// *************************************************************************** *
// *                                                                           *
// * Description:         CANDB File                                           *
// * Generated at:        2023-01-05 13:51                                     *
// * System:              FLRsystem_MAIN_26                                    *
// * Network:             FLR1CAN                                              *
// *                                                                           *
// *************************************************************************** *
VERSION "FLR1CAN"

NS_ :

BS_ :

BU_ :  FLR FLRdpHPA FLRdpHPB

BO_ 1794 Flr1canTimeSyncFr01 : 8 FLRdpHPA

BO_ 512 FlrdpFlr1canFr02 : 48 FLRdpHPA
 SG_ VehicleMotionState_UB : 280|1@0+ (1,0) [0|1] "" FLR
 SG_ VehicleMotionStateAcceleroMeterLateral : 24|15@1+ (0.0085,-138.992) [-138.992|139.00050000000002] "m/s^2" FLR
 SG_ VehicleMotionStateAccelerometerLateralQuality : 232|3@1+ (1,0) [0|7] "" FLR
 SG_ VehicleMotionStateAccelerometerLongitudinal : 40|15@1+ (0.0085,-138.992) [-138.992|139.00050000000002] "m/s^2" FLR
 SG_ VehicleMotionStateAccelerometerLongitudinalQuality : 235|3@1+ (1,0) [0|7] "" FLR
 SG_ VehicleMotionStateAccelerometerVertical : 56|15@1+ (0.0085,-138.992) [-138.992|139.00050000000002] "m/s^2" FLR
 SG_ VehicleMotionStateAccelerometerVerticalQuality : 240|3@1+ (1,0) [0|7] "" FLR
 SG_ VehicleMotionStateAngularVelocityRoll : 72|16@1+ (0.000159791,-5.236031488) [-5.236031488|5.235871697] "rad/s" FLR
 SG_ VehicleMotionStateAngularVelocityRollQuality : 243|3@1+ (1,0) [0|7] "" FLR
 SG_ VehicleMotionStateAngularVelocityYaw : 104|16@1+ (0.000159791,-5.236031488) [-5.236031488|5.235871697] "rad/s" FLR
 SG_ VehicleMotionStateAngularVelocityYawQuality : 248|3@1+ (1,0) [0|7] "" FLR
 SG_ VehicleMotionStateCounter : 16|8@1+ (1.0,0.0) [0.0|255.0] "Unitless" FLR
 SG_ VehicleMotionStateCRC : 0|16@1+ (1.0,0.0) [0.0|65535.0] "Unitless" FLR
 SG_ VehicleMotionStateMovingDirection : 251|3@1+ (1,0) [0|7] "" FLR
 SG_ VehicleMotionStateMovingDirectionQuality : 256|3@1+ (1,0) [0|7] "" FLR
 SG_ VehicleMotionStateVelocityLongitudinal : 152|13@1- (0.02,0.0) [-81.9|81.9] "m/s" FLR
 SG_ VehicleMotionStateVelocityLongitudinalQuality : 128|3@1+ (1,0) [0|7] "" FLR
 SG_ VehicleMotionStateWheelAngle : 136|15@1+ (0.00005249,-0.85) [-0.85|0.8500461200000001] "rad" FLR
 SG_ VehicleMotionStateWheelAngleQuality : 131|3@1+ (1,0) [0|7] "" FLR
 SG_ VehicleMotionStateWheelAngularVelocityFrontLeft : 168|16@1+ (0.0078125,-255.0) [-255.0|255.0] "rad/s" FLR
 SG_ VehicleMotionStateWheelAngularVelocityFrontLeftQuality : 264|3@1+ (1,0) [0|7] "" FLR
 SG_ VehicleMotionStateWheelAngularVelocityFrontRight : 184|16@1+ (0.0078125,-255.0) [-255.0|255.0] "rad/s" FLR
 SG_ VehicleMotionStateWheelAngularVelocityFrontRightQuality : 267|3@1+ (1,0) [0|7] "" FLR
 SG_ VehicleMotionStateWheelAngularVelocityRearLeft : 200|16@1+ (0.0078125,-255.0) [-255.0|255.0] "rad/s" FLR
 SG_ VehicleMotionStateWheelAngularVelocityRearLeftQuality : 272|3@1+ (1,0) [0|7] "" FLR
 SG_ VehicleMotionStateWheelAngularVelocityRearRight : 216|16@1+ (0.0078125,-255.0) [-255.0|255.0] "rad/s" FLR
 SG_ VehicleMotionStateWheelAngularVelocityRearRightQuality : 275|3@1+ (1,0) [0|7] "" FLR

BO_ 528 FlrdpFlr1canFr03 : 12 FLRdpHPA
 SG_ CarConfig_UB : 72|1@0+ (1,0) [0|1] "" FLR
 SG_ CarConfigCounter : 16|8@1+ (1.0,0.0) [0.0|255.0] "Unitless" FLR
 SG_ CarConfigCRC : 0|16@1+ (1.0,0.0) [0.0|65535.0] "Unitless" FLR
 SG_ CarConfigPropulsionType : 24|2@1+ (1,0) [0|3] "" FLR
 SG_ CarConfigVehicleTyp : 27|8@1+ (1,0) [0|255] "" FLR
 SG_ PowerModeFLR_UB : 73|1@0+ (1,0) [0|1] "" FLR
 SG_ PowerModeFLRCounter : 56|8@1+ (1.0,0.0) [0.0|255.0] "Unitless" FLR
 SG_ PowerModeFLRCRC : 40|16@1+ (1.0,0.0) [0.0|65535.0] "Unitless" FLR
 SG_ PowerModeFLRRdrActvnReq : 64|1@1+ (1,0) [0|1] "" FLR
 SG_ PowerModeFLRRdrPwrlossNoti : 65|1@1+ (1,0) [0|1] "" FLR

BO_ 544 FlrdpFlr1canFr04 : 32 FLRdpHPA
 SG_ GlobalSnapShotRdr_UB : 128|1@0+ (1,0) [0|1] "" FLR
 SG_ GlobalSnapShotRdrCounter : 16|8@1+ (1.0,0.0) [0.0|255.0] "Unitless" FLR
 SG_ GlobalSnapShotRdrCRC : 0|16@1+ (1.0,0.0) [0.0|65535.0] "Unitless" FLR
 SG_ GlobalSnapShotRdrGlobalRealTimeRdr : 24|32@1+ (1.0,0.0) [0.0|4294967295.0] "s" FLR
 SG_ GlobalSnapShotRdrOutsideTemperatureRdr : 56|16@1- (0.1,0.0) [-3276.8|3276.7000000000003] "degC" FLR
 SG_ GlobalSnapShotRdrTotalDistanceRdr : 72|32@1+ (1.0,0.0) [0.0|4294967295.0] "km" FLR
 SG_ GlobalSnapShotRdrUsageModeRdr : 104|8@1+ (1.0,0.0) [0.0|255.0] "Unitless" FLR
 SG_ GlobalSnapShotRdrVehicleBatteryVoltageRdr : 112|8@1+ (0.25,0.0) [0.0|63.75] "Volt" FLR
 SG_ GlobalSnapShotRdrVehicleSpeedRdr : 120|8@1+ (1.0,0.0) [0.0|255.0] "Km/h" FLR

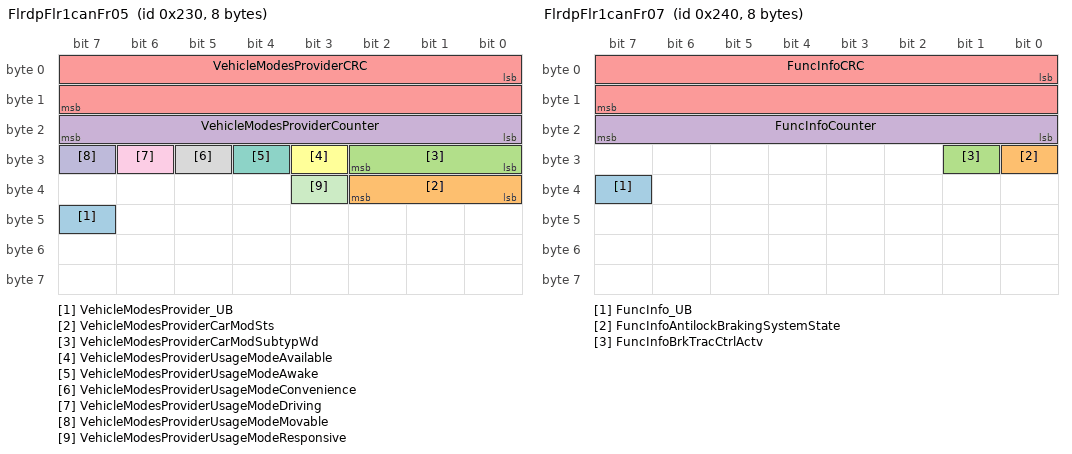
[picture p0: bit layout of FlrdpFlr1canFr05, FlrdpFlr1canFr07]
BO_ 560 FlrdpFlr1canFr05 : 8 FLRdpHPA
 SG_ VehicleModesProvider_UB : 47|1@0+ (1,0) [0|1] "" FLR
 SG_ VehicleModesProviderCarModSts : 32|3@1+ (1,0) [0|7] "" FLR
 SG_ VehicleModesProviderCarModSubtypWd : 24|3@1+ (1,0) [0|7] "" FLR
 SG_ VehicleModesProviderCounter : 16|8@1+ (1.0,0.0) [0.0|255.0] "Unitless" FLR
 SG_ VehicleModesProviderCRC : 0|16@1+ (1.0,0.0) [0.0|65535.0] "Unitless" FLR
 SG_ VehicleModesProviderUsageModeAvailable : 27|1@1+ (1,0) [0|1] "" FLR
 SG_ VehicleModesProviderUsageModeAwake : 28|1@1+ (1,0) [0|1] "" FLR
 SG_ VehicleModesProviderUsageModeConvenience : 29|1@1+ (1,0) [0|1] "" FLR
 SG_ VehicleModesProviderUsageModeDriving : 30|1@1+ (1,0) [0|1] "" FLR
 SG_ VehicleModesProviderUsageModeMovable : 31|1@1+ (1,0) [0|1] "" FLR
 SG_ VehicleModesProviderUsageModeResponsive : 35|1@1+ (1,0) [0|1] "" FLR

BO_ 576 FlrdpFlr1canFr07 : 8 FLRdpHPA
 SG_ FuncInfo_UB : 39|1@0+ (1,0) [0|1] "" FLR
 SG_ FuncInfoAntilockBrakingSystemState : 24|1@1+ (1,0) [0|1] "" FLR
 SG_ FuncInfoBrkTracCtrlActv : 25|1@1+ (1,0) [0|1] "" FLR
 SG_ FuncInfoCounter : 16|8@1+ (1.0,0.0) [0.0|255.0] "Unitless" FLR
 SG_ FuncInfoCRC : 0|16@1+ (1.0,0.0) [0.0|65535.0] "Unitless" FLR

BO_ 2047 FlrdpToAllUdsDiagRequestFrame : 64 FLRdpHPA
 SG_ FlrdpToAllUdsFlrCanNPdu : 7|512@0+ (1,0) [0|0] "" FLR

BO_ 1873 FlrdpToFlrUdsDiagRequestFrame : 64 FLRdpHPA
 SG_ FlrdpToFlrUdsFlrCanNPdu : 7|512@0+ (1,0) [0|0] "" FLR

BO_ 80 FlrFlr1canFr01 : 64 FLR
 SG_ FLR2RdrDetn000To004_UB : 359|1@0+ (1,0) [0|1] "" FLRdpHPA,FLRdpHPB
 SG_ FLR2RdrDetn000To004AziAng0 : 32|9@1+ (0.0035,-0.87266) [-0.87266|0.91584] "rad" FLRdpHPA,FLRdpHPB
 SG_ FLR2RdrDetn000To004AziAng1 : 96|9@1+ (0.0035,-0.87266) [-0.87266|0.91584] "rad" FLRdpHPA,FLRdpHPB
 SG_ FLR2RdrDetn000To004AziAng2 : 160|9@1+ (0.0035,-0.87266) [-0.87266|0.91584] "rad" FLRdpHPA,FLRdpHPB
 SG_ FLR2RdrDetn000To004AziAng3 : 224|9@1+ (0.0035,-0.87266) [-0.87266|0.91584] "rad" FLRdpHPA,FLRdpHPB
 SG_ FLR2RdrDetn000To004AziAng4 : 288|9@1+ (0.0035,-0.87266) [-0.87266|0.91584] "rad" FLRdpHPA,FLRdpHPB
 SG_ FLR2RdrDetn000To004Counter : 16|8@1+ (1.0,0.0) [0.0|255.0] "Unitless" FLRdpHPA,FLRdpHPB
 SG_ FLR2RdrDetn000To004CRC : 0|16@1+ (1.0,0.0) [0.0|65535.0] "Unitless" FLRdpHPA,FLRdpHPB
 SG_ FLR2RdrDetn000To004DynPrpty0 : 93|1@1+ (1.0,0.0) [0.0|1.0] "Unitless" FLRdpHPA,FLRdpHPB
 SG_ FLR2RdrDetn000To004DynPrpty1 : 157|1@1+ (1.0,0.0) [0.0|1.0] "Unitless" FLRdpHPA,FLRdpHPB
 SG_ FLR2RdrDetn000To004DynPrpty2 : 221|1@1+ (1.0,0.0) [0.0|1.0] "Unitless" FLRdpHPA,FLRdpHPB
 SG_ FLR2RdrDetn000To004DynPrpty3 : 285|1@1+ (1.0,0.0) [0.0|1.0] "Unitless" FLRdpHPA,FLRdpHPB
 SG_ FLR2RdrDetn000To004DynPrpty4 : 349|1@1+ (1.0,0.0) [0.0|1.0] "Unitless" FLRdpHPA,FLRdpHPB
 SG_ FLR2RdrDetn000To004EleAng0 : 64|8@1+ (0.002,0.0) [0.0|0.5] "rad" FLRdpHPA,FLRdpHPB
 SG_ FLR2RdrDetn000To004EleAng1 : 128|8@1+ (0.002,0.0) [0.0|0.5] "rad" FLRdpHPA,FLRdpHPB
 SG_ FLR2RdrDetn000To004EleAng2 : 192|8@1+ (0.002,0.0) [0.0|0.5] "rad" FLRdpHPA,FLRdpHPB
 SG_ FLR2RdrDetn000To004EleAng3 : 256|8@1+ (0.002,0.0) [0.0|0.5] "rad" FLRdpHPA,FLRdpHPB
 SG_ FLR2RdrDetn000To004EleAng4 : 320|8@1+ (0.002,0.0) [0.0|0.5] "rad" FLRdpHPA,FLRdpHPB
 SG_ FLR2RdrDetn000To004Mode0 : 60|2@1+ (1,0) [0|3] "" FLRdpHPA,FLRdpHPB
 SG_ FLR2RdrDetn000To004Mode1 : 124|2@1+ (1,0) [0|3] "" FLRdpHPA,FLRdpHPB
 SG_ FLR2RdrDetn000To004Mode2 : 188|2@1+ (1,0) [0|3] "" FLRdpHPA,FLRdpHPB
 SG_ FLR2RdrDetn000To004Mode3 : 252|2@1+ (1,0) [0|3] "" FLRdpHPA,FLRdpHPB
 SG_ FLR2RdrDetn000To004Mode4 : 316|2@1+ (1,0) [0|3] "" FLRdpHPA,FLRdpHPB
 SG_ FLR2RdrDetn000To004Quality0 : 62|2@1+ (1,0) [0|3] "" FLRdpHPA,FLRdpHPB
 SG_ FLR2RdrDetn000To004Quality1 : 126|2@1+ (1,0) [0|3] "" FLRdpHPA,FLRdpHPB
 SG_ FLR2RdrDetn000To004Quality2 : 190|2@1+ (1,0) [0|3] "" FLRdpHPA,FLRdpHPB
 SG_ FLR2RdrDetn000To004Quality3 : 254|2@1+ (1,0) [0|3] "" FLRdpHPA,FLRdpHPB
 SG_ FLR2RdrDetn000To004Quality4 : 318|2@1+ (1,0) [0|3] "" FLRdpHPA,FLRdpHPB
 SG_ FLR2RdrDetn000To004Range0 : 48|12@1+ (0.1,0.4) [0.4|300.0] "m" FLRdpHPA,FLRdpHPB
 SG_ FLR2RdrDetn000To004Range1 : 112|12@1+ (0.1,0.4) [0.4|300.0] "m" FLRdpHPA,FLRdpHPB
 SG_ FLR2RdrDetn000To004Range2 : 176|12@1+ (0.1,0.4) [0.4|300.0] "m" FLRdpHPA,FLRdpHPB
 SG_ FLR2RdrDetn000To004Range3 : 240|12@1+ (0.1,0.4) [0.4|300.0] "m" FLRdpHPA,FLRdpHPB
 SG_ FLR2RdrDetn000To004Range4 : 304|12@1+ (0.1,0.4) [0.4|300.0] "m" FLRdpHPA,FLRdpHPB
 SG_ FLR2RdrDetn000To004RCS0 : 83|10@1+ (0.2,-100.0) [-100.0|70.0] "dBsm" FLRdpHPA,FLRdpHPB
 SG_ FLR2RdrDetn000To004RCS1 : 147|10@1+ (0.2,-100.0) [-100.0|70.0] "dBsm" FLRdpHPA,FLRdpHPB
 SG_ FLR2RdrDetn000To004RCS2 : 211|10@1+ (0.2,-100.0) [-100.0|70.0] "dBsm" FLRdpHPA,FLRdpHPB
 SG_ FLR2RdrDetn000To004RCS3 : 275|10@1+ (0.2,-100.0) [-100.0|70.0] "dBsm" FLRdpHPA,FLRdpHPB
 SG_ FLR2RdrDetn000To004RCS4 : 339|10@1+ (0.2,-100.0) [-100.0|70.0] "dBsm" FLRdpHPA,FLRdpHPB
 SG_ FLR2RdrDetn000To004RngRt0 : 72|11@1+ (0.1,-111.11) [-111.11|55.59000000000002] "m/s" FLRdpHPA,FLRdpHPB
 SG_ FLR2RdrDetn000To004RngRt1 : 136|11@1+ (0.1,-111.11) [-111.11|55.59000000000002] "m/s" FLRdpHPA,FLRdpHPB
 SG_ FLR2RdrDetn000To004RngRt2 : 200|11@1+ (0.1,-111.11) [-111.11|55.59000000000002] "m/s" FLRdpHPA,FLRdpHPB
 SG_ FLR2RdrDetn000To004RngRt3 : 264|11@1+ (0.1,-111.11) [-111.11|55.59000000000002] "m/s" FLRdpHPA,FLRdpHPB
 SG_ FLR2RdrDetn000To004RngRt4 : 328|11@1+ (0.1,-111.11) [-111.11|55.59000000000002] "m/s" FLRdpHPA,FLRdpHPB
 SG_ FLR2RdrDetn000To004ScanID : 24|8@1+ (1.0,0.0) [0.0|255.0] "Unitless" FLRdpHPA,FLRdpHPB
 SG_ FLR2RdrDetn000To004SNR0 : 41|7@1+ (0.5,0.0) [0.0|63.5] "dB" FLRdpHPA,FLRdpHPB
 SG_ FLR2RdrDetn000To004SNR1 : 105|7@1+ (0.5,0.0) [0.0|63.5] "dB" FLRdpHPA,FLRdpHPB
 SG_ FLR2RdrDetn000To004SNR2 : 169|7@1+ (0.5,0.0) [0.0|63.5] "dB" FLRdpHPA,FLRdpHPB
 SG_ FLR2RdrDetn000To004SNR3 : 233|7@1+ (0.5,0.0) [0.0|63.5] "dB" FLRdpHPA,FLRdpHPB
 SG_ FLR2RdrDetn000To004SNR4 : 297|7@1+ (0.5,0.0) [0.0|63.5] "dB" FLRdpHPA,FLRdpHPB

BO_ 83 FlrFlr1canFr02 : 64 FLR
 SG_ FLR2RdrDetn005To009_UB : 359|1@0+ (1,0) [0|1] "" FLRdpHPA,FLRdpHPB
 SG_ FLR2RdrDetn005To009AziAng0 : 32|9@1+ (0.0035,-0.87266) [-0.87266|0.91584] "rad" FLRdpHPA,FLRdpHPB
 SG_ FLR2RdrDetn005To009AziAng1 : 96|9@1+ (0.0035,-0.87266) [-0.87266|0.91584] "rad" FLRdpHPA,FLRdpHPB
 SG_ FLR2RdrDetn005To009AziAng2 : 160|9@1+ (0.0035,-0.87266) [-0.87266|0.91584] "rad" FLRdpHPA,FLRdpHPB
 SG_ FLR2RdrDetn005To009AziAng3 : 224|9@1+ (0.0035,-0.87266) [-0.87266|0.91584] "rad" FLRdpHPA,FLRdpHPB
 SG_ FLR2RdrDetn005To009AziAng4 : 288|9@1+ (0.0035,-0.87266) [-0.87266|0.91584] "rad" FLRdpHPA,FLRdpHPB
 SG_ FLR2RdrDetn005To009Counter : 16|8@1+ (1.0,0.0) [0.0|255.0] "Unitless" FLRdpHPA,FLRdpHPB
 SG_ FLR2RdrDetn005To009CRC : 0|16@1+ (1.0,0.0) [0.0|65535.0] "Unitless" FLRdpHPA,FLRdpHPB
 SG_ FLR2RdrDetn005To009DynPrpty0 : 93|1@1+ (1.0,0.0) [0.0|1.0] "Unitless" FLRdpHPA,FLRdpHPB
 SG_ FLR2RdrDetn005To009DynPrpty1 : 157|1@1+ (1.0,0.0) [0.0|1.0] "Unitless" FLRdpHPA,FLRdpHPB
 SG_ FLR2RdrDetn005To009DynPrpty2 : 221|1@1+ (1.0,0.0) [0.0|1.0] "Unitless" FLRdpHPA,FLRdpHPB
 SG_ FLR2RdrDetn005To009DynPrpty3 : 285|1@1+ (1.0,0.0) [0.0|1.0] "Unitless" FLRdpHPA,FLRdpHPB
 SG_ FLR2RdrDetn005To009DynPrpty4 : 349|1@1+ (1.0,0.0) [0.0|1.0] "Unitless" FLRdpHPA,FLRdpHPB
 SG_ FLR2RdrDetn005To009EleAng0 : 64|8@1+ (0.002,0.0) [0.0|0.5] "rad" FLRdpHPA,FLRdpHPB
 SG_ FLR2RdrDetn005To009EleAng1 : 128|8@1+ (0.002,0.0) [0.0|0.5] "rad" FLRdpHPA,FLRdpHPB
 SG_ FLR2RdrDetn005To009EleAng2 : 192|8@1+ (0.002,0.0) [0.0|0.5] "rad" FLRdpHPA,FLRdpHPB
 SG_ FLR2RdrDetn005To009EleAng3 : 256|8@1+ (0.002,0.0) [0.0|0.5] "rad" FLRdpHPA,FLRdpHPB
 SG_ FLR2RdrDetn005To009EleAng4 : 320|8@1+ (0.002,0.0) [0.0|0.5] "rad" FLRdpHPA,FLRdpHPB
 SG_ FLR2RdrDetn005To009Mode0 : 60|2@1+ (1,0) [0|3] "" FLRdpHPA,FLRdpHPB
 SG_ FLR2RdrDetn005To009Mode1 : 124|2@1+ (1,0) [0|3] "" FLRdpHPA,FLRdpHPB
 SG_ FLR2RdrDetn005To009Mode2 : 188|2@1+ (1,0) [0|3] "" FLRdpHPA,FLRdpHPB
 SG_ FLR2RdrDetn005To009Mode3 : 252|2@1+ (1,0) [0|3] "" FLRdpHPA,FLRdpHPB
 SG_ FLR2RdrDetn005To009Mode4 : 316|2@1+ (1,0) [0|3] "" FLRdpHPA,FLRdpHPB
 SG_ FLR2RdrDetn005To009Quality0 : 62|2@1+ (1,0) [0|3] "" FLRdpHPA,FLRdpHPB
 SG_ FLR2RdrDetn005To009Quality1 : 126|2@1+ (1,0) [0|3] "" FLRdpHPA,FLRdpHPB
 SG_ FLR2RdrDetn005To009Quality2 : 190|2@1+ (1,0) [0|3] "" FLRdpHPA,FLRdpHPB
 SG_ FLR2RdrDetn005To009Quality3 : 254|2@1+ (1,0) [0|3] "" FLRdpHPA,FLRdpHPB
 SG_ FLR2RdrDetn005To009Quality4 : 318|2@1+ (1,0) [0|3] "" FLRdpHPA,FLRdpHPB
 SG_ FLR2RdrDetn005To009Range0 : 48|12@1+ (0.1,0.4) [0.4|300.0] "m" FLRdpHPA,FLRdpHPB
 SG_ FLR2RdrDetn005To009Range1 : 112|12@1+ (0.1,0.4) [0.4|300.0] "m" FLRdpHPA,FLRdpHPB
 SG_ FLR2RdrDetn005To009Range2 : 176|12@1+ (0.1,0.4) [0.4|300.0] "m" FLRdpHPA,FLRdpHPB
 SG_ FLR2RdrDetn005To009Range3 : 240|12@1+ (0.1,0.4) [0.4|300.0] "m" FLRdpHPA,FLRdpHPB
 SG_ FLR2RdrDetn005To009Range4 : 304|12@1+ (0.1,0.4) [0.4|300.0] "m" FLRdpHPA,FLRdpHPB
 SG_ FLR2RdrDetn005To009RCS0 : 83|10@1+ (0.2,-100.0) [-100.0|70.0] "dBsm" FLRdpHPA,FLRdpHPB
 SG_ FLR2RdrDetn005To009RCS1 : 147|10@1+ (0.2,-100.0) [-100.0|70.0] "dBsm" FLRdpHPA,FLRdpHPB
 SG_ FLR2RdrDetn005To009RCS2 : 211|10@1+ (0.2,-100.0) [-100.0|70.0] "dBsm" FLRdpHPA,FLRdpHPB
 SG_ FLR2RdrDetn005To009RCS3 : 275|10@1+ (0.2,-100.0) [-100.0|70.0] "dBsm" FLRdpHPA,FLRdpHPB
 SG_ FLR2RdrDetn005To009RCS4 : 339|10@1+ (0.2,-100.0) [-100.0|70.0] "dBsm" FLRdpHPA,FLRdpHPB
 SG_ FLR2RdrDetn005To009RngRt0 : 72|11@1+ (0.1,-111.11) [-111.11|55.59000000000002] "m/s" FLRdpHPA,FLRdpHPB
 SG_ FLR2RdrDetn005To009RngRt1 : 136|11@1+ (0.1,-111.11) [-111.11|55.59000000000002] "m/s" FLRdpHPA,FLRdpHPB
 SG_ FLR2RdrDetn005To009RngRt2 : 200|11@1+ (0.1,-111.11) [-111.11|55.59000000000002] "m/s" FLRdpHPA,FLRdpHPB
 SG_ FLR2RdrDetn005To009RngRt3 : 264|11@1+ (0.1,-111.11) [-111.11|55.59000000000002] "m/s" FLRdpHPA,FLRdpHPB
 SG_ FLR2RdrDetn005To009RngRt4 : 328|11@1+ (0.1,-111.11) [-111.11|55.59000000000002] "m/s" FLRdpHPA,FLRdpHPB
 SG_ FLR2RdrDetn005To009ScanID : 24|8@1+ (1.0,0.0) [0.0|255.0] "Unitless" FLRdpHPA,FLRdpHPB
 SG_ FLR2RdrDetn005To009SNR0 : 41|7@1+ (0.5,0.0) [0.0|63.5] "dB" FLRdpHPA,FLRdpHPB
 SG_ FLR2RdrDetn005To009SNR1 : 105|7@1+ (0.5,0.0) [0.0|63.5] "dB" FLRdpHPA,FLRdpHPB
 SG_ FLR2RdrDetn005To009SNR2 : 169|7@1+ (0.5,0.0) [0.0|63.5] "dB" FLRdpHPA,FLRdpHPB
 SG_ FLR2RdrDetn005To009SNR3 : 233|7@1+ (0.5,0.0) [0.0|63.5] "dB" FLRdpHPA,FLRdpHPB
 SG_ FLR2RdrDetn005To009SNR4 : 297|7@1+ (0.5,0.0) [0.0|63.5] "dB" FLRdpHPA,FLRdpHPB

BO_ 86 FlrFlr1canFr03 : 64 FLR
 SG_ FLR2RdrDetn010To014_UB : 359|1@0+ (1,0) [0|1] "" FLRdpHPA,FLRdpHPB
 SG_ FLR2RdrDetn010To014AziAng0 : 32|9@1+ (0.0035,-0.87266) [-0.87266|0.91584] "rad" FLRdpHPA,FLRdpHPB
 SG_ FLR2RdrDetn010To014AziAng1 : 96|9@1+ (0.0035,-0.87266) [-0.87266|0.91584] "rad" FLRdpHPA,FLRdpHPB
 SG_ FLR2RdrDetn010To014AziAng2 : 160|9@1+ (0.0035,-0.87266) [-0.87266|0.91584] "rad" FLRdpHPA,FLRdpHPB
 SG_ FLR2RdrDetn010To014AziAng3 : 224|9@1+ (0.0035,-0.87266) [-0.87266|0.91584] "rad" FLRdpHPA,FLRdpHPB
 SG_ FLR2RdrDetn010To014AziAng4 : 288|9@1+ (0.0035,-0.87266) [-0.87266|0.91584] "rad" FLRdpHPA,FLRdpHPB
 SG_ FLR2RdrDetn010To014Counter : 16|8@1+ (1.0,0.0) [0.0|255.0] "Unitless" FLRdpHPA,FLRdpHPB
 SG_ FLR2RdrDetn010To014CRC : 0|16@1+ (1.0,0.0) [0.0|65535.0] "Unitless" FLRdpHPA,FLRdpHPB
 SG_ FLR2RdrDetn010To014DynPrpty0 : 93|1@1+ (1.0,0.0) [0.0|1.0] "Unitless" FLRdpHPA,FLRdpHPB
 SG_ FLR2RdrDetn010To014DynPrpty1 : 157|1@1+ (1.0,0.0) [0.0|1.0] "Unitless" FLRdpHPA,FLRdpHPB
 SG_ FLR2RdrDetn010To014DynPrpty2 : 221|1@1+ (1.0,0.0) [0.0|1.0] "Unitless" FLRdpHPA,FLRdpHPB
 SG_ FLR2RdrDetn010To014DynPrpty3 : 285|1@1+ (1.0,0.0) [0.0|1.0] "Unitless" FLRdpHPA,FLRdpHPB
 SG_ FLR2RdrDetn010To014DynPrpty4 : 349|1@1+ (1.0,0.0) [0.0|1.0] "Unitless" FLRdpHPA,FLRdpHPB
 SG_ FLR2RdrDetn010To014EleAng0 : 64|8@1+ (0.002,0.0) [0.0|0.5] "rad" FLRdpHPA,FLRdpHPB
 SG_ FLR2RdrDetn010To014EleAng1 : 128|8@1+ (0.002,0.0) [0.0|0.5] "rad" FLRdpHPA,FLRdpHPB
 SG_ FLR2RdrDetn010To014EleAng2 : 192|8@1+ (0.002,0.0) [0.0|0.5] "rad" FLRdpHPA,FLRdpHPB
 SG_ FLR2RdrDetn010To014EleAng3 : 256|8@1+ (0.002,0.0) [0.0|0.5] "rad" FLRdpHPA,FLRdpHPB
 SG_ FLR2RdrDetn010To014EleAng4 : 320|8@1+ (0.002,0.0) [0.0|0.5] "rad" FLRdpHPA,FLRdpHPB
 SG_ FLR2RdrDetn010To014Mode0 : 60|2@1+ (1,0) [0|3] "" FLRdpHPA,FLRdpHPB
 SG_ FLR2RdrDetn010To014Mode1 : 124|2@1+ (1,0) [0|3] "" FLRdpHPA,FLRdpHPB
 SG_ FLR2RdrDetn010To014Mode2 : 188|2@1+ (1,0) [0|3] "" FLRdpHPA,FLRdpHPB
 SG_ FLR2RdrDetn010To014Mode3 : 252|2@1+ (1,0) [0|3] "" FLRdpHPA,FLRdpHPB
 SG_ FLR2RdrDetn010To014Mode4 : 316|2@1+ (1,0) [0|3] "" FLRdpHPA,FLRdpHPB
 SG_ FLR2RdrDetn010To014Quality0 : 62|2@1+ (1,0) [0|3] "" FLRdpHPA,FLRdpHPB
 SG_ FLR2RdrDetn010To014Quality1 : 126|2@1+ (1,0) [0|3] "" FLRdpHPA,FLRdpHPB
 SG_ FLR2RdrDetn010To014Quality2 : 190|2@1+ (1,0) [0|3] "" FLRdpHPA,FLRdpHPB
 SG_ FLR2RdrDetn010To014Quality3 : 254|2@1+ (1,0) [0|3] "" FLRdpHPA,FLRdpHPB
 SG_ FLR2RdrDetn010To014Quality4 : 318|2@1+ (1,0) [0|3] "" FLRdpHPA,FLRdpHPB
 SG_ FLR2RdrDetn010To014Range0 : 48|12@1+ (0.1,0.4) [0.4|300.0] "m" FLRdpHPA,FLRdpHPB
 SG_ FLR2RdrDetn010To014Range1 : 112|12@1+ (0.1,0.4) [0.4|300.0] "m" FLRdpHPA,FLRdpHPB
 SG_ FLR2RdrDetn010To014Range2 : 176|12@1+ (0.1,0.4) [0.4|300.0] "m" FLRdpHPA,FLRdpHPB
 SG_ FLR2RdrDetn010To014Range3 : 240|12@1+ (0.1,0.4) [0.4|300.0] "m" FLRdpHPA,FLRdpHPB
 SG_ FLR2RdrDetn010To014Range4 : 304|12@1+ (0.1,0.4) [0.4|300.0] "m" FLRdpHPA,FLRdpHPB
 SG_ FLR2RdrDetn010To014RCS0 : 83|10@1+ (0.2,-100.0) [-100.0|70.0] "dBsm" FLRdpHPA,FLRdpHPB
 SG_ FLR2RdrDetn010To014RCS1 : 147|10@1+ (0.2,-100.0) [-100.0|70.0] "dBsm" FLRdpHPA,FLRdpHPB
 SG_ FLR2RdrDetn010To014RCS2 : 211|10@1+ (0.2,-100.0) [-100.0|70.0] "dBsm" FLRdpHPA,FLRdpHPB
 SG_ FLR2RdrDetn010To014RCS3 : 275|10@1+ (0.2,-100.0) [-100.0|70.0] "dBsm" FLRdpHPA,FLRdpHPB
 SG_ FLR2RdrDetn010To014RCS4 : 339|10@1+ (0.2,-100.0) [-100.0|70.0] "dBsm" FLRdpHPA,FLRdpHPB
 SG_ FLR2RdrDetn010To014RngRt0 : 72|11@1+ (0.1,-111.11) [-111.11|55.59000000000002] "m/s" FLRdpHPA,FLRdpHPB
 SG_ FLR2RdrDetn010To014RngRt1 : 136|11@1+ (0.1,-111.11) [-111.11|55.59000000000002] "m/s" FLRdpHPA,FLRdpHPB
 SG_ FLR2RdrDetn010To014RngRt2 : 200|11@1+ (0.1,-111.11) [-111.11|55.59000000000002] "m/s" FLRdpHPA,FLRdpHPB
 SG_ FLR2RdrDetn010To014RngRt3 : 264|11@1+ (0.1,-111.11) [-111.11|55.59000000000002] "m/s" FLRdpHPA,FLRdpHPB
 SG_ FLR2RdrDetn010To014RngRt4 : 328|11@1+ (0.1,-111.11) [-111.11|55.59000000000002] "m/s" FLRdpHPA,FLRdpHPB
 SG_ FLR2RdrDetn010To014ScanID : 24|8@1+ (1.0,0.0) [0.0|255.0] "Unitless" FLRdpHPA,FLRdpHPB
 SG_ FLR2RdrDetn010To014SNR0 : 41|7@1+ (0.5,0.0) [0.0|63.5] "dB" FLRdpHPA,FLRdpHPB
 SG_ FLR2RdrDetn010To014SNR1 : 105|7@1+ (0.5,0.0) [0.0|63.5] "dB" FLRdpHPA,FLRdpHPB
 SG_ FLR2RdrDetn010To014SNR2 : 169|7@1+ (0.5,0.0) [0.0|63.5] "dB" FLRdpHPA,FLRdpHPB
 SG_ FLR2RdrDetn010To014SNR3 : 233|7@1+ (0.5,0.0) [0.0|63.5] "dB" FLRdpHPA,FLRdpHPB
 SG_ FLR2RdrDetn010To014SNR4 : 297|7@1+ (0.5,0.0) [0.0|63.5] "dB" FLRdpHPA,FLRdpHPB

BO_ 89 FlrFlr1canFr04 : 64 FLR
 SG_ FLR2RdrDetn015To019_UB : 359|1@0+ (1,0) [0|1] "" FLRdpHPA,FLRdpHPB
 SG_ FLR2RdrDetn015To019AziAng0 : 32|9@1+ (0.0035,-0.87266) [-0.87266|0.91584] "rad" FLRdpHPA,FLRdpHPB
 SG_ FLR2RdrDetn015To019AziAng1 : 96|9@1+ (0.0035,-0.87266) [-0.87266|0.91584] "rad" FLRdpHPA,FLRdpHPB
 SG_ FLR2RdrDetn015To019AziAng2 : 160|9@1+ (0.0035,-0.87266) [-0.87266|0.91584] "rad" FLRdpHPA,FLRdpHPB
 SG_ FLR2RdrDetn015To019AziAng3 : 224|9@1+ (0.0035,-0.87266) [-0.87266|0.91584] "rad" FLRdpHPA,FLRdpHPB
 SG_ FLR2RdrDetn015To019AziAng4 : 288|9@1+ (0.0035,-0.87266) [-0.87266|0.91584] "rad" FLRdpHPA,FLRdpHPB
 SG_ FLR2RdrDetn015To019Counter : 16|8@1+ (1.0,0.0) [0.0|255.0] "Unitless" FLRdpHPA,FLRdpHPB
 SG_ FLR2RdrDetn015To019CRC : 0|16@1+ (1.0,0.0) [0.0|65535.0] "Unitless" FLRdpHPA,FLRdpHPB
 SG_ FLR2RdrDetn015To019DynPrpty0 : 93|1@1+ (1.0,0.0) [0.0|1.0] "Unitless" FLRdpHPA,FLRdpHPB
 SG_ FLR2RdrDetn015To019DynPrpty1 : 157|1@1+ (1.0,0.0) [0.0|1.0] "Unitless" FLRdpHPA,FLRdpHPB
 SG_ FLR2RdrDetn015To019DynPrpty2 : 221|1@1+ (1.0,0.0) [0.0|1.0] "Unitless" FLRdpHPA,FLRdpHPB
 SG_ FLR2RdrDetn015To019DynPrpty3 : 285|1@1+ (1.0,0.0) [0.0|1.0] "Unitless" FLRdpHPA,FLRdpHPB
 SG_ FLR2RdrDetn015To019DynPrpty4 : 349|1@1+ (1.0,0.0) [0.0|1.0] "Unitless" FLRdpHPA,FLRdpHPB
 SG_ FLR2RdrDetn015To019EleAng0 : 64|8@1+ (0.002,0.0) [0.0|0.5] "rad" FLRdpHPA,FLRdpHPB
 SG_ FLR2RdrDetn015To019EleAng1 : 128|8@1+ (0.002,0.0) [0.0|0.5] "rad" FLRdpHPA,FLRdpHPB
 SG_ FLR2RdrDetn015To019EleAng2 : 192|8@1+ (0.002,0.0) [0.0|0.5] "rad" FLRdpHPA,FLRdpHPB
 SG_ FLR2RdrDetn015To019EleAng3 : 256|8@1+ (0.002,0.0) [0.0|0.5] "rad" FLRdpHPA,FLRdpHPB
 SG_ FLR2RdrDetn015To019EleAng4 : 320|8@1+ (0.002,0.0) [0.0|0.5] "rad" FLRdpHPA,FLRdpHPB
 SG_ FLR2RdrDetn015To019Mode0 : 60|2@1+ (1,0) [0|3] "" FLRdpHPA,FLRdpHPB
 SG_ FLR2RdrDetn015To019Mode1 : 124|2@1+ (1,0) [0|3] "" FLRdpHPA,FLRdpHPB
 SG_ FLR2RdrDetn015To019Mode2 : 188|2@1+ (1,0) [0|3] "" FLRdpHPA,FLRdpHPB
 SG_ FLR2RdrDetn015To019Mode3 : 252|2@1+ (1,0) [0|3] "" FLRdpHPA,FLRdpHPB
 SG_ FLR2RdrDetn015To019Mode4 : 316|2@1+ (1,0) [0|3] "" FLRdpHPA,FLRdpHPB
 SG_ FLR2RdrDetn015To019Quality0 : 62|2@1+ (1,0) [0|3] "" FLRdpHPA,FLRdpHPB
 SG_ FLR2RdrDetn015To019Quality1 : 126|2@1+ (1,0) [0|3] "" FLRdpHPA,FLRdpHPB
 SG_ FLR2RdrDetn015To019Quality2 : 190|2@1+ (1,0) [0|3] "" FLRdpHPA,FLRdpHPB
 SG_ FLR2RdrDetn015To019Quality3 : 254|2@1+ (1,0) [0|3] "" FLRdpHPA,FLRdpHPB
 SG_ FLR2RdrDetn015To019Quality4 : 318|2@1+ (1,0) [0|3] "" FLRdpHPA,FLRdpHPB
 SG_ FLR2RdrDetn015To019Range0 : 48|12@1+ (0.1,0.4) [0.4|300.0] "m" FLRdpHPA,FLRdpHPB
 SG_ FLR2RdrDetn015To019Range1 : 112|12@1+ (0.1,0.4) [0.4|300.0] "m" FLRdpHPA,FLRdpHPB
 SG_ FLR2RdrDetn015To019Range2 : 176|12@1+ (0.1,0.4) [0.4|300.0] "m" FLRdpHPA,FLRdpHPB
 SG_ FLR2RdrDetn015To019Range3 : 240|12@1+ (0.1,0.4) [0.4|300.0] "m" FLRdpHPA,FLRdpHPB
 SG_ FLR2RdrDetn015To019Range4 : 304|12@1+ (0.1,0.4) [0.4|300.0] "m" FLRdpHPA,FLRdpHPB
 SG_ FLR2RdrDetn015To019RCS0 : 83|10@1+ (0.2,-100.0) [-100.0|70.0] "dBsm" FLRdpHPA,FLRdpHPB
 SG_ FLR2RdrDetn015To019RCS1 : 147|10@1+ (0.2,-100.0) [-100.0|70.0] "dBsm" FLRdpHPA,FLRdpHPB
 SG_ FLR2RdrDetn015To019RCS2 : 211|10@1+ (0.2,-100.0) [-100.0|70.0] "dBsm" FLRdpHPA,FLRdpHPB
 SG_ FLR2RdrDetn015To019RCS3 : 275|10@1+ (0.2,-100.0) [-100.0|70.0] "dBsm" FLRdpHPA,FLRdpHPB
 SG_ FLR2RdrDetn015To019RCS4 : 339|10@1+ (0.2,-100.0) [-100.0|70.0] "dBsm" FLRdpHPA,FLRdpHPB
 SG_ FLR2RdrDetn015To019RngRt0 : 72|11@1+ (0.1,-111.11) [-111.11|55.59000000000002] "m/s" FLRdpHPA,FLRdpHPB
 SG_ FLR2RdrDetn015To019RngRt1 : 136|11@1+ (0.1,-111.11) [-111.11|55.59000000000002] "m/s" FLRdpHPA,FLRdpHPB
 SG_ FLR2RdrDetn015To019RngRt2 : 200|11@1+ (0.1,-111.11) [-111.11|55.59000000000002] "m/s" FLRdpHPA,FLRdpHPB
 SG_ FLR2RdrDetn015To019RngRt3 : 264|11@1+ (0.1,-111.11) [-111.11|55.59000000000002] "m/s" FLRdpHPA,FLRdpHPB
 SG_ FLR2RdrDetn015To019RngRt4 : 328|11@1+ (0.1,-111.11) [-111.11|55.59000000000002] "m/s" FLRdpHPA,FLRdpHPB
 SG_ FLR2RdrDetn015To019ScanID : 24|8@1+ (1.0,0.0) [0.0|255.0] "Unitless" FLRdpHPA,FLRdpHPB
 SG_ FLR2RdrDetn015To019SNR0 : 41|7@1+ (0.5,0.0) [0.0|63.5] "dB" FLRdpHPA,FLRdpHPB
 SG_ FLR2RdrDetn015To019SNR1 : 105|7@1+ (0.5,0.0) [0.0|63.5] "dB" FLRdpHPA,FLRdpHPB
 SG_ FLR2RdrDetn015To019SNR2 : 169|7@1+ (0.5,0.0) [0.0|63.5] "dB" FLRdpHPA,FLRdpHPB
 SG_ FLR2RdrDetn015To019SNR3 : 233|7@1+ (0.5,0.0) [0.0|63.5] "dB" FLRdpHPA,FLRdpHPB
 SG_ FLR2RdrDetn015To019SNR4 : 297|7@1+ (0.5,0.0) [0.0|63.5] "dB" FLRdpHPA,FLRdpHPB

BO_ 92 FlrFlr1canFr05 : 64 FLR
 SG_ FLR2RdrDetn020To024_UB : 359|1@0+ (1,0) [0|1] "" FLRdpHPA,FLRdpHPB
 SG_ FLR2RdrDetn020To024AziAng0 : 32|9@1+ (0.0035,-0.87266) [-0.87266|0.91584] "rad" FLRdpHPA,FLRdpHPB
 SG_ FLR2RdrDetn020To024AziAng1 : 96|9@1+ (0.0035,-0.87266) [-0.87266|0.91584] "rad" FLRdpHPA,FLRdpHPB
 SG_ FLR2RdrDetn020To024AziAng2 : 160|9@1+ (0.0035,-0.87266) [-0.87266|0.91584] "rad" FLRdpHPA,FLRdpHPB
 SG_ FLR2RdrDetn020To024AziAng3 : 224|9@1+ (0.0035,-0.87266) [-0.87266|0.91584] "rad" FLRdpHPA,FLRdpHPB
 SG_ FLR2RdrDetn020To024AziAng4 : 288|9@1+ (0.0035,-0.87266) [-0.87266|0.91584] "rad" FLRdpHPA,FLRdpHPB
 SG_ FLR2RdrDetn020To024Counter : 16|8@1+ (1.0,0.0) [0.0|255.0] "Unitless" FLRdpHPA,FLRdpHPB
 SG_ FLR2RdrDetn020To024CRC : 0|16@1+ (1.0,0.0) [0.0|65535.0] "Unitless" FLRdpHPA,FLRdpHPB
 SG_ FLR2RdrDetn020To024DynPrpty0 : 93|1@1+ (1.0,0.0) [0.0|1.0] "Unitless" FLRdpHPA,FLRdpHPB
 SG_ FLR2RdrDetn020To024DynPrpty1 : 157|1@1+ (1.0,0.0) [0.0|1.0] "Unitless" FLRdpHPA,FLRdpHPB
 SG_ FLR2RdrDetn020To024DynPrpty2 : 221|1@1+ (1.0,0.0) [0.0|1.0] "Unitless" FLRdpHPA,FLRdpHPB
 SG_ FLR2RdrDetn020To024DynPrpty3 : 285|1@1+ (1.0,0.0) [0.0|1.0] "Unitless" FLRdpHPA,FLRdpHPB
 SG_ FLR2RdrDetn020To024DynPrpty4 : 349|1@1+ (1.0,0.0) [0.0|1.0] "Unitless" FLRdpHPA,FLRdpHPB
 SG_ FLR2RdrDetn020To024EleAng0 : 64|8@1+ (0.002,0.0) [0.0|0.5] "rad" FLRdpHPA,FLRdpHPB
 SG_ FLR2RdrDetn020To024EleAng1 : 128|8@1+ (0.002,0.0) [0.0|0.5] "rad" FLRdpHPA,FLRdpHPB
 SG_ FLR2RdrDetn020To024EleAng2 : 192|8@1+ (0.002,0.0) [0.0|0.5] "rad" FLRdpHPA,FLRdpHPB
 SG_ FLR2RdrDetn020To024EleAng3 : 256|8@1+ (0.002,0.0) [0.0|0.5] "rad" FLRdpHPA,FLRdpHPB
 SG_ FLR2RdrDetn020To024EleAng4 : 320|8@1+ (0.002,0.0) [0.0|0.5] "rad" FLRdpHPA,FLRdpHPB
 SG_ FLR2RdrDetn020To024Mode0 : 60|2@1+ (1,0) [0|3] "" FLRdpHPA,FLRdpHPB
 SG_ FLR2RdrDetn020To024Mode1 : 124|2@1+ (1,0) [0|3] "" FLRdpHPA,FLRdpHPB
 SG_ FLR2RdrDetn020To024Mode2 : 188|2@1+ (1,0) [0|3] "" FLRdpHPA,FLRdpHPB
 SG_ FLR2RdrDetn020To024Mode3 : 252|2@1+ (1,0) [0|3] "" FLRdpHPA,FLRdpHPB
 SG_ FLR2RdrDetn020To024Mode4 : 316|2@1+ (1,0) [0|3] "" FLRdpHPA,FLRdpHPB
 SG_ FLR2RdrDetn020To024Quality0 : 62|2@1+ (1,0) [0|3] "" FLRdpHPA,FLRdpHPB
 SG_ FLR2RdrDetn020To024Quality1 : 126|2@1+ (1,0) [0|3] "" FLRdpHPA,FLRdpHPB
 SG_ FLR2RdrDetn020To024Quality2 : 190|2@1+ (1,0) [0|3] "" FLRdpHPA,FLRdpHPB
 SG_ FLR2RdrDetn020To024Quality3 : 254|2@1+ (1,0) [0|3] "" FLRdpHPA,FLRdpHPB
 SG_ FLR2RdrDetn020To024Quality4 : 318|2@1+ (1,0) [0|3] "" FLRdpHPA,FLRdpHPB
 SG_ FLR2RdrDetn020To024Range0 : 48|12@1+ (0.1,0.4) [0.4|300.0] "m" FLRdpHPA,FLRdpHPB
 SG_ FLR2RdrDetn020To024Range1 : 112|12@1+ (0.1,0.4) [0.4|300.0] "m" FLRdpHPA,FLRdpHPB
 SG_ FLR2RdrDetn020To024Range2 : 176|12@1+ (0.1,0.4) [0.4|300.0] "m" FLRdpHPA,FLRdpHPB
 SG_ FLR2RdrDetn020To024Range3 : 240|12@1+ (0.1,0.4) [0.4|300.0] "m" FLRdpHPA,FLRdpHPB
 SG_ FLR2RdrDetn020To024Range4 : 304|12@1+ (0.1,0.4) [0.4|300.0] "m" FLRdpHPA,FLRdpHPB
 SG_ FLR2RdrDetn020To024RCS0 : 83|10@1+ (0.2,-100.0) [-100.0|70.0] "dBsm" FLRdpHPA,FLRdpHPB
 SG_ FLR2RdrDetn020To024RCS1 : 147|10@1+ (0.2,-100.0) [-100.0|70.0] "dBsm" FLRdpHPA,FLRdpHPB
 SG_ FLR2RdrDetn020To024RCS2 : 211|10@1+ (0.2,-100.0) [-100.0|70.0] "dBsm" FLRdpHPA,FLRdpHPB
 SG_ FLR2RdrDetn020To024RCS3 : 275|10@1+ (0.2,-100.0) [-100.0|70.0] "dBsm" FLRdpHPA,FLRdpHPB
 SG_ FLR2RdrDetn020To024RCS4 : 339|10@1+ (0.2,-100.0) [-100.0|70.0] "dBsm" FLRdpHPA,FLRdpHPB
 SG_ FLR2RdrDetn020To024RngRt0 : 72|11@1+ (0.1,-111.11) [-111.11|55.59000000000002] "m/s" FLRdpHPA,FLRdpHPB
 SG_ FLR2RdrDetn020To024RngRt1 : 136|11@1+ (0.1,-111.11) [-111.11|55.59000000000002] "m/s" FLRdpHPA,FLRdpHPB
 SG_ FLR2RdrDetn020To024RngRt2 : 200|11@1+ (0.1,-111.11) [-111.11|55.59000000000002] "m/s" FLRdpHPA,FLRdpHPB
 SG_ FLR2RdrDetn020To024RngRt3 : 264|11@1+ (0.1,-111.11) [-111.11|55.59000000000002] "m/s" FLRdpHPA,FLRdpHPB
 SG_ FLR2RdrDetn020To024RngRt4 : 328|11@1+ (0.1,-111.11) [-111.11|55.59000000000002] "m/s" FLRdpHPA,FLRdpHPB
 SG_ FLR2RdrDetn020To024ScanID : 24|8@1+ (1.0,0.0) [0.0|255.0] "Unitless" FLRdpHPA,FLRdpHPB
 SG_ FLR2RdrDetn020To024SNR0 : 41|7@1+ (0.5,0.0) [0.0|63.5] "dB" FLRdpHPA,FLRdpHPB
 SG_ FLR2RdrDetn020To024SNR1 : 105|7@1+ (0.5,0.0) [0.0|63.5] "dB" FLRdpHPA,FLRdpHPB
 SG_ FLR2RdrDetn020To024SNR2 : 169|7@1+ (0.5,0.0) [0.0|63.5] "dB" FLRdpHPA,FLRdpHPB
 SG_ FLR2RdrDetn020To024SNR3 : 233|7@1+ (0.5,0.0) [0.0|63.5] "dB" FLRdpHPA,FLRdpHPB
 SG_ FLR2RdrDetn020To024SNR4 : 297|7@1+ (0.5,0.0) [0.0|63.5] "dB" FLRdpHPA,FLRdpHPB

BO_ 96 FlrFlr1canFr06 : 64 FLR
 SG_ FLR2RdrDetn025To029_UB : 359|1@0+ (1,0) [0|1] "" FLRdpHPA,FLRdpHPB
 SG_ FLR2RdrDetn025To029AziAng0 : 32|9@1+ (0.0035,-0.87266) [-0.87266|0.91584] "rad" FLRdpHPA,FLRdpHPB
 SG_ FLR2RdrDetn025To029AziAng1 : 96|9@1+ (0.0035,-0.87266) [-0.87266|0.91584] "rad" FLRdpHPA,FLRdpHPB
 SG_ FLR2RdrDetn025To029AziAng2 : 160|9@1+ (0.0035,-0.87266) [-0.87266|0.91584] "rad" FLRdpHPA,FLRdpHPB
 SG_ FLR2RdrDetn025To029AziAng3 : 224|9@1+ (0.0035,-0.87266) [-0.87266|0.91584] "rad" FLRdpHPA,FLRdpHPB
 SG_ FLR2RdrDetn025To029AziAng4 : 288|9@1+ (0.0035,-0.87266) [-0.87266|0.91584] "rad" FLRdpHPA,FLRdpHPB
 SG_ FLR2RdrDetn025To029Counter : 16|8@1+ (1.0,0.0) [0.0|255.0] "Unitless" FLRdpHPA,FLRdpHPB
 SG_ FLR2RdrDetn025To029CRC : 0|16@1+ (1.0,0.0) [0.0|65535.0] "Unitless" FLRdpHPA,FLRdpHPB
 SG_ FLR2RdrDetn025To029DynPrpty0 : 93|1@1+ (1.0,0.0) [0.0|1.0] "Unitless" FLRdpHPA,FLRdpHPB
 SG_ FLR2RdrDetn025To029DynPrpty1 : 157|1@1+ (1.0,0.0) [0.0|1.0] "Unitless" FLRdpHPA,FLRdpHPB
 SG_ FLR2RdrDetn025To029DynPrpty2 : 221|1@1+ (1.0,0.0) [0.0|1.0] "Unitless" FLRdpHPA,FLRdpHPB
 SG_ FLR2RdrDetn025To029DynPrpty3 : 285|1@1+ (1.0,0.0) [0.0|1.0] "Unitless" FLRdpHPA,FLRdpHPB
 SG_ FLR2RdrDetn025To029DynPrpty4 : 349|1@1+ (1.0,0.0) [0.0|1.0] "Unitless" FLRdpHPA,FLRdpHPB
 SG_ FLR2RdrDetn025To029EleAng0 : 64|8@1+ (0.002,0.0) [0.0|0.5] "rad" FLRdpHPA,FLRdpHPB
 SG_ FLR2RdrDetn025To029EleAng1 : 128|8@1+ (0.002,0.0) [0.0|0.5] "rad" FLRdpHPA,FLRdpHPB
 SG_ FLR2RdrDetn025To029EleAng2 : 192|8@1+ (0.002,0.0) [0.0|0.5] "rad" FLRdpHPA,FLRdpHPB
 SG_ FLR2RdrDetn025To029EleAng3 : 256|8@1+ (0.002,0.0) [0.0|0.5] "rad" FLRdpHPA,FLRdpHPB
 SG_ FLR2RdrDetn025To029EleAng4 : 320|8@1+ (0.002,0.0) [0.0|0.5] "rad" FLRdpHPA,FLRdpHPB
 SG_ FLR2RdrDetn025To029Mode0 : 60|2@1+ (1,0) [0|3] "" FLRdpHPA,FLRdpHPB
 SG_ FLR2RdrDetn025To029Mode1 : 124|2@1+ (1,0) [0|3] "" FLRdpHPA,FLRdpHPB
 SG_ FLR2RdrDetn025To029Mode2 : 188|2@1+ (1,0) [0|3] "" FLRdpHPA,FLRdpHPB
 SG_ FLR2RdrDetn025To029Mode3 : 252|2@1+ (1,0) [0|3] "" FLRdpHPA,FLRdpHPB
 SG_ FLR2RdrDetn025To029Mode4 : 316|2@1+ (1,0) [0|3] "" FLRdpHPA,FLRdpHPB
 SG_ FLR2RdrDetn025To029Quality0 : 62|2@1+ (1,0) [0|3] "" FLRdpHPA,FLRdpHPB
 SG_ FLR2RdrDetn025To029Quality1 : 126|2@1+ (1,0) [0|3] "" FLRdpHPA,FLRdpHPB
 SG_ FLR2RdrDetn025To029Quality2 : 190|2@1+ (1,0) [0|3] "" FLRdpHPA,FLRdpHPB
 SG_ FLR2RdrDetn025To029Quality3 : 254|2@1+ (1,0) [0|3] "" FLRdpHPA,FLRdpHPB
 SG_ FLR2RdrDetn025To029Quality4 : 318|2@1+ (1,0) [0|3] "" FLRdpHPA,FLRdpHPB
 SG_ FLR2RdrDetn025To029Range0 : 48|12@1+ (0.1,0.4) [0.4|300.0] "m" FLRdpHPA,FLRdpHPB
 SG_ FLR2RdrDetn025To029Range1 : 112|12@1+ (0.1,0.4) [0.4|300.0] "m" FLRdpHPA,FLRdpHPB
 SG_ FLR2RdrDetn025To029Range2 : 176|12@1+ (0.1,0.4) [0.4|300.0] "m" FLRdpHPA,FLRdpHPB
 SG_ FLR2RdrDetn025To029Range3 : 240|12@1+ (0.1,0.4) [0.4|300.0] "m" FLRdpHPA,FLRdpHPB
 SG_ FLR2RdrDetn025To029Range4 : 304|12@1+ (0.1,0.4) [0.4|300.0] "m" FLRdpHPA,FLRdpHPB
 SG_ FLR2RdrDetn025To029RCS0 : 83|10@1+ (0.2,-100.0) [-100.0|70.0] "dBsm" FLRdpHPA,FLRdpHPB
 SG_ FLR2RdrDetn025To029RCS1 : 147|10@1+ (0.2,-100.0) [-100.0|70.0] "dBsm" FLRdpHPA,FLRdpHPB
 SG_ FLR2RdrDetn025To029RCS2 : 211|10@1+ (0.2,-100.0) [-100.0|70.0] "dBsm" FLRdpHPA,FLRdpHPB
 SG_ FLR2RdrDetn025To029RCS3 : 275|10@1+ (0.2,-100.0) [-100.0|70.0] "dBsm" FLRdpHPA,FLRdpHPB
 SG_ FLR2RdrDetn025To029RCS4 : 339|10@1+ (0.2,-100.0) [-100.0|70.0] "dBsm" FLRdpHPA,FLRdpHPB
 SG_ FLR2RdrDetn025To029RngRt0 : 72|11@1+ (0.1,-111.11) [-111.11|55.59000000000002] "m/s" FLRdpHPA,FLRdpHPB
 SG_ FLR2RdrDetn025To029RngRt1 : 136|11@1+ (0.1,-111.11) [-111.11|55.59000000000002] "m/s" FLRdpHPA,FLRdpHPB
 SG_ FLR2RdrDetn025To029RngRt2 : 200|11@1+ (0.1,-111.11) [-111.11|55.59000000000002] "m/s" FLRdpHPA,FLRdpHPB
 SG_ FLR2RdrDetn025To029RngRt3 : 264|11@1+ (0.1,-111.11) [-111.11|55.59000000000002] "m/s" FLRdpHPA,FLRdpHPB
 SG_ FLR2RdrDetn025To029RngRt4 : 328|11@1+ (0.1,-111.11) [-111.11|55.59000000000002] "m/s" FLRdpHPA,FLRdpHPB
 SG_ FLR2RdrDetn025To029ScanID : 24|8@1+ (1.0,0.0) [0.0|255.0] "Unitless" FLRdpHPA,FLRdpHPB
 SG_ FLR2RdrDetn025To029SNR0 : 41|7@1+ (0.5,0.0) [0.0|63.5] "dB" FLRdpHPA,FLRdpHPB
 SG_ FLR2RdrDetn025To029SNR1 : 105|7@1+ (0.5,0.0) [0.0|63.5] "dB" FLRdpHPA,FLRdpHPB
 SG_ FLR2RdrDetn025To029SNR2 : 169|7@1+ (0.5,0.0) [0.0|63.5] "dB" FLRdpHPA,FLRdpHPB
 SG_ FLR2RdrDetn025To029SNR3 : 233|7@1+ (0.5,0.0) [0.0|63.5] "dB" FLRdpHPA,FLRdpHPB
 SG_ FLR2RdrDetn025To029SNR4 : 297|7@1+ (0.5,0.0) [0.0|63.5] "dB" FLRdpHPA,FLRdpHPB

BO_ 99 FlrFlr1canFr07 : 64 FLR
 SG_ FLR2RdrDetn030To034_UB : 359|1@0+ (1,0) [0|1] "" FLRdpHPA,FLRdpHPB
 SG_ FLR2RdrDetn030To034AziAng0 : 32|9@1+ (0.0035,-0.87266) [-0.87266|0.91584] "rad" FLRdpHPA,FLRdpHPB
 SG_ FLR2RdrDetn030To034AziAng1 : 96|9@1+ (0.0035,-0.87266) [-0.87266|0.91584] "rad" FLRdpHPA,FLRdpHPB
 SG_ FLR2RdrDetn030To034AziAng2 : 160|9@1+ (0.0035,-0.87266) [-0.87266|0.91584] "rad" FLRdpHPA,FLRdpHPB
 SG_ FLR2RdrDetn030To034AziAng3 : 224|9@1+ (0.0035,-0.87266) [-0.87266|0.91584] "rad" FLRdpHPA,FLRdpHPB
 SG_ FLR2RdrDetn030To034AziAng4 : 288|9@1+ (0.0035,-0.87266) [-0.87266|0.91584] "rad" FLRdpHPA,FLRdpHPB
 SG_ FLR2RdrDetn030To034Counter : 16|8@1+ (1.0,0.0) [0.0|255.0] "Unitless" FLRdpHPA,FLRdpHPB
 SG_ FLR2RdrDetn030To034CRC : 0|16@1+ (1.0,0.0) [0.0|65535.0] "Unitless" FLRdpHPA,FLRdpHPB
 SG_ FLR2RdrDetn030To034DynPrpty0 : 93|1@1+ (1.0,0.0) [0.0|1.0] "Unitless" FLRdpHPA,FLRdpHPB
 SG_ FLR2RdrDetn030To034DynPrpty1 : 157|1@1+ (1.0,0.0) [0.0|1.0] "Unitless" FLRdpHPA,FLRdpHPB
 SG_ FLR2RdrDetn030To034DynPrpty2 : 221|1@1+ (1.0,0.0) [0.0|1.0] "Unitless" FLRdpHPA,FLRdpHPB
 SG_ FLR2RdrDetn030To034DynPrpty3 : 285|1@1+ (1.0,0.0) [0.0|1.0] "Unitless" FLRdpHPA,FLRdpHPB
 SG_ FLR2RdrDetn030To034DynPrpty4 : 349|1@1+ (1.0,0.0) [0.0|1.0] "Unitless" FLRdpHPA,FLRdpHPB
 SG_ FLR2RdrDetn030To034EleAng0 : 64|8@1+ (0.002,0.0) [0.0|0.5] "rad" FLRdpHPA,FLRdpHPB
 SG_ FLR2RdrDetn030To034EleAng1 : 128|8@1+ (0.002,0.0) [0.0|0.5] "rad" FLRdpHPA,FLRdpHPB
 SG_ FLR2RdrDetn030To034EleAng2 : 192|8@1+ (0.002,0.0) [0.0|0.5] "rad" FLRdpHPA,FLRdpHPB
 SG_ FLR2RdrDetn030To034EleAng3 : 256|8@1+ (0.002,0.0) [0.0|0.5] "rad" FLRdpHPA,FLRdpHPB
 SG_ FLR2RdrDetn030To034EleAng4 : 320|8@1+ (0.002,0.0) [0.0|0.5] "rad" FLRdpHPA,FLRdpHPB
 SG_ FLR2RdrDetn030To034Mode0 : 60|2@1+ (1,0) [0|3] "" FLRdpHPA,FLRdpHPB
 SG_ FLR2RdrDetn030To034Mode1 : 124|2@1+ (1,0) [0|3] "" FLRdpHPA,FLRdpHPB
 SG_ FLR2RdrDetn030To034Mode2 : 188|2@1+ (1,0) [0|3] "" FLRdpHPA,FLRdpHPB
 SG_ FLR2RdrDetn030To034Mode3 : 252|2@1+ (1,0) [0|3] "" FLRdpHPA,FLRdpHPB
 SG_ FLR2RdrDetn030To034Mode4 : 316|2@1+ (1,0) [0|3] "" FLRdpHPA,FLRdpHPB
 SG_ FLR2RdrDetn030To034Quality0 : 62|2@1+ (1,0) [0|3] "" FLRdpHPA,FLRdpHPB
 SG_ FLR2RdrDetn030To034Quality1 : 126|2@1+ (1,0) [0|3] "" FLRdpHPA,FLRdpHPB
 SG_ FLR2RdrDetn030To034Quality2 : 190|2@1+ (1,0) [0|3] "" FLRdpHPA,FLRdpHPB
 SG_ FLR2RdrDetn030To034Quality3 : 254|2@1+ (1,0) [0|3] "" FLRdpHPA,FLRdpHPB
 SG_ FLR2RdrDetn030To034Quality4 : 318|2@1+ (1,0) [0|3] "" FLRdpHPA,FLRdpHPB
 SG_ FLR2RdrDetn030To034Range0 : 48|12@1+ (0.1,0.4) [0.4|300.0] "m" FLRdpHPA,FLRdpHPB
 SG_ FLR2RdrDetn030To034Range1 : 112|12@1+ (0.1,0.4) [0.4|300.0] "m" FLRdpHPA,FLRdpHPB
 SG_ FLR2RdrDetn030To034Range2 : 176|12@1+ (0.1,0.4) [0.4|300.0] "m" FLRdpHPA,FLRdpHPB
 SG_ FLR2RdrDetn030To034Range3 : 240|12@1+ (0.1,0.4) [0.4|300.0] "m" FLRdpHPA,FLRdpHPB
 SG_ FLR2RdrDetn030To034Range4 : 304|12@1+ (0.1,0.4) [0.4|300.0] "m" FLRdpHPA,FLRdpHPB
 SG_ FLR2RdrDetn030To034RCS0 : 83|10@1+ (0.2,-100.0) [-100.0|70.0] "dBsm" FLRdpHPA,FLRdpHPB
 SG_ FLR2RdrDetn030To034RCS1 : 147|10@1+ (0.2,-100.0) [-100.0|70.0] "dBsm" FLRdpHPA,FLRdpHPB
 SG_ FLR2RdrDetn030To034RCS2 : 211|10@1+ (0.2,-100.0) [-100.0|70.0] "dBsm" FLRdpHPA,FLRdpHPB
 SG_ FLR2RdrDetn030To034RCS3 : 275|10@1+ (0.2,-100.0) [-100.0|70.0] "dBsm" FLRdpHPA,FLRdpHPB
 SG_ FLR2RdrDetn030To034RCS4 : 339|10@1+ (0.2,-100.0) [-100.0|70.0] "dBsm" FLRdpHPA,FLRdpHPB
 SG_ FLR2RdrDetn030To034RngRt0 : 72|11@1+ (0.1,-111.11) [-111.11|55.59000000000002] "m/s" FLRdpHPA,FLRdpHPB
 SG_ FLR2RdrDetn030To034RngRt1 : 136|11@1+ (0.1,-111.11) [-111.11|55.59000000000002] "m/s" FLRdpHPA,FLRdpHPB
 SG_ FLR2RdrDetn030To034RngRt2 : 200|11@1+ (0.1,-111.11) [-111.11|55.59000000000002] "m/s" FLRdpHPA,FLRdpHPB
 SG_ FLR2RdrDetn030To034RngRt3 : 264|11@1+ (0.1,-111.11) [-111.11|55.59000000000002] "m/s" FLRdpHPA,FLRdpHPB
 SG_ FLR2RdrDetn030To034RngRt4 : 328|11@1+ (0.1,-111.11) [-111.11|55.59000000000002] "m/s" FLRdpHPA,FLRdpHPB
 SG_ FLR2RdrDetn030To034ScanID : 24|8@1+ (1.0,0.0) [0.0|255.0] "Unitless" FLRdpHPA,FLRdpHPB
 SG_ FLR2RdrDetn030To034SNR0 : 41|7@1+ (0.5,0.0) [0.0|63.5] "dB" FLRdpHPA,FLRdpHPB
 SG_ FLR2RdrDetn030To034SNR1 : 105|7@1+ (0.5,0.0) [0.0|63.5] "dB" FLRdpHPA,FLRdpHPB
 SG_ FLR2RdrDetn030To034SNR2 : 169|7@1+ (0.5,0.0) [0.0|63.5] "dB" FLRdpHPA,FLRdpHPB
 SG_ FLR2RdrDetn030To034SNR3 : 233|7@1+ (0.5,0.0) [0.0|63.5] "dB" FLRdpHPA,FLRdpHPB
 SG_ FLR2RdrDetn030To034SNR4 : 297|7@1+ (0.5,0.0) [0.0|63.5] "dB" FLRdpHPA,FLRdpHPB

BO_ 102 FlrFlr1canFr08 : 64 FLR
 SG_ FLR2RdrDetn035To039_UB : 359|1@0+ (1,0) [0|1] "" FLRdpHPA,FLRdpHPB
 SG_ FLR2RdrDetn035To039AziAng0 : 32|9@1+ (0.0035,-0.87266) [-0.87266|0.91584] "rad" FLRdpHPA,FLRdpHPB
 SG_ FLR2RdrDetn035To039AziAng1 : 96|9@1+ (0.0035,-0.87266) [-0.87266|0.91584] "rad" FLRdpHPA,FLRdpHPB
 SG_ FLR2RdrDetn035To039AziAng2 : 160|9@1+ (0.0035,-0.87266) [-0.87266|0.91584] "rad" FLRdpHPA,FLRdpHPB
 SG_ FLR2RdrDetn035To039AziAng3 : 224|9@1+ (0.0035,-0.87266) [-0.87266|0.91584] "rad" FLRdpHPA,FLRdpHPB
 SG_ FLR2RdrDetn035To039AziAng4 : 288|9@1+ (0.0035,-0.87266) [-0.87266|0.91584] "rad" FLRdpHPA,FLRdpHPB
 SG_ FLR2RdrDetn035To039Counter : 16|8@1+ (1.0,0.0) [0.0|255.0] "Unitless" FLRdpHPA,FLRdpHPB
 SG_ FLR2RdrDetn035To039CRC : 0|16@1+ (1.0,0.0) [0.0|65535.0] "Unitless" FLRdpHPA,FLRdpHPB
 SG_ FLR2RdrDetn035To039DynPrpty0 : 93|1@1+ (1.0,0.0) [0.0|1.0] "Unitless" FLRdpHPA,FLRdpHPB
 SG_ FLR2RdrDetn035To039DynPrpty1 : 157|1@1+ (1.0,0.0) [0.0|1.0] "Unitless" FLRdpHPA,FLRdpHPB
 SG_ FLR2RdrDetn035To039DynPrpty2 : 221|1@1+ (1.0,0.0) [0.0|1.0] "Unitless" FLRdpHPA,FLRdpHPB
 SG_ FLR2RdrDetn035To039DynPrpty3 : 285|1@1+ (1.0,0.0) [0.0|1.0] "Unitless" FLRdpHPA,FLRdpHPB
 SG_ FLR2RdrDetn035To039DynPrpty4 : 349|1@1+ (1.0,0.0) [0.0|1.0] "Unitless" FLRdpHPA,FLRdpHPB
 SG_ FLR2RdrDetn035To039EleAng0 : 64|8@1+ (0.002,0.0) [0.0|0.5] "rad" FLRdpHPA,FLRdpHPB
 SG_ FLR2RdrDetn035To039EleAng1 : 128|8@1+ (0.002,0.0) [0.0|0.5] "rad" FLRdpHPA,FLRdpHPB
 SG_ FLR2RdrDetn035To039EleAng2 : 192|8@1+ (0.002,0.0) [0.0|0.5] "rad" FLRdpHPA,FLRdpHPB
 SG_ FLR2RdrDetn035To039EleAng3 : 256|8@1+ (0.002,0.0) [0.0|0.5] "rad" FLRdpHPA,FLRdpHPB
 SG_ FLR2RdrDetn035To039EleAng4 : 320|8@1+ (0.002,0.0) [0.0|0.5] "rad" FLRdpHPA,FLRdpHPB
 SG_ FLR2RdrDetn035To039Mode0 : 60|2@1+ (1,0) [0|3] "" FLRdpHPA,FLRdpHPB
 SG_ FLR2RdrDetn035To039Mode1 : 124|2@1+ (1,0) [0|3] "" FLRdpHPA,FLRdpHPB
 SG_ FLR2RdrDetn035To039Mode2 : 188|2@1+ (1,0) [0|3] "" FLRdpHPA,FLRdpHPB
 SG_ FLR2RdrDetn035To039Mode3 : 252|2@1+ (1,0) [0|3] "" FLRdpHPA,FLRdpHPB
 SG_ FLR2RdrDetn035To039Mode4 : 316|2@1+ (1,0) [0|3] "" FLRdpHPA,FLRdpHPB
 SG_ FLR2RdrDetn035To039Quality0 : 62|2@1+ (1,0) [0|3] "" FLRdpHPA,FLRdpHPB
 SG_ FLR2RdrDetn035To039Quality1 : 126|2@1+ (1,0) [0|3] "" FLRdpHPA,FLRdpHPB
 SG_ FLR2RdrDetn035To039Quality2 : 190|2@1+ (1,0) [0|3] "" FLRdpHPA,FLRdpHPB
 SG_ FLR2RdrDetn035To039Quality3 : 254|2@1+ (1,0) [0|3] "" FLRdpHPA,FLRdpHPB
 SG_ FLR2RdrDetn035To039Quality4 : 318|2@1+ (1,0) [0|3] "" FLRdpHPA,FLRdpHPB
 SG_ FLR2RdrDetn035To039Range0 : 48|12@1+ (0.1,0.4) [0.4|300.0] "m" FLRdpHPA,FLRdpHPB
 SG_ FLR2RdrDetn035To039Range1 : 112|12@1+ (0.1,0.4) [0.4|300.0] "m" FLRdpHPA,FLRdpHPB
 SG_ FLR2RdrDetn035To039Range2 : 176|12@1+ (0.1,0.4) [0.4|300.0] "m" FLRdpHPA,FLRdpHPB
 SG_ FLR2RdrDetn035To039Range3 : 240|12@1+ (0.1,0.4) [0.4|300.0] "m" FLRdpHPA,FLRdpHPB
 SG_ FLR2RdrDetn035To039Range4 : 304|12@1+ (0.1,0.4) [0.4|300.0] "m" FLRdpHPA,FLRdpHPB
 SG_ FLR2RdrDetn035To039RCS0 : 83|10@1+ (0.2,-100.0) [-100.0|70.0] "dBsm" FLRdpHPA,FLRdpHPB
 SG_ FLR2RdrDetn035To039RCS1 : 147|10@1+ (0.2,-100.0) [-100.0|70.0] "dBsm" FLRdpHPA,FLRdpHPB
 SG_ FLR2RdrDetn035To039RCS2 : 211|10@1+ (0.2,-100.0) [-100.0|70.0] "dBsm" FLRdpHPA,FLRdpHPB
 SG_ FLR2RdrDetn035To039RCS3 : 275|10@1+ (0.2,-100.0) [-100.0|70.0] "dBsm" FLRdpHPA,FLRdpHPB
 SG_ FLR2RdrDetn035To039RCS4 : 339|10@1+ (0.2,-100.0) [-100.0|70.0] "dBsm" FLRdpHPA,FLRdpHPB
 SG_ FLR2RdrDetn035To039RngRt0 : 72|11@1+ (0.1,-111.11) [-111.11|55.59000000000002] "m/s" FLRdpHPA,FLRdpHPB
 SG_ FLR2RdrDetn035To039RngRt1 : 136|11@1+ (0.1,-111.11) [-111.11|55.59000000000002] "m/s" FLRdpHPA,FLRdpHPB
 SG_ FLR2RdrDetn035To039RngRt2 : 200|11@1+ (0.1,-111.11) [-111.11|55.59000000000002] "m/s" FLRdpHPA,FLRdpHPB
 SG_ FLR2RdrDetn035To039RngRt3 : 264|11@1+ (0.1,-111.11) [-111.11|55.59000000000002] "m/s" FLRdpHPA,FLRdpHPB
 SG_ FLR2RdrDetn035To039RngRt4 : 328|11@1+ (0.1,-111.11) [-111.11|55.59000000000002] "m/s" FLRdpHPA,FLRdpHPB
 SG_ FLR2RdrDetn035To039ScanID : 24|8@1+ (1.0,0.0) [0.0|255.0] "Unitless" FLRdpHPA,FLRdpHPB
 SG_ FLR2RdrDetn035To039SNR0 : 41|7@1+ (0.5,0.0) [0.0|63.5] "dB" FLRdpHPA,FLRdpHPB
 SG_ FLR2RdrDetn035To039SNR1 : 105|7@1+ (0.5,0.0) [0.0|63.5] "dB" FLRdpHPA,FLRdpHPB
 SG_ FLR2RdrDetn035To039SNR2 : 169|7@1+ (0.5,0.0) [0.0|63.5] "dB" FLRdpHPA,FLRdpHPB
 SG_ FLR2RdrDetn035To039SNR3 : 233|7@1+ (0.5,0.0) [0.0|63.5] "dB" FLRdpHPA,FLRdpHPB
 SG_ FLR2RdrDetn035To039SNR4 : 297|7@1+ (0.5,0.0) [0.0|63.5] "dB" FLRdpHPA,FLRdpHPB

BO_ 105 FlrFlr1canFr09 : 64 FLR
 SG_ FLR2RdrDetn040To044_UB : 359|1@0+ (1,0) [0|1] "" FLRdpHPA,FLRdpHPB
 SG_ FLR2RdrDetn040To044AziAng0 : 32|9@1+ (0.0035,-0.87266) [-0.87266|0.91584] "rad" FLRdpHPA,FLRdpHPB
 SG_ FLR2RdrDetn040To044AziAng1 : 96|9@1+ (0.0035,-0.87266) [-0.87266|0.91584] "rad" FLRdpHPA,FLRdpHPB
 SG_ FLR2RdrDetn040To044AziAng2 : 160|9@1+ (0.0035,-0.87266) [-0.87266|0.91584] "rad" FLRdpHPA,FLRdpHPB
 SG_ FLR2RdrDetn040To044AziAng3 : 224|9@1+ (0.0035,-0.87266) [-0.87266|0.91584] "rad" FLRdpHPA,FLRdpHPB
 SG_ FLR2RdrDetn040To044AziAng4 : 288|9@1+ (0.0035,-0.87266) [-0.87266|0.91584] "rad" FLRdpHPA,FLRdpHPB
 SG_ FLR2RdrDetn040To044Counter : 16|8@1+ (1.0,0.0) [0.0|255.0] "Unitless" FLRdpHPA,FLRdpHPB
 SG_ FLR2RdrDetn040To044CRC : 0|16@1+ (1.0,0.0) [0.0|65535.0] "Unitless" FLRdpHPA,FLRdpHPB
 SG_ FLR2RdrDetn040To044DynPrpty0 : 93|1@1+ (1.0,0.0) [0.0|1.0] "Unitless" FLRdpHPA,FLRdpHPB
 SG_ FLR2RdrDetn040To044DynPrpty1 : 157|1@1+ (1.0,0.0) [0.0|1.0] "Unitless" FLRdpHPA,FLRdpHPB
 SG_ FLR2RdrDetn040To044DynPrpty2 : 221|1@1+ (1.0,0.0) [0.0|1.0] "Unitless" FLRdpHPA,FLRdpHPB
 SG_ FLR2RdrDetn040To044DynPrpty3 : 285|1@1+ (1.0,0.0) [0.0|1.0] "Unitless" FLRdpHPA,FLRdpHPB
 SG_ FLR2RdrDetn040To044DynPrpty4 : 349|1@1+ (1.0,0.0) [0.0|1.0] "Unitless" FLRdpHPA,FLRdpHPB
 SG_ FLR2RdrDetn040To044EleAng0 : 64|8@1+ (0.002,0.0) [0.0|0.5] "rad" FLRdpHPA,FLRdpHPB
 SG_ FLR2RdrDetn040To044EleAng1 : 128|8@1+ (0.002,0.0) [0.0|0.5] "rad" FLRdpHPA,FLRdpHPB
 SG_ FLR2RdrDetn040To044EleAng2 : 192|8@1+ (0.002,0.0) [0.0|0.5] "rad" FLRdpHPA,FLRdpHPB
 SG_ FLR2RdrDetn040To044EleAng3 : 256|8@1+ (0.002,0.0) [0.0|0.5] "rad" FLRdpHPA,FLRdpHPB
 SG_ FLR2RdrDetn040To044EleAng4 : 320|8@1+ (0.002,0.0) [0.0|0.5] "rad" FLRdpHPA,FLRdpHPB
 SG_ FLR2RdrDetn040To044Mode0 : 60|2@1+ (1,0) [0|3] "" FLRdpHPA,FLRdpHPB
 SG_ FLR2RdrDetn040To044Mode1 : 124|2@1+ (1,0) [0|3] "" FLRdpHPA,FLRdpHPB
 SG_ FLR2RdrDetn040To044Mode2 : 188|2@1+ (1,0) [0|3] "" FLRdpHPA,FLRdpHPB
 SG_ FLR2RdrDetn040To044Mode3 : 252|2@1+ (1,0) [0|3] "" FLRdpHPA,FLRdpHPB
 SG_ FLR2RdrDetn040To044Mode4 : 316|2@1+ (1,0) [0|3] "" FLRdpHPA,FLRdpHPB
 SG_ FLR2RdrDetn040To044Quality0 : 62|2@1+ (1,0) [0|3] "" FLRdpHPA,FLRdpHPB
 SG_ FLR2RdrDetn040To044Quality1 : 126|2@1+ (1,0) [0|3] "" FLRdpHPA,FLRdpHPB
 SG_ FLR2RdrDetn040To044Quality2 : 190|2@1+ (1,0) [0|3] "" FLRdpHPA,FLRdpHPB
 SG_ FLR2RdrDetn040To044Quality3 : 254|2@1+ (1,0) [0|3] "" FLRdpHPA,FLRdpHPB
 SG_ FLR2RdrDetn040To044Quality4 : 318|2@1+ (1,0) [0|3] "" FLRdpHPA,FLRdpHPB
 SG_ FLR2RdrDetn040To044Range0 : 48|12@1+ (0.1,0.4) [0.4|300.0] "m" FLRdpHPA,FLRdpHPB
 SG_ FLR2RdrDetn040To044Range1 : 112|12@1+ (0.1,0.4) [0.4|300.0] "m" FLRdpHPA,FLRdpHPB
 SG_ FLR2RdrDetn040To044Range2 : 176|12@1+ (0.1,0.4) [0.4|300.0] "m" FLRdpHPA,FLRdpHPB
 SG_ FLR2RdrDetn040To044Range3 : 240|12@1+ (0.1,0.4) [0.4|300.0] "m" FLRdpHPA,FLRdpHPB
 SG_ FLR2RdrDetn040To044Range4 : 304|12@1+ (0.1,0.4) [0.4|300.0] "m" FLRdpHPA,FLRdpHPB
 SG_ FLR2RdrDetn040To044RCS0 : 83|10@1+ (0.2,-100.0) [-100.0|70.0] "dBsm" FLRdpHPA,FLRdpHPB
 SG_ FLR2RdrDetn040To044RCS1 : 147|10@1+ (0.2,-100.0) [-100.0|70.0] "dBsm" FLRdpHPA,FLRdpHPB
 SG_ FLR2RdrDetn040To044RCS2 : 211|10@1+ (0.2,-100.0) [-100.0|70.0] "dBsm" FLRdpHPA,FLRdpHPB
 SG_ FLR2RdrDetn040To044RCS3 : 275|10@1+ (0.2,-100.0) [-100.0|70.0] "dBsm" FLRdpHPA,FLRdpHPB
 SG_ FLR2RdrDetn040To044RCS4 : 339|10@1+ (0.2,-100.0) [-100.0|70.0] "dBsm" FLRdpHPA,FLRdpHPB
 SG_ FLR2RdrDetn040To044RngRt0 : 72|11@1+ (0.1,-111.11) [-111.11|55.59000000000002] "m/s" FLRdpHPA,FLRdpHPB
 SG_ FLR2RdrDetn040To044RngRt1 : 136|11@1+ (0.1,-111.11) [-111.11|55.59000000000002] "m/s" FLRdpHPA,FLRdpHPB
 SG_ FLR2RdrDetn040To044RngRt2 : 200|11@1+ (0.1,-111.11) [-111.11|55.59000000000002] "m/s" FLRdpHPA,FLRdpHPB
 SG_ FLR2RdrDetn040To044RngRt3 : 264|11@1+ (0.1,-111.11) [-111.11|55.59000000000002] "m/s" FLRdpHPA,FLRdpHPB
 SG_ FLR2RdrDetn040To044RngRt4 : 328|11@1+ (0.1,-111.11) [-111.11|55.59000000000002] "m/s" FLRdpHPA,FLRdpHPB
 SG_ FLR2RdrDetn040To044ScanID : 24|8@1+ (1.0,0.0) [0.0|255.0] "Unitless" FLRdpHPA,FLRdpHPB
 SG_ FLR2RdrDetn040To044SNR0 : 41|7@1+ (0.5,0.0) [0.0|63.5] "dB" FLRdpHPA,FLRdpHPB
 SG_ FLR2RdrDetn040To044SNR1 : 105|7@1+ (0.5,0.0) [0.0|63.5] "dB" FLRdpHPA,FLRdpHPB
 SG_ FLR2RdrDetn040To044SNR2 : 169|7@1+ (0.5,0.0) [0.0|63.5] "dB" FLRdpHPA,FLRdpHPB
 SG_ FLR2RdrDetn040To044SNR3 : 233|7@1+ (0.5,0.0) [0.0|63.5] "dB" FLRdpHPA,FLRdpHPB
 SG_ FLR2RdrDetn040To044SNR4 : 297|7@1+ (0.5,0.0) [0.0|63.5] "dB" FLRdpHPA,FLRdpHPB

BO_ 108 FlrFlr1canFr10 : 64 FLR
 SG_ FLR2RdrDetn045To049_UB : 359|1@0+ (1,0) [0|1] "" FLRdpHPA,FLRdpHPB
 SG_ FLR2RdrDetn045To049AziAng0 : 32|9@1+ (0.0035,-0.87266) [-0.87266|0.91584] "rad" FLRdpHPA,FLRdpHPB
 SG_ FLR2RdrDetn045To049AziAng1 : 96|9@1+ (0.0035,-0.87266) [-0.87266|0.91584] "rad" FLRdpHPA,FLRdpHPB
 SG_ FLR2RdrDetn045To049AziAng2 : 160|9@1+ (0.0035,-0.87266) [-0.87266|0.91584] "rad" FLRdpHPA,FLRdpHPB
 SG_ FLR2RdrDetn045To049AziAng3 : 224|9@1+ (0.0035,-0.87266) [-0.87266|0.91584] "rad" FLRdpHPA,FLRdpHPB
 SG_ FLR2RdrDetn045To049AziAng4 : 288|9@1+ (0.0035,-0.87266) [-0.87266|0.91584] "rad" FLRdpHPA,FLRdpHPB
 SG_ FLR2RdrDetn045To049Counter : 16|8@1+ (1.0,0.0) [0.0|255.0] "Unitless" FLRdpHPA,FLRdpHPB
 SG_ FLR2RdrDetn045To049CRC : 0|16@1+ (1.0,0.0) [0.0|65535.0] "Unitless" FLRdpHPA,FLRdpHPB
 SG_ FLR2RdrDetn045To049DynPrpty0 : 93|1@1+ (1.0,0.0) [0.0|1.0] "Unitless" FLRdpHPA,FLRdpHPB
 SG_ FLR2RdrDetn045To049DynPrpty1 : 157|1@1+ (1.0,0.0) [0.0|1.0] "Unitless" FLRdpHPA,FLRdpHPB
 SG_ FLR2RdrDetn045To049DynPrpty2 : 221|1@1+ (1.0,0.0) [0.0|1.0] "Unitless" FLRdpHPA,FLRdpHPB
 SG_ FLR2RdrDetn045To049DynPrpty3 : 285|1@1+ (1.0,0.0) [0.0|1.0] "Unitless" FLRdpHPA,FLRdpHPB
 SG_ FLR2RdrDetn045To049DynPrpty4 : 349|1@1+ (1.0,0.0) [0.0|1.0] "Unitless" FLRdpHPA,FLRdpHPB
 SG_ FLR2RdrDetn045To049EleAng0 : 64|8@1+ (0.002,0.0) [0.0|0.5] "rad" FLRdpHPA,FLRdpHPB
 SG_ FLR2RdrDetn045To049EleAng1 : 128|8@1+ (0.002,0.0) [0.0|0.5] "rad" FLRdpHPA,FLRdpHPB
 SG_ FLR2RdrDetn045To049EleAng2 : 192|8@1+ (0.002,0.0) [0.0|0.5] "rad" FLRdpHPA,FLRdpHPB
 SG_ FLR2RdrDetn045To049EleAng3 : 256|8@1+ (0.002,0.0) [0.0|0.5] "rad" FLRdpHPA,FLRdpHPB
 SG_ FLR2RdrDetn045To049EleAng4 : 320|8@1+ (0.002,0.0) [0.0|0.5] "rad" FLRdpHPA,FLRdpHPB
 SG_ FLR2RdrDetn045To049Mode0 : 60|2@1+ (1,0) [0|3] "" FLRdpHPA,FLRdpHPB
 SG_ FLR2RdrDetn045To049Mode1 : 124|2@1+ (1,0) [0|3] "" FLRdpHPA,FLRdpHPB
 SG_ FLR2RdrDetn045To049Mode2 : 188|2@1+ (1,0) [0|3] "" FLRdpHPA,FLRdpHPB
 SG_ FLR2RdrDetn045To049Mode3 : 252|2@1+ (1,0) [0|3] "" FLRdpHPA,FLRdpHPB
 SG_ FLR2RdrDetn045To049Mode4 : 316|2@1+ (1,0) [0|3] "" FLRdpHPA,FLRdpHPB
 SG_ FLR2RdrDetn045To049Quality0 : 62|2@1+ (1,0) [0|3] "" FLRdpHPA,FLRdpHPB
 SG_ FLR2RdrDetn045To049Quality1 : 126|2@1+ (1,0) [0|3] "" FLRdpHPA,FLRdpHPB
 SG_ FLR2RdrDetn045To049Quality2 : 190|2@1+ (1,0) [0|3] "" FLRdpHPA,FLRdpHPB
 SG_ FLR2RdrDetn045To049Quality3 : 254|2@1+ (1,0) [0|3] "" FLRdpHPA,FLRdpHPB
 SG_ FLR2RdrDetn045To049Quality4 : 318|2@1+ (1,0) [0|3] "" FLRdpHPA,FLRdpHPB
 SG_ FLR2RdrDetn045To049Range0 : 48|12@1+ (0.1,0.4) [0.4|300.0] "m" FLRdpHPA,FLRdpHPB
 SG_ FLR2RdrDetn045To049Range1 : 112|12@1+ (0.1,0.4) [0.4|300.0] "m" FLRdpHPA,FLRdpHPB
 SG_ FLR2RdrDetn045To049Range2 : 176|12@1+ (0.1,0.4) [0.4|300.0] "m" FLRdpHPA,FLRdpHPB
 SG_ FLR2RdrDetn045To049Range3 : 240|12@1+ (0.1,0.4) [0.4|300.0] "m" FLRdpHPA,FLRdpHPB
 SG_ FLR2RdrDetn045To049Range4 : 304|12@1+ (0.1,0.4) [0.4|300.0] "m" FLRdpHPA,FLRdpHPB
 SG_ FLR2RdrDetn045To049RCS0 : 83|10@1+ (0.2,-100.0) [-100.0|70.0] "dBsm" FLRdpHPA,FLRdpHPB
 SG_ FLR2RdrDetn045To049RCS1 : 147|10@1+ (0.2,-100.0) [-100.0|70.0] "dBsm" FLRdpHPA,FLRdpHPB
 SG_ FLR2RdrDetn045To049RCS2 : 211|10@1+ (0.2,-100.0) [-100.0|70.0] "dBsm" FLRdpHPA,FLRdpHPB
 SG_ FLR2RdrDetn045To049RCS3 : 275|10@1+ (0.2,-100.0) [-100.0|70.0] "dBsm" FLRdpHPA,FLRdpHPB
 SG_ FLR2RdrDetn045To049RCS4 : 339|10@1+ (0.2,-100.0) [-100.0|70.0] "dBsm" FLRdpHPA,FLRdpHPB
 SG_ FLR2RdrDetn045To049RngRt0 : 72|11@1+ (0.1,-111.11) [-111.11|55.59000000000002] "m/s" FLRdpHPA,FLRdpHPB
 SG_ FLR2RdrDetn045To049RngRt1 : 136|11@1+ (0.1,-111.11) [-111.11|55.59000000000002] "m/s" FLRdpHPA,FLRdpHPB
 SG_ FLR2RdrDetn045To049RngRt2 : 200|11@1+ (0.1,-111.11) [-111.11|55.59000000000002] "m/s" FLRdpHPA,FLRdpHPB
 SG_ FLR2RdrDetn045To049RngRt3 : 264|11@1+ (0.1,-111.11) [-111.11|55.59000000000002] "m/s" FLRdpHPA,FLRdpHPB
 SG_ FLR2RdrDetn045To049RngRt4 : 328|11@1+ (0.1,-111.11) [-111.11|55.59000000000002] "m/s" FLRdpHPA,FLRdpHPB
 SG_ FLR2RdrDetn045To049ScanID : 24|8@1+ (1.0,0.0) [0.0|255.0] "Unitless" FLRdpHPA,FLRdpHPB
 SG_ FLR2RdrDetn045To049SNR0 : 41|7@1+ (0.5,0.0) [0.0|63.5] "dB" FLRdpHPA,FLRdpHPB
 SG_ FLR2RdrDetn045To049SNR1 : 105|7@1+ (0.5,0.0) [0.0|63.5] "dB" FLRdpHPA,FLRdpHPB
 SG_ FLR2RdrDetn045To049SNR2 : 169|7@1+ (0.5,0.0) [0.0|63.5] "dB" FLRdpHPA,FLRdpHPB
 SG_ FLR2RdrDetn045To049SNR3 : 233|7@1+ (0.5,0.0) [0.0|63.5] "dB" FLRdpHPA,FLRdpHPB
 SG_ FLR2RdrDetn045To049SNR4 : 297|7@1+ (0.5,0.0) [0.0|63.5] "dB" FLRdpHPA,FLRdpHPB

BO_ 112 FlrFlr1canFr11 : 64 FLR
 SG_ FLR2RdrDetn050To054_UB : 359|1@0+ (1,0) [0|1] "" FLRdpHPA,FLRdpHPB
 SG_ FLR2RdrDetn050To054AziAng0 : 32|9@1+ (0.0035,-0.87266) [-0.87266|0.91584] "rad" FLRdpHPA,FLRdpHPB
 SG_ FLR2RdrDetn050To054AziAng1 : 96|9@1+ (0.0035,-0.87266) [-0.87266|0.91584] "rad" FLRdpHPA,FLRdpHPB
 SG_ FLR2RdrDetn050To054AziAng2 : 160|9@1+ (0.0035,-0.87266) [-0.87266|0.91584] "rad" FLRdpHPA,FLRdpHPB
 SG_ FLR2RdrDetn050To054AziAng3 : 224|9@1+ (0.0035,-0.87266) [-0.87266|0.91584] "rad" FLRdpHPA,FLRdpHPB
 SG_ FLR2RdrDetn050To054AziAng4 : 288|9@1+ (0.0035,-0.87266) [-0.87266|0.91584] "rad" FLRdpHPA,FLRdpHPB
 SG_ FLR2RdrDetn050To054Counter : 16|8@1+ (1.0,0.0) [0.0|255.0] "Unitless" FLRdpHPA,FLRdpHPB
 SG_ FLR2RdrDetn050To054CRC : 0|16@1+ (1.0,0.0) [0.0|65535.0] "Unitless" FLRdpHPA,FLRdpHPB
 SG_ FLR2RdrDetn050To054DynPrpty0 : 93|1@1+ (1.0,0.0) [0.0|1.0] "Unitless" FLRdpHPA,FLRdpHPB
 SG_ FLR2RdrDetn050To054DynPrpty1 : 157|1@1+ (1.0,0.0) [0.0|1.0] "Unitless" FLRdpHPA,FLRdpHPB
 SG_ FLR2RdrDetn050To054DynPrpty2 : 221|1@1+ (1.0,0.0) [0.0|1.0] "Unitless" FLRdpHPA,FLRdpHPB
 SG_ FLR2RdrDetn050To054DynPrpty3 : 285|1@1+ (1.0,0.0) [0.0|1.0] "Unitless" FLRdpHPA,FLRdpHPB
 SG_ FLR2RdrDetn050To054DynPrpty4 : 349|1@1+ (1.0,0.0) [0.0|1.0] "Unitless" FLRdpHPA,FLRdpHPB
 SG_ FLR2RdrDetn050To054EleAng0 : 64|8@1+ (0.002,0.0) [0.0|0.5] "rad" FLRdpHPA,FLRdpHPB
 SG_ FLR2RdrDetn050To054EleAng1 : 128|8@1+ (0.002,0.0) [0.0|0.5] "rad" FLRdpHPA,FLRdpHPB
 SG_ FLR2RdrDetn050To054EleAng2 : 192|8@1+ (0.002,0.0) [0.0|0.5] "rad" FLRdpHPA,FLRdpHPB
 SG_ FLR2RdrDetn050To054EleAng3 : 256|8@1+ (0.002,0.0) [0.0|0.5] "rad" FLRdpHPA,FLRdpHPB
 SG_ FLR2RdrDetn050To054EleAng4 : 320|8@1+ (0.002,0.0) [0.0|0.5] "rad" FLRdpHPA,FLRdpHPB
 SG_ FLR2RdrDetn050To054Mode0 : 60|2@1+ (1,0) [0|3] "" FLRdpHPA,FLRdpHPB
 SG_ FLR2RdrDetn050To054Mode1 : 124|2@1+ (1,0) [0|3] "" FLRdpHPA,FLRdpHPB
 SG_ FLR2RdrDetn050To054Mode2 : 188|2@1+ (1,0) [0|3] "" FLRdpHPA,FLRdpHPB
 SG_ FLR2RdrDetn050To054Mode3 : 252|2@1+ (1,0) [0|3] "" FLRdpHPA,FLRdpHPB
 SG_ FLR2RdrDetn050To054Mode4 : 316|2@1+ (1,0) [0|3] "" FLRdpHPA,FLRdpHPB
 SG_ FLR2RdrDetn050To054Quality0 : 62|2@1+ (1,0) [0|3] "" FLRdpHPA,FLRdpHPB
 SG_ FLR2RdrDetn050To054Quality1 : 126|2@1+ (1,0) [0|3] "" FLRdpHPA,FLRdpHPB
 SG_ FLR2RdrDetn050To054Quality2 : 190|2@1+ (1,0) [0|3] "" FLRdpHPA,FLRdpHPB
 SG_ FLR2RdrDetn050To054Quality3 : 254|2@1+ (1,0) [0|3] "" FLRdpHPA,FLRdpHPB
 SG_ FLR2RdrDetn050To054Quality4 : 318|2@1+ (1,0) [0|3] "" FLRdpHPA,FLRdpHPB
 SG_ FLR2RdrDetn050To054Range0 : 48|12@1+ (0.1,0.4) [0.4|300.0] "m" FLRdpHPA,FLRdpHPB
 SG_ FLR2RdrDetn050To054Range1 : 112|12@1+ (0.1,0.4) [0.4|300.0] "m" FLRdpHPA,FLRdpHPB
 SG_ FLR2RdrDetn050To054Range2 : 176|12@1+ (0.1,0.4) [0.4|300.0] "m" FLRdpHPA,FLRdpHPB
 SG_ FLR2RdrDetn050To054Range3 : 240|12@1+ (0.1,0.4) [0.4|300.0] "m" FLRdpHPA,FLRdpHPB
 SG_ FLR2RdrDetn050To054Range4 : 304|12@1+ (0.1,0.4) [0.4|300.0] "m" FLRdpHPA,FLRdpHPB
 SG_ FLR2RdrDetn050To054RCS0 : 83|10@1+ (0.2,-100.0) [-100.0|70.0] "dBsm" FLRdpHPA,FLRdpHPB
 SG_ FLR2RdrDetn050To054RCS1 : 147|10@1+ (0.2,-100.0) [-100.0|70.0] "dBsm" FLRdpHPA,FLRdpHPB
 SG_ FLR2RdrDetn050To054RCS2 : 211|10@1+ (0.2,-100.0) [-100.0|70.0] "dBsm" FLRdpHPA,FLRdpHPB
 SG_ FLR2RdrDetn050To054RCS3 : 275|10@1+ (0.2,-100.0) [-100.0|70.0] "dBsm" FLRdpHPA,FLRdpHPB
 SG_ FLR2RdrDetn050To054RCS4 : 339|10@1+ (0.2,-100.0) [-100.0|70.0] "dBsm" FLRdpHPA,FLRdpHPB
 SG_ FLR2RdrDetn050To054RngRt0 : 72|11@1+ (0.1,-111.11) [-111.11|55.59000000000002] "m/s" FLRdpHPA,FLRdpHPB
 SG_ FLR2RdrDetn050To054RngRt1 : 136|11@1+ (0.1,-111.11) [-111.11|55.59000000000002] "m/s" FLRdpHPA,FLRdpHPB
 SG_ FLR2RdrDetn050To054RngRt2 : 200|11@1+ (0.1,-111.11) [-111.11|55.59000000000002] "m/s" FLRdpHPA,FLRdpHPB
 SG_ FLR2RdrDetn050To054RngRt3 : 264|11@1+ (0.1,-111.11) [-111.11|55.59000000000002] "m/s" FLRdpHPA,FLRdpHPB
 SG_ FLR2RdrDetn050To054RngRt4 : 328|11@1+ (0.1,-111.11) [-111.11|55.59000000000002] "m/s" FLRdpHPA,FLRdpHPB
 SG_ FLR2RdrDetn050To054ScanID : 24|8@1+ (1.0,0.0) [0.0|255.0] "Unitless" FLRdpHPA,FLRdpHPB
 SG_ FLR2RdrDetn050To054SNR0 : 41|7@1+ (0.5,0.0) [0.0|63.5] "dB" FLRdpHPA,FLRdpHPB
 SG_ FLR2RdrDetn050To054SNR1 : 105|7@1+ (0.5,0.0) [0.0|63.5] "dB" FLRdpHPA,FLRdpHPB
 SG_ FLR2RdrDetn050To054SNR2 : 169|7@1+ (0.5,0.0) [0.0|63.5] "dB" FLRdpHPA,FLRdpHPB
 SG_ FLR2RdrDetn050To054SNR3 : 233|7@1+ (0.5,0.0) [0.0|63.5] "dB" FLRdpHPA,FLRdpHPB
 SG_ FLR2RdrDetn050To054SNR4 : 297|7@1+ (0.5,0.0) [0.0|63.5] "dB" FLRdpHPA,FLRdpHPB

BO_ 115 FlrFlr1canFr12 : 64 FLR
 SG_ FLR2RdrDetn055To059_UB : 359|1@0+ (1,0) [0|1] "" FLRdpHPA,FLRdpHPB
 SG_ FLR2RdrDetn055To059AziAng0 : 32|9@1+ (0.0035,-0.87266) [-0.87266|0.91584] "rad" FLRdpHPA,FLRdpHPB
 SG_ FLR2RdrDetn055To059AziAng1 : 96|9@1+ (0.0035,-0.87266) [-0.87266|0.91584] "rad" FLRdpHPA,FLRdpHPB
 SG_ FLR2RdrDetn055To059AziAng2 : 160|9@1+ (0.0035,-0.87266) [-0.87266|0.91584] "rad" FLRdpHPA,FLRdpHPB
 SG_ FLR2RdrDetn055To059AziAng3 : 224|9@1+ (0.0035,-0.87266) [-0.87266|0.91584] "rad" FLRdpHPA,FLRdpHPB
 SG_ FLR2RdrDetn055To059AziAng4 : 288|9@1+ (0.0035,-0.87266) [-0.87266|0.91584] "rad" FLRdpHPA,FLRdpHPB
 SG_ FLR2RdrDetn055To059Counter : 16|8@1+ (1.0,0.0) [0.0|255.0] "Unitless" FLRdpHPA,FLRdpHPB
 SG_ FLR2RdrDetn055To059CRC : 0|16@1+ (1.0,0.0) [0.0|65535.0] "Unitless" FLRdpHPA,FLRdpHPB
 SG_ FLR2RdrDetn055To059DynPrpty0 : 93|1@1+ (1.0,0.0) [0.0|1.0] "Unitless" FLRdpHPA,FLRdpHPB
 SG_ FLR2RdrDetn055To059DynPrpty1 : 157|1@1+ (1.0,0.0) [0.0|1.0] "Unitless" FLRdpHPA,FLRdpHPB
 SG_ FLR2RdrDetn055To059DynPrpty2 : 221|1@1+ (1.0,0.0) [0.0|1.0] "Unitless" FLRdpHPA,FLRdpHPB
 SG_ FLR2RdrDetn055To059DynPrpty3 : 285|1@1+ (1.0,0.0) [0.0|1.0] "Unitless" FLRdpHPA,FLRdpHPB
 SG_ FLR2RdrDetn055To059DynPrpty4 : 349|1@1+ (1.0,0.0) [0.0|1.0] "Unitless" FLRdpHPA,FLRdpHPB
 SG_ FLR2RdrDetn055To059EleAng0 : 64|8@1+ (0.002,0.0) [0.0|0.5] "rad" FLRdpHPA,FLRdpHPB
 SG_ FLR2RdrDetn055To059EleAng1 : 128|8@1+ (0.002,0.0) [0.0|0.5] "rad" FLRdpHPA,FLRdpHPB
 SG_ FLR2RdrDetn055To059EleAng2 : 192|8@1+ (0.002,0.0) [0.0|0.5] "rad" FLRdpHPA,FLRdpHPB
 SG_ FLR2RdrDetn055To059EleAng3 : 256|8@1+ (0.002,0.0) [0.0|0.5] "rad" FLRdpHPA,FLRdpHPB
 SG_ FLR2RdrDetn055To059EleAng4 : 320|8@1+ (0.002,0.0) [0.0|0.5] "rad" FLRdpHPA,FLRdpHPB
 SG_ FLR2RdrDetn055To059Mode0 : 60|2@1+ (1,0) [0|3] "" FLRdpHPA,FLRdpHPB
 SG_ FLR2RdrDetn055To059Mode1 : 124|2@1+ (1,0) [0|3] "" FLRdpHPA,FLRdpHPB
 SG_ FLR2RdrDetn055To059Mode2 : 188|2@1+ (1,0) [0|3] "" FLRdpHPA,FLRdpHPB
 SG_ FLR2RdrDetn055To059Mode3 : 252|2@1+ (1,0) [0|3] "" FLRdpHPA,FLRdpHPB
 SG_ FLR2RdrDetn055To059Mode4 : 316|2@1+ (1,0) [0|3] "" FLRdpHPA,FLRdpHPB
 SG_ FLR2RdrDetn055To059Quality0 : 62|2@1+ (1,0) [0|3] "" FLRdpHPA,FLRdpHPB
 SG_ FLR2RdrDetn055To059Quality1 : 126|2@1+ (1,0) [0|3] "" FLRdpHPA,FLRdpHPB
 SG_ FLR2RdrDetn055To059Quality2 : 190|2@1+ (1,0) [0|3] "" FLRdpHPA,FLRdpHPB
 SG_ FLR2RdrDetn055To059Quality3 : 254|2@1+ (1,0) [0|3] "" FLRdpHPA,FLRdpHPB
 SG_ FLR2RdrDetn055To059Quality4 : 318|2@1+ (1,0) [0|3] "" FLRdpHPA,FLRdpHPB
 SG_ FLR2RdrDetn055To059Range0 : 48|12@1+ (0.1,0.4) [0.4|300.0] "m" FLRdpHPA,FLRdpHPB
 SG_ FLR2RdrDetn055To059Range1 : 112|12@1+ (0.1,0.4) [0.4|300.0] "m" FLRdpHPA,FLRdpHPB
 SG_ FLR2RdrDetn055To059Range2 : 176|12@1+ (0.1,0.4) [0.4|300.0] "m" FLRdpHPA,FLRdpHPB
 SG_ FLR2RdrDetn055To059Range3 : 240|12@1+ (0.1,0.4) [0.4|300.0] "m" FLRdpHPA,FLRdpHPB
 SG_ FLR2RdrDetn055To059Range4 : 304|12@1+ (0.1,0.4) [0.4|300.0] "m" FLRdpHPA,FLRdpHPB
 SG_ FLR2RdrDetn055To059RCS0 : 83|10@1+ (0.2,-100.0) [-100.0|70.0] "dBsm" FLRdpHPA,FLRdpHPB
 SG_ FLR2RdrDetn055To059RCS1 : 147|10@1+ (0.2,-100.0) [-100.0|70.0] "dBsm" FLRdpHPA,FLRdpHPB
 SG_ FLR2RdrDetn055To059RCS2 : 211|10@1+ (0.2,-100.0) [-100.0|70.0] "dBsm" FLRdpHPA,FLRdpHPB
 SG_ FLR2RdrDetn055To059RCS3 : 275|10@1+ (0.2,-100.0) [-100.0|70.0] "dBsm" FLRdpHPA,FLRdpHPB
 SG_ FLR2RdrDetn055To059RCS4 : 339|10@1+ (0.2,-100.0) [-100.0|70.0] "dBsm" FLRdpHPA,FLRdpHPB
 SG_ FLR2RdrDetn055To059RngRt0 : 72|11@1+ (0.1,-111.11) [-111.11|55.59000000000002] "m/s" FLRdpHPA,FLRdpHPB
 SG_ FLR2RdrDetn055To059RngRt1 : 136|11@1+ (0.1,-111.11) [-111.11|55.59000000000002] "m/s" FLRdpHPA,FLRdpHPB
 SG_ FLR2RdrDetn055To059RngRt2 : 200|11@1+ (0.1,-111.11) [-111.11|55.59000000000002] "m/s" FLRdpHPA,FLRdpHPB
 SG_ FLR2RdrDetn055To059RngRt3 : 264|11@1+ (0.1,-111.11) [-111.11|55.59000000000002] "m/s" FLRdpHPA,FLRdpHPB
 SG_ FLR2RdrDetn055To059RngRt4 : 328|11@1+ (0.1,-111.11) [-111.11|55.59000000000002] "m/s" FLRdpHPA,FLRdpHPB
 SG_ FLR2RdrDetn055To059ScanID : 24|8@1+ (1.0,0.0) [0.0|255.0] "Unitless" FLRdpHPA,FLRdpHPB
 SG_ FLR2RdrDetn055To059SNR0 : 41|7@1+ (0.5,0.0) [0.0|63.5] "dB" FLRdpHPA,FLRdpHPB
 SG_ FLR2RdrDetn055To059SNR1 : 105|7@1+ (0.5,0.0) [0.0|63.5] "dB" FLRdpHPA,FLRdpHPB
 SG_ FLR2RdrDetn055To059SNR2 : 169|7@1+ (0.5,0.0) [0.0|63.5] "dB" FLRdpHPA,FLRdpHPB
 SG_ FLR2RdrDetn055To059SNR3 : 233|7@1+ (0.5,0.0) [0.0|63.5] "dB" FLRdpHPA,FLRdpHPB
 SG_ FLR2RdrDetn055To059SNR4 : 297|7@1+ (0.5,0.0) [0.0|63.5] "dB" FLRdpHPA,FLRdpHPB

// Node Comments
CM_ BU_ FLR "Forward Looking Radar";
CM_ BU_ FLRdpHPA "Device Proxy for Forward Looking Radar";

// Signal Comments
CM_ SG_ 512 VehicleMotionStateAcceleroMeterLateral "Lateral acceleration of the Inertial Measurement Unit";
CM_ SG_ 512 VehicleMotionStateAccelerometerLateralQuality "Quality Of Estimate";
CM_ SG_ 512 VehicleMotionStateAccelerometerLongitudinal "Longitudinal acceleration of the Inertial Measurement Unit";
CM_ SG_ 512 VehicleMotionStateAccelerometerLongitudinalQuality "Quality of estimate";
CM_ SG_ 512 VehicleMotionStateAccelerometerVertical "Vertical acceleration of the Inertial Measurement Unit";
CM_ SG_ 512 VehicleMotionStateAccelerometerVerticalQuality "Quality of estimate";
CM_ SG_ 512 VehicleMotionStateAngularVelocityRoll "Roll angular velocity about the x-axis. Also referred to as roll rate. Affected during start of cornering or driving into banked roads. Roll angle defined positive when banking right";
CM_ SG_ 512 VehicleMotionStateAngularVelocityRollQuality "Quality of Estimate";
CM_ SG_ 512 VehicleMotionStateAngularVelocityYaw "Yaw angular velocity about the z-axis. Also referred to as yaw rate. Affected during steering changes. Yaw angle defined positive when turning left";
CM_ SG_ 512 VehicleMotionStateAngularVelocityYawQuality "Quality Of Estimate";
CM_ SG_ 512 VehicleMotionStateCounter "Counter";
CM_ SG_ 512 VehicleMotionStateCRC "CRC";
CM_ SG_ 512 VehicleMotionStateMovingDirection "Moving direction of vehicle";
CM_ SG_ 512 VehicleMotionStateMovingDirectionQuality "Quality of Estimate";
CM_ SG_ 512 VehicleMotionStateVelocityLongitudinal "Estimate of instantanious longitudinal velocity of vehicle using wheel rotary encoders, the Inertial Measurement Unit and the Global Positioning System. Vehicle axis system defined by ISO 8855";
CM_ SG_ 512 VehicleMotionStateVelocityLongitudinalQuality "Quality of Estimate";
CM_ SG_ 512 VehicleMotionStateWheelAngle "Front steering angle estimate";
CM_ SG_ 512 VehicleMotionStateWheelAngleQuality "Quality of Estimate";
CM_ SG_ 512 VehicleMotionStateWheelAngularVelocityFrontLeft "Front left wheel angular velocity";
CM_ SG_ 512 VehicleMotionStateWheelAngularVelocityFrontLeftQuality "Quality of Estimate";
CM_ SG_ 512 VehicleMotionStateWheelAngularVelocityFrontRight "Front right wheel angular velocity";
CM_ SG_ 512 VehicleMotionStateWheelAngularVelocityFrontRightQuality "Quality of Estimate";
CM_ SG_ 512 VehicleMotionStateWheelAngularVelocityRearLeft "Rear left wheel angular velocity";
CM_ SG_ 512 VehicleMotionStateWheelAngularVelocityRearLeftQuality "Quality Of Estimate";
CM_ SG_ 512 VehicleMotionStateWheelAngularVelocityRearRight "Rear right wheel angular velocity";
CM_ SG_ 512 VehicleMotionStateWheelAngularVelocityRearRightQuality "Quality of Estimate";
CM_ SG_ 528 CarConfigVehicleTyp "CarConfiguration Parameter which states which car model the sw shall be adapted to";
CM_ SG_ 528 PowerModeFLRCounter "Counter";
CM_ SG_ 528 PowerModeFLRCRC "CRC";
CM_ SG_ 528 PowerModeFLRRdrActvnReq "Radar Activation Request";
CM_ SG_ 528 PowerModeFLRRdrPwrlossNoti "Radar Power Loss Notification";
CM_ SG_ 544 GlobalSnapShotRdrCounter "Counter";
CM_ SG_ 544 GlobalSnapShotRdrCRC "CRC";
CM_ SG_ 544 GlobalSnapShotRdrGlobalRealTimeRdr "Global Real Time";
CM_ SG_ 544 GlobalSnapShotRdrOutsideTemperatureRdr "Outside Temperature";
CM_ SG_ 544 GlobalSnapShotRdrTotalDistanceRdr "Total Distance";
CM_ SG_ 544 GlobalSnapShotRdrUsageModeRdr "Usage Mode";
CM_ SG_ 544 GlobalSnapShotRdrVehicleBatteryVoltageRdr "Vehicle Battery Voltage";
CM_ SG_ 544 GlobalSnapShotRdrVehicleSpeedRdr "Vehicle Speed";
CM_ SG_ 560 VehicleModesProviderCarModSts "Product Lifecycle distributes different lifecycle modes of the vehicle which includes Car Mode e.g. (normal, transport, dyno, factory), Crash Mode. These product lifecycle modes are not only for safety and security management but also for preserving energy resources (HV/LV). Product Lifecycle modes which includes normal, transport, factory, dyno are set based on diagnostics input, crash mode from SRS or dyno mode are triggered by driver input sequence. Detailed description how these different modes are changed can be seen in section Scope & Boundary Diagram.";
CM_ SG_ 560 VehicleModesProviderCarModSubtypWd "Normal The default subtype during normal operation.factoryPaused  When the vehicle is only temporary in carmode Normal during factory parking.FactoryDriving When the vehicle is only temporary in carmode Norval during factory driving.TransportDriving When the vehicle is only temporary in carmode Normal during transport parking.TwoWheelDyno When the user has selected two wheel dynamometer in carmode Dyno.FourWheelDyno When the user has selected four wheel dynamometer in croak Dyno.";
CM_ SG_ 560 VehicleModesProviderUsageModeResponsive "Usage Mode Responsive";
CM_ SG_ 576 FuncInfoAntilockBrakingSystemState "State of the Anti-lock braking system (ABS) for all wheels , is_enabled    bool Indicates if the ABS function is disabled due to a failure or enabled";
CM_ SG_ 576 FuncInfoBrkTracCtrlActv "Indicates  if brake traction control (TC) is active on at least one wheel";
CM_ SG_ 80 FLR2RdrDetn000To004AziAng0 "Azimuth Angle";
CM_ SG_ 80 FLR2RdrDetn000To004AziAng1 "Azimuth Angle";
CM_ SG_ 80 FLR2RdrDetn000To004AziAng2 "Azimuth Angle";
CM_ SG_ 80 FLR2RdrDetn000To004AziAng3 "Azimuth Angle";
CM_ SG_ 80 FLR2RdrDetn000To004AziAng4 "Azimuth Angle";
CM_ SG_ 80 FLR2RdrDetn000To004DynPrpty0 "Moving/Stationary";
CM_ SG_ 80 FLR2RdrDetn000To004DynPrpty1 "Moving/Stationary";
CM_ SG_ 80 FLR2RdrDetn000To004DynPrpty2 "Moving/Stationary";
CM_ SG_ 80 FLR2RdrDetn000To004DynPrpty3 "Moving/Stationary";
CM_ SG_ 80 FLR2RdrDetn000To004DynPrpty4 "Moving/Stationary";
CM_ SG_ 80 FLR2RdrDetn000To004EleAng0 "Elevation angle";
CM_ SG_ 80 FLR2RdrDetn000To004EleAng1 "Elevation angle";
CM_ SG_ 80 FLR2RdrDetn000To004EleAng2 "Elevation angle";
CM_ SG_ 80 FLR2RdrDetn000To004EleAng3 "Elevation angle";
CM_ SG_ 80 FLR2RdrDetn000To004EleAng4 "Elevation angle";
CM_ SG_ 80 FLR2RdrDetn000To004Mode0 "What chirp mode the detection is from";
CM_ SG_ 80 FLR2RdrDetn000To004Mode1 "What chirp mode the detection is from";
CM_ SG_ 80 FLR2RdrDetn000To004Mode2 "What chirp mode the detection is from";
CM_ SG_ 80 FLR2RdrDetn000To004Mode3 "What chirp mode the detection is from";
CM_ SG_ 80 FLR2RdrDetn000To004Mode4 "What chirp mode the detection is from";
CM_ SG_ 80 FLR2RdrDetn000To004Quality0 "Quality";
CM_ SG_ 80 FLR2RdrDetn000To004Quality1 "Quality";
CM_ SG_ 80 FLR2RdrDetn000To004Quality2 "Quality";
CM_ SG_ 80 FLR2RdrDetn000To004Quality3 "Quality";
CM_ SG_ 80 FLR2RdrDetn000To004Quality4 "Quality";
CM_ SG_ 80 FLR2RdrDetn000To004Range0 "Range from sensor to object";
CM_ SG_ 80 FLR2RdrDetn000To004Range1 "Range from sensor to object";
CM_ SG_ 80 FLR2RdrDetn000To004Range2 "Range from sensor to object";
CM_ SG_ 80 FLR2RdrDetn000To004Range3 "Range from sensor to object";
CM_ SG_ 80 FLR2RdrDetn000To004Range4 "Range from sensor to object";
CM_ SG_ 80 FLR2RdrDetn000To004RCS0 "RCS";
CM_ SG_ 80 FLR2RdrDetn000To004RCS1 "RCS";
CM_ SG_ 80 FLR2RdrDetn000To004RCS2 "RCS";
CM_ SG_ 80 FLR2RdrDetn000To004RCS3 "RCS";
CM_ SG_ 80 FLR2RdrDetn000To004RCS4 "RCS";
CM_ SG_ 80 FLR2RdrDetn000To004RngRt0 "Speed towards/away from the sensor";
CM_ SG_ 80 FLR2RdrDetn000To004RngRt1 "Speed towards/away from the sensor";
CM_ SG_ 80 FLR2RdrDetn000To004RngRt2 "Speed towards/away from the sensor";
CM_ SG_ 80 FLR2RdrDetn000To004RngRt3 "Speed towards/away from the sensor";
CM_ SG_ 80 FLR2RdrDetn000To004RngRt4 "Speed towards/away from the sensor";
CM_ SG_ 80 FLR2RdrDetn000To004ScanID "Value to tie status, detection data and object data frames together";
CM_ SG_ 80 FLR2RdrDetn000To004SNR0 "Signal to Noise Ratio";
CM_ SG_ 80 FLR2RdrDetn000To004SNR1 "Signal to Noise Ration";
CM_ SG_ 80 FLR2RdrDetn000To004SNR2 "Signal to Noise Ration";
CM_ SG_ 80 FLR2RdrDetn000To004SNR3 "Signal to Noise Ration";
CM_ SG_ 80 FLR2RdrDetn000To004SNR4 "Signal to Noise Ration";
CM_ SG_ 83 FLR2RdrDetn005To009AziAng0 "Azimuth Angle";
CM_ SG_ 83 FLR2RdrDetn005To009AziAng1 "Azimuth Angle";
CM_ SG_ 83 FLR2RdrDetn005To009AziAng2 "Azimuth Angle";
CM_ SG_ 83 FLR2RdrDetn005To009AziAng3 "Azimuth Angle";
CM_ SG_ 83 FLR2RdrDetn005To009AziAng4 "Azimuth Angle";
CM_ SG_ 83 FLR2RdrDetn005To009DynPrpty0 "Moving/Stationary";
CM_ SG_ 83 FLR2RdrDetn005To009DynPrpty1 "Moving/Stationary";
CM_ SG_ 83 FLR2RdrDetn005To009DynPrpty2 "Moving/Stationary";
CM_ SG_ 83 FLR2RdrDetn005To009DynPrpty3 "Moving/Stationary";
CM_ SG_ 83 FLR2RdrDetn005To009DynPrpty4 "Moving/Stationary";
CM_ SG_ 83 FLR2RdrDetn005To009EleAng0 "Elevation angle";
CM_ SG_ 83 FLR2RdrDetn005To009EleAng1 "Elevation angle";
CM_ SG_ 83 FLR2RdrDetn005To009EleAng2 "Elevation angle";
CM_ SG_ 83 FLR2RdrDetn005To009EleAng3 "Elevation angle";
CM_ SG_ 83 FLR2RdrDetn005To009EleAng4 "Elevation angle";
CM_ SG_ 83 FLR2RdrDetn005To009Mode0 "What chirp mode the detection is from";
CM_ SG_ 83 FLR2RdrDetn005To009Mode1 "What chirp mode the detection is from";
CM_ SG_ 83 FLR2RdrDetn005To009Mode2 "What chirp mode the detection is from";
CM_ SG_ 83 FLR2RdrDetn005To009Mode3 "What chirp mode the detection is from";
CM_ SG_ 83 FLR2RdrDetn005To009Mode4 "What chirp mode the detection is from";
CM_ SG_ 83 FLR2RdrDetn005To009Quality0 "Quality";
CM_ SG_ 83 FLR2RdrDetn005To009Quality1 "Quality";
CM_ SG_ 83 FLR2RdrDetn005To009Quality2 "Quality";
CM_ SG_ 83 FLR2RdrDetn005To009Quality3 "Quality";
CM_ SG_ 83 FLR2RdrDetn005To009Quality4 "Quality";
CM_ SG_ 83 FLR2RdrDetn005To009Range0 "Range from sensor to object";
CM_ SG_ 83 FLR2RdrDetn005To009Range1 "Range from sensor to object";
CM_ SG_ 83 FLR2RdrDetn005To009Range2 "Range from sensor to object";
CM_ SG_ 83 FLR2RdrDetn005To009Range3 "Range from sensor to object";
CM_ SG_ 83 FLR2RdrDetn005To009Range4 "Range from sensor to object";
CM_ SG_ 83 FLR2RdrDetn005To009RCS0 "RCS";
CM_ SG_ 83 FLR2RdrDetn005To009RCS1 "RCS";
CM_ SG_ 83 FLR2RdrDetn005To009RCS2 "RCS";
CM_ SG_ 83 FLR2RdrDetn005To009RCS3 "RCS";
CM_ SG_ 83 FLR2RdrDetn005To009RCS4 "RCS";
CM_ SG_ 83 FLR2RdrDetn005To009RngRt0 "Speed towards/away from the sensor";
CM_ SG_ 83 FLR2RdrDetn005To009RngRt1 "Speed towards/away from the sensor";
CM_ SG_ 83 FLR2RdrDetn005To009RngRt2 "Speed towards/away from the sensor";
CM_ SG_ 83 FLR2RdrDetn005To009RngRt3 "Speed towards/away from the sensor";
CM_ SG_ 83 FLR2RdrDetn005To009RngRt4 "Speed towards/away from the sensor";
CM_ SG_ 83 FLR2RdrDetn005To009ScanID "Value to tie status, detection data and object data frames together";
CM_ SG_ 83 FLR2RdrDetn005To009SNR0 "Signal to Noise Ratio";
CM_ SG_ 83 FLR2RdrDetn005To009SNR1 "Signal to Noise Ration";
CM_ SG_ 83 FLR2RdrDetn005To009SNR2 "Signal to Noise Ration";
CM_ SG_ 83 FLR2RdrDetn005To009SNR3 "Signal to Noise Ration";
CM_ SG_ 83 FLR2RdrDetn005To009SNR4 "Signal to Noise Ration";
CM_ SG_ 86 FLR2RdrDetn010To014AziAng0 "Azimuth Angle";
CM_ SG_ 86 FLR2RdrDetn010To014AziAng1 "Azimuth Angle";
CM_ SG_ 86 FLR2RdrDetn010To014AziAng2 "Azimuth Angle";
CM_ SG_ 86 FLR2RdrDetn010To014AziAng3 "Azimuth Angle";
CM_ SG_ 86 FLR2RdrDetn010To014AziAng4 "Azimuth Angle";
CM_ SG_ 86 FLR2RdrDetn010To014DynPrpty0 "Moving/Stationary";
CM_ SG_ 86 FLR2RdrDetn010To014DynPrpty1 "Moving/Stationary";
CM_ SG_ 86 FLR2RdrDetn010To014DynPrpty2 "Moving/Stationary";
CM_ SG_ 86 FLR2RdrDetn010To014DynPrpty3 "Moving/Stationary";
CM_ SG_ 86 FLR2RdrDetn010To014DynPrpty4 "Moving/Stationary";
CM_ SG_ 86 FLR2RdrDetn010To014EleAng0 "Elevation angle";
CM_ SG_ 86 FLR2RdrDetn010To014EleAng1 "Elevation angle";
CM_ SG_ 86 FLR2RdrDetn010To014EleAng2 "Elevation angle";
CM_ SG_ 86 FLR2RdrDetn010To014EleAng3 "Elevation angle";
CM_ SG_ 86 FLR2RdrDetn010To014EleAng4 "Elevation angle";
CM_ SG_ 86 FLR2RdrDetn010To014Mode0 "What chirp mode the detection is from";
CM_ SG_ 86 FLR2RdrDetn010To014Mode1 "What chirp mode the detection is from";
CM_ SG_ 86 FLR2RdrDetn010To014Mode2 "What chirp mode the detection is from";
CM_ SG_ 86 FLR2RdrDetn010To014Mode3 "What chirp mode the detection is from";
CM_ SG_ 86 FLR2RdrDetn010To014Mode4 "What chirp mode the detection is from";
CM_ SG_ 86 FLR2RdrDetn010To014Quality0 "Quality";
CM_ SG_ 86 FLR2RdrDetn010To014Quality1 "Quality";
CM_ SG_ 86 FLR2RdrDetn010To014Quality2 "Quality";
CM_ SG_ 86 FLR2RdrDetn010To014Quality3 "Quality";
CM_ SG_ 86 FLR2RdrDetn010To014Quality4 "Quality";
CM_ SG_ 86 FLR2RdrDetn010To014Range0 "Range from sensor to object";
CM_ SG_ 86 FLR2RdrDetn010To014Range1 "Range from sensor to object";
CM_ SG_ 86 FLR2RdrDetn010To014Range2 "Range from sensor to object";
CM_ SG_ 86 FLR2RdrDetn010To014Range3 "Range from sensor to object";
CM_ SG_ 86 FLR2RdrDetn010To014Range4 "Range from sensor to object";
CM_ SG_ 86 FLR2RdrDetn010To014RCS0 "RCS";
CM_ SG_ 86 FLR2RdrDetn010To014RCS1 "RCS";
CM_ SG_ 86 FLR2RdrDetn010To014RCS2 "RCS";
CM_ SG_ 86 FLR2RdrDetn010To014RCS3 "RCS";
CM_ SG_ 86 FLR2RdrDetn010To014RCS4 "RCS";
CM_ SG_ 86 FLR2RdrDetn010To014RngRt0 "Speed towards/away from the sensor";
CM_ SG_ 86 FLR2RdrDetn010To014RngRt1 "Speed towards/away from the sensor";
CM_ SG_ 86 FLR2RdrDetn010To014RngRt2 "Speed towards/away from the sensor";
CM_ SG_ 86 FLR2RdrDetn010To014RngRt3 "Speed towards/away from the sensor";
CM_ SG_ 86 FLR2RdrDetn010To014RngRt4 "Speed towards/away from the sensor";
CM_ SG_ 86 FLR2RdrDetn010To014ScanID "Value to tie status, detection data and object data frames together";
CM_ SG_ 86 FLR2RdrDetn010To014SNR0 "Signal to Noise Ratio";
CM_ SG_ 86 FLR2RdrDetn010To014SNR1 "Signal to Noise Ration";
CM_ SG_ 86 FLR2RdrDetn010To014SNR2 "Signal to Noise Ration";
CM_ SG_ 86 FLR2RdrDetn010To014SNR3 "Signal to Noise Ration";
CM_ SG_ 86 FLR2RdrDetn010To014SNR4 "Signal to Noise Ration";
CM_ SG_ 89 FLR2RdrDetn015To019AziAng0 "Azimuth Angle";
CM_ SG_ 89 FLR2RdrDetn015To019AziAng1 "Azimuth Angle";
CM_ SG_ 89 FLR2RdrDetn015To019AziAng2 "Azimuth Angle";
CM_ SG_ 89 FLR2RdrDetn015To019AziAng3 "Azimuth Angle";
CM_ SG_ 89 FLR2RdrDetn015To019AziAng4 "Azimuth Angle";
CM_ SG_ 89 FLR2RdrDetn015To019DynPrpty0 "Moving/Stationary";
CM_ SG_ 89 FLR2RdrDetn015To019DynPrpty1 "Moving/Stationary";
CM_ SG_ 89 FLR2RdrDetn015To019DynPrpty2 "Moving/Stationary";
CM_ SG_ 89 FLR2RdrDetn015To019DynPrpty3 "Moving/Stationary";
CM_ SG_ 89 FLR2RdrDetn015To019DynPrpty4 "Moving/Stationary";
CM_ SG_ 89 FLR2RdrDetn015To019EleAng0 "Elevation angle";
CM_ SG_ 89 FLR2RdrDetn015To019EleAng1 "Elevation angle";
CM_ SG_ 89 FLR2RdrDetn015To019EleAng2 "Elevation angle";
CM_ SG_ 89 FLR2RdrDetn015To019EleAng3 "Elevation angle";
CM_ SG_ 89 FLR2RdrDetn015To019EleAng4 "Elevation angle";
CM_ SG_ 89 FLR2RdrDetn015To019Mode0 "What chirp mode the detection is from";
CM_ SG_ 89 FLR2RdrDetn015To019Mode1 "What chirp mode the detection is from";
CM_ SG_ 89 FLR2RdrDetn015To019Mode2 "What chirp mode the detection is from";
CM_ SG_ 89 FLR2RdrDetn015To019Mode3 "What chirp mode the detection is from";
CM_ SG_ 89 FLR2RdrDetn015To019Mode4 "What chirp mode the detection is from";
CM_ SG_ 89 FLR2RdrDetn015To019Quality0 "Quality";
CM_ SG_ 89 FLR2RdrDetn015To019Quality1 "Quality";
CM_ SG_ 89 FLR2RdrDetn015To019Quality2 "Quality";
CM_ SG_ 89 FLR2RdrDetn015To019Quality3 "Quality";
CM_ SG_ 89 FLR2RdrDetn015To019Quality4 "Quality";
CM_ SG_ 89 FLR2RdrDetn015To019Range0 "Range from sensor to object";
CM_ SG_ 89 FLR2RdrDetn015To019Range1 "Range from sensor to object";
CM_ SG_ 89 FLR2RdrDetn015To019Range2 "Range from sensor to object";
CM_ SG_ 89 FLR2RdrDetn015To019Range3 "Range from sensor to object";
CM_ SG_ 89 FLR2RdrDetn015To019Range4 "Range from sensor to object";
CM_ SG_ 89 FLR2RdrDetn015To019RCS0 "RCS";
CM_ SG_ 89 FLR2RdrDetn015To019RCS1 "RCS";
CM_ SG_ 89 FLR2RdrDetn015To019RCS2 "RCS";
CM_ SG_ 89 FLR2RdrDetn015To019RCS3 "RCS";
CM_ SG_ 89 FLR2RdrDetn015To019RCS4 "RCS";
CM_ SG_ 89 FLR2RdrDetn015To019RngRt0 "Speed towards/away from the sensor";
CM_ SG_ 89 FLR2RdrDetn015To019RngRt1 "Speed towards/away from the sensor";
CM_ SG_ 89 FLR2RdrDetn015To019RngRt2 "Speed towards/away from the sensor";
CM_ SG_ 89 FLR2RdrDetn015To019RngRt3 "Speed towards/away from the sensor";
CM_ SG_ 89 FLR2RdrDetn015To019RngRt4 "Speed towards/away from the sensor";
CM_ SG_ 89 FLR2RdrDetn015To019ScanID "Value to tie status, detection data and object data frames together";
CM_ SG_ 89 FLR2RdrDetn015To019SNR0 "Signal to Noise Ratio";
CM_ SG_ 89 FLR2RdrDetn015To019SNR1 "Signal to Noise Ration";
CM_ SG_ 89 FLR2RdrDetn015To019SNR2 "Signal to Noise Ration";
CM_ SG_ 89 FLR2RdrDetn015To019SNR3 "Signal to Noise Ration";
CM_ SG_ 89 FLR2RdrDetn015To019SNR4 "Signal to Noise Ration";
CM_ SG_ 92 FLR2RdrDetn020To024AziAng0 "Azimuth Angle";
CM_ SG_ 92 FLR2RdrDetn020To024AziAng1 "Azimuth Angle";
CM_ SG_ 92 FLR2RdrDetn020To024AziAng2 "Azimuth Angle";
CM_ SG_ 92 FLR2RdrDetn020To024AziAng3 "Azimuth Angle";
CM_ SG_ 92 FLR2RdrDetn020To024AziAng4 "Azimuth Angle";
CM_ SG_ 92 FLR2RdrDetn020To024DynPrpty0 "Moving/Stationary";
CM_ SG_ 92 FLR2RdrDetn020To024DynPrpty1 "Moving/Stationary";
CM_ SG_ 92 FLR2RdrDetn020To024DynPrpty2 "Moving/Stationary";
CM_ SG_ 92 FLR2RdrDetn020To024DynPrpty3 "Moving/Stationary";
CM_ SG_ 92 FLR2RdrDetn020To024DynPrpty4 "Moving/Stationary";
CM_ SG_ 92 FLR2RdrDetn020To024EleAng0 "Elevation angle";
CM_ SG_ 92 FLR2RdrDetn020To024EleAng1 "Elevation angle";
CM_ SG_ 92 FLR2RdrDetn020To024EleAng2 "Elevation angle";
CM_ SG_ 92 FLR2RdrDetn020To024EleAng3 "Elevation angle";
CM_ SG_ 92 FLR2RdrDetn020To024EleAng4 "Elevation angle";
CM_ SG_ 92 FLR2RdrDetn020To024Mode0 "What chirp mode the detection is from";
CM_ SG_ 92 FLR2RdrDetn020To024Mode1 "What chirp mode the detection is from";
CM_ SG_ 92 FLR2RdrDetn020To024Mode2 "What chirp mode the detection is from";
CM_ SG_ 92 FLR2RdrDetn020To024Mode3 "What chirp mode the detection is from";
CM_ SG_ 92 FLR2RdrDetn020To024Mode4 "What chirp mode the detection is from";
CM_ SG_ 92 FLR2RdrDetn020To024Quality0 "Quality";
CM_ SG_ 92 FLR2RdrDetn020To024Quality1 "Quality";
CM_ SG_ 92 FLR2RdrDetn020To024Quality2 "Quality";
CM_ SG_ 92 FLR2RdrDetn020To024Quality3 "Quality";
CM_ SG_ 92 FLR2RdrDetn020To024Quality4 "Quality";
CM_ SG_ 92 FLR2RdrDetn020To024Range0 "Range from sensor to object";
CM_ SG_ 92 FLR2RdrDetn020To024Range1 "Range from sensor to object";
CM_ SG_ 92 FLR2RdrDetn020To024Range2 "Range from sensor to object";
CM_ SG_ 92 FLR2RdrDetn020To024Range3 "Range from sensor to object";
CM_ SG_ 92 FLR2RdrDetn020To024Range4 "Range from sensor to object";
CM_ SG_ 92 FLR2RdrDetn020To024RCS0 "RCS";
CM_ SG_ 92 FLR2RdrDetn020To024RCS1 "RCS";
CM_ SG_ 92 FLR2RdrDetn020To024RCS2 "RCS";
CM_ SG_ 92 FLR2RdrDetn020To024RCS3 "RCS";
CM_ SG_ 92 FLR2RdrDetn020To024RCS4 "RCS";
CM_ SG_ 92 FLR2RdrDetn020To024RngRt0 "Speed towards/away from the sensor";
CM_ SG_ 92 FLR2RdrDetn020To024RngRt1 "Speed towards/away from the sensor";
CM_ SG_ 92 FLR2RdrDetn020To024RngRt2 "Speed towards/away from the sensor";
CM_ SG_ 92 FLR2RdrDetn020To024RngRt3 "Speed towards/away from the sensor";
CM_ SG_ 92 FLR2RdrDetn020To024RngRt4 "Speed towards/away from the sensor";
CM_ SG_ 92 FLR2RdrDetn020To024ScanID "Value to tie status, detection data and object data frames together";
CM_ SG_ 92 FLR2RdrDetn020To024SNR0 "Signal to Noise Ratio";
CM_ SG_ 92 FLR2RdrDetn020To024SNR1 "Signal to Noise Ration";
CM_ SG_ 92 FLR2RdrDetn020To024SNR2 "Signal to Noise Ration";
CM_ SG_ 92 FLR2RdrDetn020To024SNR3 "Signal to Noise Ration";
CM_ SG_ 92 FLR2RdrDetn020To024SNR4 "Signal to Noise Ration";
CM_ SG_ 96 FLR2RdrDetn025To029AziAng0 "Azimuth Angle";
CM_ SG_ 96 FLR2RdrDetn025To029AziAng1 "Azimuth Angle";
CM_ SG_ 96 FLR2RdrDetn025To029AziAng2 "Azimuth Angle";
CM_ SG_ 96 FLR2RdrDetn025To029AziAng3 "Azimuth Angle";
CM_ SG_ 96 FLR2RdrDetn025To029AziAng4 "Azimuth Angle";
CM_ SG_ 96 FLR2RdrDetn025To029DynPrpty0 "Moving/Stationary";
CM_ SG_ 96 FLR2RdrDetn025To029DynPrpty1 "Moving/Stationary";
CM_ SG_ 96 FLR2RdrDetn025To029DynPrpty2 "Moving/Stationary";
CM_ SG_ 96 FLR2RdrDetn025To029DynPrpty3 "Moving/Stationary";
CM_ SG_ 96 FLR2RdrDetn025To029DynPrpty4 "Moving/Stationary";
CM_ SG_ 96 FLR2RdrDetn025To029EleAng0 "Elevation angle";
CM_ SG_ 96 FLR2RdrDetn025To029EleAng1 "Elevation angle";
CM_ SG_ 96 FLR2RdrDetn025To029EleAng2 "Elevation angle";
CM_ SG_ 96 FLR2RdrDetn025To029EleAng3 "Elevation angle";
CM_ SG_ 96 FLR2RdrDetn025To029EleAng4 "Elevation angle";
CM_ SG_ 96 FLR2RdrDetn025To029Mode0 "What chirp mode the detection is from";
CM_ SG_ 96 FLR2RdrDetn025To029Mode1 "What chirp mode the detection is from";
CM_ SG_ 96 FLR2RdrDetn025To029Mode2 "What chirp mode the detection is from";
CM_ SG_ 96 FLR2RdrDetn025To029Mode3 "What chirp mode the detection is from";
CM_ SG_ 96 FLR2RdrDetn025To029Mode4 "What chirp mode the detection is from";
CM_ SG_ 96 FLR2RdrDetn025To029Quality0 "Quality";
CM_ SG_ 96 FLR2RdrDetn025To029Quality1 "Quality";
CM_ SG_ 96 FLR2RdrDetn025To029Quality2 "Quality";
CM_ SG_ 96 FLR2RdrDetn025To029Quality3 "Quality";
CM_ SG_ 96 FLR2RdrDetn025To029Quality4 "Quality";
CM_ SG_ 96 FLR2RdrDetn025To029Range0 "Range from sensor to object";
CM_ SG_ 96 FLR2RdrDetn025To029Range1 "Range from sensor to object";
CM_ SG_ 96 FLR2RdrDetn025To029Range2 "Range from sensor to object";
CM_ SG_ 96 FLR2RdrDetn025To029Range3 "Range from sensor to object";
CM_ SG_ 96 FLR2RdrDetn025To029Range4 "Range from sensor to object";
CM_ SG_ 96 FLR2RdrDetn025To029RCS0 "RCS";
CM_ SG_ 96 FLR2RdrDetn025To029RCS1 "RCS";
CM_ SG_ 96 FLR2RdrDetn025To029RCS2 "RCS";
CM_ SG_ 96 FLR2RdrDetn025To029RCS3 "RCS";
CM_ SG_ 96 FLR2RdrDetn025To029RCS4 "RCS";
CM_ SG_ 96 FLR2RdrDetn025To029RngRt0 "Speed towards/away from the sensor";
CM_ SG_ 96 FLR2RdrDetn025To029RngRt1 "Speed towards/away from the sensor";
CM_ SG_ 96 FLR2RdrDetn025To029RngRt2 "Speed towards/away from the sensor";
CM_ SG_ 96 FLR2RdrDetn025To029RngRt3 "Speed towards/away from the sensor";
CM_ SG_ 96 FLR2RdrDetn025To029RngRt4 "Speed towards/away from the sensor";
CM_ SG_ 96 FLR2RdrDetn025To029ScanID "Value to tie status, detection data and object data frames together";
CM_ SG_ 96 FLR2RdrDetn025To029SNR0 "Signal to Noise Ratio";
CM_ SG_ 96 FLR2RdrDetn025To029SNR1 "Signal to Noise Ration";
CM_ SG_ 96 FLR2RdrDetn025To029SNR2 "Signal to Noise Ration";
CM_ SG_ 96 FLR2RdrDetn025To029SNR3 "Signal to Noise Ration";
CM_ SG_ 96 FLR2RdrDetn025To029SNR4 "Signal to Noise Ration";
CM_ SG_ 99 FLR2RdrDetn030To034AziAng0 "Azimuth Angle";
CM_ SG_ 99 FLR2RdrDetn030To034AziAng1 "Azimuth Angle";
CM_ SG_ 99 FLR2RdrDetn030To034AziAng2 "Azimuth Angle";
CM_ SG_ 99 FLR2RdrDetn030To034AziAng3 "Azimuth Angle";
CM_ SG_ 99 FLR2RdrDetn030To034AziAng4 "Azimuth Angle";
CM_ SG_ 99 FLR2RdrDetn030To034DynPrpty0 "Moving/Stationary";
CM_ SG_ 99 FLR2RdrDetn030To034DynPrpty1 "Moving/Stationary";
CM_ SG_ 99 FLR2RdrDetn030To034DynPrpty2 "Moving/Stationary";
CM_ SG_ 99 FLR2RdrDetn030To034DynPrpty3 "Moving/Stationary";
CM_ SG_ 99 FLR2RdrDetn030To034DynPrpty4 "Moving/Stationary";
CM_ SG_ 99 FLR2RdrDetn030To034EleAng0 "Elevation angle";
CM_ SG_ 99 FLR2RdrDetn030To034EleAng1 "Elevation angle";
CM_ SG_ 99 FLR2RdrDetn030To034EleAng2 "Elevation angle";
CM_ SG_ 99 FLR2RdrDetn030To034EleAng3 "Elevation angle";
CM_ SG_ 99 FLR2RdrDetn030To034EleAng4 "Elevation angle";
CM_ SG_ 99 FLR2RdrDetn030To034Mode0 "What chirp mode the detection is from";
CM_ SG_ 99 FLR2RdrDetn030To034Mode1 "What chirp mode the detection is from";
CM_ SG_ 99 FLR2RdrDetn030To034Mode2 "What chirp mode the detection is from";
CM_ SG_ 99 FLR2RdrDetn030To034Mode3 "What chirp mode the detection is from";
CM_ SG_ 99 FLR2RdrDetn030To034Mode4 "What chirp mode the detection is from";
CM_ SG_ 99 FLR2RdrDetn030To034Quality0 "Quality";
CM_ SG_ 99 FLR2RdrDetn030To034Quality1 "Quality";
CM_ SG_ 99 FLR2RdrDetn030To034Quality2 "Quality";
CM_ SG_ 99 FLR2RdrDetn030To034Quality3 "Quality";
CM_ SG_ 99 FLR2RdrDetn030To034Quality4 "Quality";
CM_ SG_ 99 FLR2RdrDetn030To034Range0 "Range from sensor to object";
CM_ SG_ 99 FLR2RdrDetn030To034Range1 "Range from sensor to object";
CM_ SG_ 99 FLR2RdrDetn030To034Range2 "Range from sensor to object";
CM_ SG_ 99 FLR2RdrDetn030To034Range3 "Range from sensor to object";
CM_ SG_ 99 FLR2RdrDetn030To034Range4 "Range from sensor to object";
CM_ SG_ 99 FLR2RdrDetn030To034RCS0 "RCS";
CM_ SG_ 99 FLR2RdrDetn030To034RCS1 "RCS";
CM_ SG_ 99 FLR2RdrDetn030To034RCS2 "RCS";
CM_ SG_ 99 FLR2RdrDetn030To034RCS3 "RCS";
CM_ SG_ 99 FLR2RdrDetn030To034RCS4 "RCS";
CM_ SG_ 99 FLR2RdrDetn030To034RngRt0 "Speed towards/away from the sensor";
CM_ SG_ 99 FLR2RdrDetn030To034RngRt1 "Speed towards/away from the sensor";
CM_ SG_ 99 FLR2RdrDetn030To034RngRt2 "Speed towards/away from the sensor";
CM_ SG_ 99 FLR2RdrDetn030To034RngRt3 "Speed towards/away from the sensor";
CM_ SG_ 99 FLR2RdrDetn030To034RngRt4 "Speed towards/away from the sensor";
CM_ SG_ 99 FLR2RdrDetn030To034ScanID "Value to tie status, detection data and object data frames together";
CM_ SG_ 99 FLR2RdrDetn030To034SNR0 "Signal to Noise Ratio";
CM_ SG_ 99 FLR2RdrDetn030To034SNR1 "Signal to Noise Ration";
CM_ SG_ 99 FLR2RdrDetn030To034SNR2 "Signal to Noise Ration";
CM_ SG_ 99 FLR2RdrDetn030To034SNR3 "Signal to Noise Ration";
CM_ SG_ 99 FLR2RdrDetn030To034SNR4 "Signal to Noise Ration";
CM_ SG_ 102 FLR2RdrDetn035To039AziAng0 "Azimuth Angle";
CM_ SG_ 102 FLR2RdrDetn035To039AziAng1 "Azimuth Angle";
CM_ SG_ 102 FLR2RdrDetn035To039AziAng2 "Azimuth Angle";
CM_ SG_ 102 FLR2RdrDetn035To039AziAng3 "Azimuth Angle";
CM_ SG_ 102 FLR2RdrDetn035To039AziAng4 "Azimuth Angle";
CM_ SG_ 102 FLR2RdrDetn035To039DynPrpty0 "Moving/Stationary";
CM_ SG_ 102 FLR2RdrDetn035To039DynPrpty1 "Moving/Stationary";
CM_ SG_ 102 FLR2RdrDetn035To039DynPrpty2 "Moving/Stationary";
CM_ SG_ 102 FLR2RdrDetn035To039DynPrpty3 "Moving/Stationary";
CM_ SG_ 102 FLR2RdrDetn035To039DynPrpty4 "Moving/Stationary";
CM_ SG_ 102 FLR2RdrDetn035To039EleAng0 "Elevation angle";
CM_ SG_ 102 FLR2RdrDetn035To039EleAng1 "Elevation angle";
CM_ SG_ 102 FLR2RdrDetn035To039EleAng2 "Elevation angle";
CM_ SG_ 102 FLR2RdrDetn035To039EleAng3 "Elevation angle";
CM_ SG_ 102 FLR2RdrDetn035To039EleAng4 "Elevation angle";
CM_ SG_ 102 FLR2RdrDetn035To039Mode0 "What chirp mode the detection is from";
CM_ SG_ 102 FLR2RdrDetn035To039Mode1 "What chirp mode the detection is from";
CM_ SG_ 102 FLR2RdrDetn035To039Mode2 "What chirp mode the detection is from";
CM_ SG_ 102 FLR2RdrDetn035To039Mode3 "What chirp mode the detection is from";
CM_ SG_ 102 FLR2RdrDetn035To039Mode4 "What chirp mode the detection is from";
CM_ SG_ 102 FLR2RdrDetn035To039Quality0 "Quality";
CM_ SG_ 102 FLR2RdrDetn035To039Quality1 "Quality";
CM_ SG_ 102 FLR2RdrDetn035To039Quality2 "Quality";
CM_ SG_ 102 FLR2RdrDetn035To039Quality3 "Quality";
CM_ SG_ 102 FLR2RdrDetn035To039Quality4 "Quality";
CM_ SG_ 102 FLR2RdrDetn035To039Range0 "Range from sensor to object";
CM_ SG_ 102 FLR2RdrDetn035To039Range1 "Range from sensor to object";
CM_ SG_ 102 FLR2RdrDetn035To039Range2 "Range from sensor to object";
CM_ SG_ 102 FLR2RdrDetn035To039Range3 "Range from sensor to object";
CM_ SG_ 102 FLR2RdrDetn035To039Range4 "Range from sensor to object";
CM_ SG_ 102 FLR2RdrDetn035To039RCS0 "RCS";
CM_ SG_ 102 FLR2RdrDetn035To039RCS1 "RCS";
CM_ SG_ 102 FLR2RdrDetn035To039RCS2 "RCS";
CM_ SG_ 102 FLR2RdrDetn035To039RCS3 "RCS";
CM_ SG_ 102 FLR2RdrDetn035To039RCS4 "RCS";
CM_ SG_ 102 FLR2RdrDetn035To039RngRt0 "Speed towards/away from the sensor";
CM_ SG_ 102 FLR2RdrDetn035To039RngRt1 "Speed towards/away from the sensor";
CM_ SG_ 102 FLR2RdrDetn035To039RngRt2 "Speed towards/away from the sensor";
CM_ SG_ 102 FLR2RdrDetn035To039RngRt3 "Speed towards/away from the sensor";
CM_ SG_ 102 FLR2RdrDetn035To039RngRt4 "Speed towards/away from the sensor";
CM_ SG_ 102 FLR2RdrDetn035To039ScanID "Value to tie status, detection data and object data frames together";
CM_ SG_ 102 FLR2RdrDetn035To039SNR0 "Signal to Noise Ratio";
CM_ SG_ 102 FLR2RdrDetn035To039SNR1 "Signal to Noise Ration";
CM_ SG_ 102 FLR2RdrDetn035To039SNR2 "Signal to Noise Ration";
CM_ SG_ 102 FLR2RdrDetn035To039SNR3 "Signal to Noise Ration";
CM_ SG_ 102 FLR2RdrDetn035To039SNR4 "Signal to Noise Ration";
CM_ SG_ 105 FLR2RdrDetn040To044AziAng0 "Azimuth Angle";
CM_ SG_ 105 FLR2RdrDetn040To044AziAng1 "Azimuth Angle";
CM_ SG_ 105 FLR2RdrDetn040To044AziAng2 "Azimuth Angle";
CM_ SG_ 105 FLR2RdrDetn040To044AziAng3 "Azimuth Angle";
CM_ SG_ 105 FLR2RdrDetn040To044AziAng4 "Azimuth Angle";
CM_ SG_ 105 FLR2RdrDetn040To044DynPrpty0 "Moving/Stationary";
CM_ SG_ 105 FLR2RdrDetn040To044DynPrpty1 "Moving/Stationary";
CM_ SG_ 105 FLR2RdrDetn040To044DynPrpty2 "Moving/Stationary";
CM_ SG_ 105 FLR2RdrDetn040To044DynPrpty3 "Moving/Stationary";
CM_ SG_ 105 FLR2RdrDetn040To044DynPrpty4 "Moving/Stationary";
CM_ SG_ 105 FLR2RdrDetn040To044EleAng0 "Elevation angle";
CM_ SG_ 105 FLR2RdrDetn040To044EleAng1 "Elevation angle";
CM_ SG_ 105 FLR2RdrDetn040To044EleAng2 "Elevation angle";
CM_ SG_ 105 FLR2RdrDetn040To044EleAng3 "Elevation angle";
CM_ SG_ 105 FLR2RdrDetn040To044EleAng4 "Elevation angle";
CM_ SG_ 105 FLR2RdrDetn040To044Mode0 "What chirp mode the detection is from";
CM_ SG_ 105 FLR2RdrDetn040To044Mode1 "What chirp mode the detection is from";
CM_ SG_ 105 FLR2RdrDetn040To044Mode2 "What chirp mode the detection is from";
CM_ SG_ 105 FLR2RdrDetn040To044Mode3 "What chirp mode the detection is from";
CM_ SG_ 105 FLR2RdrDetn040To044Mode4 "What chirp mode the detection is from";
CM_ SG_ 105 FLR2RdrDetn040To044Quality0 "Quality";
CM_ SG_ 105 FLR2RdrDetn040To044Quality1 "Quality";
CM_ SG_ 105 FLR2RdrDetn040To044Quality2 "Quality";
CM_ SG_ 105 FLR2RdrDetn040To044Quality3 "Quality";
CM_ SG_ 105 FLR2RdrDetn040To044Quality4 "Quality";
CM_ SG_ 105 FLR2RdrDetn040To044Range0 "Range from sensor to object";
CM_ SG_ 105 FLR2RdrDetn040To044Range1 "Range from sensor to object";
CM_ SG_ 105 FLR2RdrDetn040To044Range2 "Range from sensor to object";
CM_ SG_ 105 FLR2RdrDetn040To044Range3 "Range from sensor to object";
CM_ SG_ 105 FLR2RdrDetn040To044Range4 "Range from sensor to object";
CM_ SG_ 105 FLR2RdrDetn040To044RCS0 "RCS";
CM_ SG_ 105 FLR2RdrDetn040To044RCS1 "RCS";
CM_ SG_ 105 FLR2RdrDetn040To044RCS2 "RCS";
CM_ SG_ 105 FLR2RdrDetn040To044RCS3 "RCS";
CM_ SG_ 105 FLR2RdrDetn040To044RCS4 "RCS";
CM_ SG_ 105 FLR2RdrDetn040To044RngRt0 "Speed towards/away from the sensor";
CM_ SG_ 105 FLR2RdrDetn040To044RngRt1 "Speed towards/away from the sensor";
CM_ SG_ 105 FLR2RdrDetn040To044RngRt2 "Speed towards/away from the sensor";
CM_ SG_ 105 FLR2RdrDetn040To044RngRt3 "Speed towards/away from the sensor";
CM_ SG_ 105 FLR2RdrDetn040To044RngRt4 "Speed towards/away from the sensor";
CM_ SG_ 105 FLR2RdrDetn040To044ScanID "Value to tie status, detection data and object data frames together";
CM_ SG_ 105 FLR2RdrDetn040To044SNR0 "Signal to Noise Ratio";
CM_ SG_ 105 FLR2RdrDetn040To044SNR1 "Signal to Noise Ration";
CM_ SG_ 105 FLR2RdrDetn040To044SNR2 "Signal to Noise Ration";
CM_ SG_ 105 FLR2RdrDetn040To044SNR3 "Signal to Noise Ration";
CM_ SG_ 105 FLR2RdrDetn040To044SNR4 "Signal to Noise Ration";
CM_ SG_ 108 FLR2RdrDetn045To049AziAng0 "Azimuth Angle";
CM_ SG_ 108 FLR2RdrDetn045To049AziAng1 "Azimuth Angle";
CM_ SG_ 108 FLR2RdrDetn045To049AziAng2 "Azimuth Angle";
CM_ SG_ 108 FLR2RdrDetn045To049AziAng3 "Azimuth Angle";
CM_ SG_ 108 FLR2RdrDetn045To049AziAng4 "Azimuth Angle";
CM_ SG_ 108 FLR2RdrDetn045To049DynPrpty0 "Moving/Stationary";
CM_ SG_ 108 FLR2RdrDetn045To049DynPrpty1 "Moving/Stationary";
CM_ SG_ 108 FLR2RdrDetn045To049DynPrpty2 "Moving/Stationary";
CM_ SG_ 108 FLR2RdrDetn045To049DynPrpty3 "Moving/Stationary";
CM_ SG_ 108 FLR2RdrDetn045To049DynPrpty4 "Moving/Stationary";
CM_ SG_ 108 FLR2RdrDetn045To049EleAng0 "Elevation angle";
CM_ SG_ 108 FLR2RdrDetn045To049EleAng1 "Elevation angle";
CM_ SG_ 108 FLR2RdrDetn045To049EleAng2 "Elevation angle";
CM_ SG_ 108 FLR2RdrDetn045To049EleAng3 "Elevation angle";
CM_ SG_ 108 FLR2RdrDetn045To049EleAng4 "Elevation angle";
CM_ SG_ 108 FLR2RdrDetn045To049Mode0 "What chirp mode the detection is from";
CM_ SG_ 108 FLR2RdrDetn045To049Mode1 "What chirp mode the detection is from";
CM_ SG_ 108 FLR2RdrDetn045To049Mode2 "What chirp mode the detection is from";
CM_ SG_ 108 FLR2RdrDetn045To049Mode3 "What chirp mode the detection is from";
CM_ SG_ 108 FLR2RdrDetn045To049Mode4 "What chirp mode the detection is from";
CM_ SG_ 108 FLR2RdrDetn045To049Quality0 "Quality";
CM_ SG_ 108 FLR2RdrDetn045To049Quality1 "Quality";
CM_ SG_ 108 FLR2RdrDetn045To049Quality2 "Quality";
CM_ SG_ 108 FLR2RdrDetn045To049Quality3 "Quality";
CM_ SG_ 108 FLR2RdrDetn045To049Quality4 "Quality";
CM_ SG_ 108 FLR2RdrDetn045To049Range0 "Range from sensor to object";
CM_ SG_ 108 FLR2RdrDetn045To049Range1 "Range from sensor to object";
CM_ SG_ 108 FLR2RdrDetn045To049Range2 "Range from sensor to object";
CM_ SG_ 108 FLR2RdrDetn045To049Range3 "Range from sensor to object";
CM_ SG_ 108 FLR2RdrDetn045To049Range4 "Range from sensor to object";
CM_ SG_ 108 FLR2RdrDetn045To049RCS0 "RCS";
CM_ SG_ 108 FLR2RdrDetn045To049RCS1 "RCS";
CM_ SG_ 108 FLR2RdrDetn045To049RCS2 "RCS";
CM_ SG_ 108 FLR2RdrDetn045To049RCS3 "RCS";
CM_ SG_ 108 FLR2RdrDetn045To049RCS4 "RCS";
CM_ SG_ 108 FLR2RdrDetn045To049RngRt0 "Speed towards/away from the sensor";
CM_ SG_ 108 FLR2RdrDetn045To049RngRt1 "Speed towards/away from the sensor";
CM_ SG_ 108 FLR2RdrDetn045To049RngRt2 "Speed towards/away from the sensor";
CM_ SG_ 108 FLR2RdrDetn045To049RngRt3 "Speed towards/away from the sensor";
CM_ SG_ 108 FLR2RdrDetn045To049RngRt4 "Speed towards/away from the sensor";
CM_ SG_ 108 FLR2RdrDetn045To049ScanID "Value to tie status, detection data and object data frames together";
CM_ SG_ 108 FLR2RdrDetn045To049SNR0 "Signal to Noise Ratio";
CM_ SG_ 108 FLR2RdrDetn045To049SNR1 "Signal to Noise Ration";
CM_ SG_ 108 FLR2RdrDetn045To049SNR2 "Signal to Noise Ration";
CM_ SG_ 108 FLR2RdrDetn045To049SNR3 "Signal to Noise Ration";
CM_ SG_ 108 FLR2RdrDetn045To049SNR4 "Signal to Noise Ration";
CM_ SG_ 112 FLR2RdrDetn050To054AziAng0 "Azimuth Angle";
CM_ SG_ 112 FLR2RdrDetn050To054AziAng1 "Azimuth Angle";
CM_ SG_ 112 FLR2RdrDetn050To054AziAng2 "Azimuth Angle";
CM_ SG_ 112 FLR2RdrDetn050To054AziAng3 "Azimuth Angle";
CM_ SG_ 112 FLR2RdrDetn050To054AziAng4 "Azimuth Angle";
CM_ SG_ 112 FLR2RdrDetn050To054DynPrpty0 "Moving/Stationary";
CM_ SG_ 112 FLR2RdrDetn050To054DynPrpty1 "Moving/Stationary";
CM_ SG_ 112 FLR2RdrDetn050To054DynPrpty2 "Moving/Stationary";
CM_ SG_ 112 FLR2RdrDetn050To054DynPrpty3 "Moving/Stationary";
CM_ SG_ 112 FLR2RdrDetn050To054DynPrpty4 "Moving/Stationary";
CM_ SG_ 112 FLR2RdrDetn050To054EleAng0 "Elevation angle";
CM_ SG_ 112 FLR2RdrDetn050To054EleAng1 "Elevation angle";
CM_ SG_ 112 FLR2RdrDetn050To054EleAng2 "Elevation angle";
CM_ SG_ 112 FLR2RdrDetn050To054EleAng3 "Elevation angle";
CM_ SG_ 112 FLR2RdrDetn050To054EleAng4 "Elevation angle";
CM_ SG_ 112 FLR2RdrDetn050To054Mode0 "What chirp mode the detection is from";
CM_ SG_ 112 FLR2RdrDetn050To054Mode1 "What chirp mode the detection is from";
CM_ SG_ 112 FLR2RdrDetn050To054Mode2 "What chirp mode the detection is from";
CM_ SG_ 112 FLR2RdrDetn050To054Mode3 "What chirp mode the detection is from";
CM_ SG_ 112 FLR2RdrDetn050To054Mode4 "What chirp mode the detection is from";
CM_ SG_ 112 FLR2RdrDetn050To054Quality0 "Quality";
CM_ SG_ 112 FLR2RdrDetn050To054Quality1 "Quality";
CM_ SG_ 112 FLR2RdrDetn050To054Quality2 "Quality";
CM_ SG_ 112 FLR2RdrDetn050To054Quality3 "Quality";
CM_ SG_ 112 FLR2RdrDetn050To054Quality4 "Quality";
CM_ SG_ 112 FLR2RdrDetn050To054Range0 "Range from sensor to object";
CM_ SG_ 112 FLR2RdrDetn050To054Range1 "Range from sensor to object";
CM_ SG_ 112 FLR2RdrDetn050To054Range2 "Range from sensor to object";
CM_ SG_ 112 FLR2RdrDetn050To054Range3 "Range from sensor to object";
CM_ SG_ 112 FLR2RdrDetn050To054Range4 "Range from sensor to object";
CM_ SG_ 112 FLR2RdrDetn050To054RCS0 "RCS";
CM_ SG_ 112 FLR2RdrDetn050To054RCS1 "RCS";
CM_ SG_ 112 FLR2RdrDetn050To054RCS2 "RCS";
CM_ SG_ 112 FLR2RdrDetn050To054RCS3 "RCS";
CM_ SG_ 112 FLR2RdrDetn050To054RCS4 "RCS";
CM_ SG_ 112 FLR2RdrDetn050To054RngRt0 "Speed towards/away from the sensor";
CM_ SG_ 112 FLR2RdrDetn050To054RngRt1 "Speed towards/away from the sensor";
CM_ SG_ 112 FLR2RdrDetn050To054RngRt2 "Speed towards/away from the sensor";
CM_ SG_ 112 FLR2RdrDetn050To054RngRt3 "Speed towards/away from the sensor";
CM_ SG_ 112 FLR2RdrDetn050To054RngRt4 "Speed towards/away from the sensor";
CM_ SG_ 112 FLR2RdrDetn050To054ScanID "Value to tie status, detection data and object data frames together";
CM_ SG_ 112 FLR2RdrDetn050To054SNR0 "Signal to Noise Ratio";
CM_ SG_ 112 FLR2RdrDetn050To054SNR1 "Signal to Noise Ration";
CM_ SG_ 112 FLR2RdrDetn050To054SNR2 "Signal to Noise Ration";
CM_ SG_ 112 FLR2RdrDetn050To054SNR3 "Signal to Noise Ration";
CM_ SG_ 112 FLR2RdrDetn050To054SNR4 "Signal to Noise Ration";
CM_ SG_ 115 FLR2RdrDetn055To059AziAng0 "Azimuth Angle";
CM_ SG_ 115 FLR2RdrDetn055To059AziAng1 "Azimuth Angle";
CM_ SG_ 115 FLR2RdrDetn055To059AziAng2 "Azimuth Angle";
CM_ SG_ 115 FLR2RdrDetn055To059AziAng3 "Azimuth Angle";
CM_ SG_ 115 FLR2RdrDetn055To059AziAng4 "Azimuth Angle";
CM_ SG_ 115 FLR2RdrDetn055To059DynPrpty0 "Moving/Stationary";
CM_ SG_ 115 FLR2RdrDetn055To059DynPrpty1 "Moving/Stationary";
CM_ SG_ 115 FLR2RdrDetn055To059DynPrpty2 "Moving/Stationary";
CM_ SG_ 115 FLR2RdrDetn055To059DynPrpty3 "Moving/Stationary";
CM_ SG_ 115 FLR2RdrDetn055To059DynPrpty4 "Moving/Stationary";
CM_ SG_ 115 FLR2RdrDetn055To059EleAng0 "Elevation angle";
CM_ SG_ 115 FLR2RdrDetn055To059EleAng1 "Elevation angle";
CM_ SG_ 115 FLR2RdrDetn055To059EleAng2 "Elevation angle";
CM_ SG_ 115 FLR2RdrDetn055To059EleAng3 "Elevation angle";
CM_ SG_ 115 FLR2RdrDetn055To059EleAng4 "Elevation angle";
CM_ SG_ 115 FLR2RdrDetn055To059Mode0 "What chirp mode the detection is from";
CM_ SG_ 115 FLR2RdrDetn055To059Mode1 "What chirp mode the detection is from";
CM_ SG_ 115 FLR2RdrDetn055To059Mode2 "What chirp mode the detection is from";
CM_ SG_ 115 FLR2RdrDetn055To059Mode3 "What chirp mode the detection is from";
CM_ SG_ 115 FLR2RdrDetn055To059Mode4 "What chirp mode the detection is from";
CM_ SG_ 115 FLR2RdrDetn055To059Quality0 "Quality";
CM_ SG_ 115 FLR2RdrDetn055To059Quality1 "Quality";
CM_ SG_ 115 FLR2RdrDetn055To059Quality2 "Quality";
CM_ SG_ 115 FLR2RdrDetn055To059Quality3 "Quality";
CM_ SG_ 115 FLR2RdrDetn055To059Quality4 "Quality";
CM_ SG_ 115 FLR2RdrDetn055To059Range0 "Range from sensor to object";
CM_ SG_ 115 FLR2RdrDetn055To059Range1 "Range from sensor to object";
CM_ SG_ 115 FLR2RdrDetn055To059Range2 "Range from sensor to object";
CM_ SG_ 115 FLR2RdrDetn055To059Range3 "Range from sensor to object";
CM_ SG_ 115 FLR2RdrDetn055To059Range4 "Range from sensor to object";
CM_ SG_ 115 FLR2RdrDetn055To059RCS0 "RCS";
CM_ SG_ 115 FLR2RdrDetn055To059RCS1 "RCS";
CM_ SG_ 115 FLR2RdrDetn055To059RCS2 "RCS";
CM_ SG_ 115 FLR2RdrDetn055To059RCS3 "RCS";
CM_ SG_ 115 FLR2RdrDetn055To059RCS4 "RCS";
CM_ SG_ 115 FLR2RdrDetn055To059RngRt0 "Speed towards/away from the sensor";
CM_ SG_ 115 FLR2RdrDetn055To059RngRt1 "Speed towards/away from the sensor";
CM_ SG_ 115 FLR2RdrDetn055To059RngRt2 "Speed towards/away from the sensor";
CM_ SG_ 115 FLR2RdrDetn055To059RngRt3 "Speed towards/away from the sensor";
CM_ SG_ 115 FLR2RdrDetn055To059RngRt4 "Speed towards/away from the sensor";
CM_ SG_ 115 FLR2RdrDetn055To059ScanID "Value to tie status, detection data and object data frames together";
CM_ SG_ 115 FLR2RdrDetn055To059SNR0 "Signal to Noise Ratio";
CM_ SG_ 115 FLR2RdrDetn055To059SNR1 "Signal to Noise Ration";
CM_ SG_ 115 FLR2RdrDetn055To059SNR2 "Signal to Noise Ration";
CM_ SG_ 115 FLR2RdrDetn055To059SNR3 "Signal to Noise Ration";
CM_ SG_ 115 FLR2RdrDetn055To059SNR4 "Signal to Noise Ration";

// Attribute definitions
BA_DEF_  "BaudRateCANFD" FLOAT 1000 10000000; // [bps]
BA_DEF_  "Baudrate" INT 1000 1000000; // [bps]
BA_DEF_  "BusType" STRING;
BA_DEF_  "DBName" STRING;
BA_DEF_  "ProtocolType" STRING;
BA_DEF_ BO_ "CANFD_BRS" ENUM "0","1";
BA_DEF_ BO_ "GenMsgCycleTime" INT 0 65536; // [ms]
BA_DEF_ BO_ "GenMsgDelayTime" INT 0 65536; // [ms]
BA_DEF_ BO_ "GenMsgSendType" ENUM "cyclic", "spontaneous", "not-used", "not-used", "not-used", "cyclicAndSpontaneous", "not-used", "cyclicIfActive", "NoMsgSendType"; // [us]
BA_DEF_ BO_ "GenMsgStartDelayTime" INT 0 65536; // [ms]
BA_DEF_ BO_ "VFrameFormat" ENUM "StandardCAN","ExtendedCAN","reserved","J1939PG","reserved","reserved","reserved","reserved","reserved","reserved","reserved","reserved","reserved","reserved","StandardCAN_FD","ExtendedCAN_FD";
BA_DEF_ SG_ "GenSigSendType" ENUM "Cyclic","OnWrite","OnWriteWithRepetition","OnChange","OnChangeWithRepetition","IfActive","IfActiveWithRepetition","NoSigSendType";
BA_DEF_ SG_ "GenSigStartValue" HEX 0 80000000;
BA_DEF_ BO_ "GenMsgILSupport" ENUM "No","Yes";
BA_DEF_ BO_ "NmAsrMessage" ENUM "No","Yes";
BA_DEF_  "NmAsrBaseAddress" HEX 0 536870911;
BA_DEF_  "NmAsrMessageCount" INT 0 255;
BA_DEF_ BU_ "NodeLayerModules" STRING;
BA_DEF_ BU_ "ILused" ENUM "No","Yes";
BA_DEF_ SG_ "GenSigFuncType" ENUM "NoFunction","n/a","n/a","n/a","n/a","n/a","n/a","n/a","n/a","n/a","n/a","n/a","n/a","n/a","n/a","CHK","CNTR","n/a","n/a","n/a","CNTR_AR_01","CRC_AR_01_BOTH","CRC_AR_01_ALT","CRC_AR_01_LOW","CRC_AR_01_NIBBLE","CNTR_AR_04","CRC_AR_04A","CNTR_AR_05","CRC_AR_05";
BA_DEF_ SG_ "GenSigDataID" STRING;

BA_DEF_DEF_ "BusType" "";
BA_DEF_DEF_ "DBName" "";
BA_DEF_DEF_ "ProtocolType" "";
BA_DEF_DEF_ "CANFD_BRS" "1";
BA_DEF_DEF_ "GenSigStartValue" 0;
BA_DEF_DEF_ "VFrameFormat" "J1939PG";
BA_DEF_DEF_ "GenSigSendType" "NoSigSendType";
BA_DEF_DEF_ "GenMsgCycleTime" 0;
BA_DEF_DEF_ "GenMsgDelayTime" 0;
BA_DEF_DEF_ "GenMsgStartDelayTime" 0;
BA_DEF_DEF_ "GenMsgSendType" "NoMsgSendType";
BA_DEF_DEF_ "GenMsgILSupport" "Yes";
BA_DEF_DEF_ "NmAsrMessage" "No";
BA_DEF_DEF_ "NmAsrBaseAddress" 1280;
BA_DEF_DEF_ "NmAsrMessageCount" 64;
BA_DEF_DEF_ "NodeLayerModules" "CANoeILNLSPA.dll";
BA_DEF_DEF_ "ILused" "Yes";
BA_DEF_DEF_ "GenSigFuncType" "NoFunction";
BA_DEF_DEF_ "GenSigDataID" "";

BA_ "BaudRateCANFD" 2000000;
BA_ "Baudrate" 500000;
BA_ "BusType" "CAN FD";
BA_ "DBName" "FLR1CAN";
BA_ "ProtocolType" "CAN";
// ECU: FLR
BA_ "ILused" BU_ FLR 0;
// ECU: FLRdpHPA
BA_ "ILused" BU_ FLRdpHPA 0;
// ECU: FLRdpHPB
BA_ "ILused" BU_ FLRdpHPB 0;
// Frame: Flr1canTimeSyncFr01
BA_ "GenMsgDelayTime" BO_ 1794 50.000;
BA_ "GenMsgSendType" BO_ 1794 1;
BA_ "VFrameFormat" BO_ 1794 0;
// Frame: FlrFlr1canFr01
BA_ "GenMsgDelayTime" BO_ 80 40.000;
BA_ "GenMsgSendType" BO_ 80 1;
BA_ "VFrameFormat" BO_ 80 14;
// Frame: FlrFlr1canFr02
BA_ "GenMsgDelayTime" BO_ 83 40.000;
BA_ "GenMsgSendType" BO_ 83 1;
BA_ "VFrameFormat" BO_ 83 14;
// Frame: FlrFlr1canFr03
BA_ "GenMsgDelayTime" BO_ 86 40.000;
BA_ "GenMsgSendType" BO_ 86 1;
BA_ "VFrameFormat" BO_ 86 14;
// Frame: FlrFlr1canFr04
BA_ "GenMsgDelayTime" BO_ 89 40.000;
BA_ "GenMsgSendType" BO_ 89 1;
BA_ "VFrameFormat" BO_ 89 14;
// Frame: FlrFlr1canFr05
BA_ "GenMsgDelayTime" BO_ 92 40.000;
BA_ "GenMsgSendType" BO_ 92 1;
BA_ "VFrameFormat" BO_ 92 14;
// Frame: FlrFlr1canFr06
BA_ "GenMsgDelayTime" BO_ 96 40.000;
BA_ "GenMsgSendType" BO_ 96 1;
BA_ "VFrameFormat" BO_ 96 14;
// Frame: FlrFlr1canFr07
BA_ "GenMsgDelayTime" BO_ 99 40.000;
BA_ "GenMsgSendType" BO_ 99 1;
BA_ "VFrameFormat" BO_ 99 14;
// Frame: FlrFlr1canFr08
BA_ "GenMsgDelayTime" BO_ 102 40.000;
BA_ "GenMsgSendType" BO_ 102 1;
BA_ "VFrameFormat" BO_ 102 14;
// Frame: FlrFlr1canFr09
BA_ "GenMsgDelayTime" BO_ 105 40.000;
BA_ "GenMsgSendType" BO_ 105 1;
BA_ "VFrameFormat" BO_ 105 14;
// Frame: FlrFlr1canFr10
BA_ "GenMsgDelayTime" BO_ 108 40.000;
BA_ "GenMsgSendType" BO_ 108 1;
BA_ "VFrameFormat" BO_ 108 14;
// Frame: FlrFlr1canFr11
BA_ "GenMsgDelayTime" BO_ 112 40.000;
BA_ "GenMsgSendType" BO_ 112 1;
BA_ "VFrameFormat" BO_ 112 14;
// Frame: FlrFlr1canFr12
BA_ "GenMsgDelayTime" BO_ 115 40.000;
BA_ "GenMsgSendType" BO_ 115 1;
BA_ "VFrameFormat" BO_ 115 14;
// Frame: FlrdpFlr1canFr02
BA_ "GenMsgCycleTime" BO_ 512 60.000;
BA_ "GenMsgSendType" BO_ 512 0;
BA_ "VFrameFormat" BO_ 512 14;
// Frame: FlrdpFlr1canFr03
BA_ "GenMsgCycleTime" BO_ 528 60.000;
BA_ "GenMsgSendType" BO_ 528 0;
BA_ "VFrameFormat" BO_ 528 14;
// Frame: FlrdpFlr1canFr04
BA_ "GenMsgCycleTime" BO_ 544 60.000;
BA_ "GenMsgSendType" BO_ 544 0;
BA_ "VFrameFormat" BO_ 544 14;
// Frame: FlrdpFlr1canFr05
BA_ "GenMsgCycleTime" BO_ 560 60.000;
BA_ "GenMsgSendType" BO_ 560 0;
BA_ "VFrameFormat" BO_ 560 14;
// Frame: FlrdpFlr1canFr07
BA_ "GenMsgCycleTime" BO_ 576 60.000;
BA_ "GenMsgSendType" BO_ 576 0;
BA_ "VFrameFormat" BO_ 576 14;
// Frame: FlrdpToAllUdsDiagRequestFrame
BA_ "GenMsgDelayTime" BO_ 2047 5.000;
BA_ "GenMsgSendType" BO_ 2047 1;
BA_ "VFrameFormat" BO_ 2047 14;
// Frame: FlrdpToFlrUdsDiagRequestFrame
BA_ "GenMsgDelayTime" BO_ 1873 5.000;
BA_ "GenMsgSendType" BO_ 1873 1;
BA_ "VFrameFormat" BO_ 1873 14;
BA_ "GenSigDataID" SG_ 528 CarConfigCRC "0xA35";
BA_ "GenSigFuncType" SG_ 528 CarConfigCRC 28;
BA_ "GenSigSendType" SG_ 528 CarConfigCRC 0;
BA_ "GenSigFuncType" SG_ 528 CarConfigCounter 27;
BA_ "GenSigSendType" SG_ 528 CarConfigCounter 0;
BA_ "GenSigSendType" SG_ 528 CarConfigPropulsionType 0;
BA_ "GenSigSendType" SG_ 528 CarConfigVehicleTyp 0;
BA_ "GenSigSendType" SG_ 80 FLR2RdrDetn000To004AziAng0 1;
BA_ "GenSigSendType" SG_ 80 FLR2RdrDetn000To004AziAng1 1;
BA_ "GenSigSendType" SG_ 80 FLR2RdrDetn000To004AziAng2 1;
BA_ "GenSigSendType" SG_ 80 FLR2RdrDetn000To004AziAng3 1;
BA_ "GenSigSendType" SG_ 80 FLR2RdrDetn000To004AziAng4 1;
BA_ "GenSigDataID" SG_ 80 FLR2RdrDetn000To004CRC "0xAB8";
BA_ "GenSigFuncType" SG_ 80 FLR2RdrDetn000To004CRC 28;
BA_ "GenSigSendType" SG_ 80 FLR2RdrDetn000To004CRC 1;
BA_ "GenSigFuncType" SG_ 80 FLR2RdrDetn000To004Counter 27;
BA_ "GenSigSendType" SG_ 80 FLR2RdrDetn000To004Counter 1;
BA_ "GenSigSendType" SG_ 80 FLR2RdrDetn000To004DynPrpty0 1;
BA_ "GenSigSendType" SG_ 80 FLR2RdrDetn000To004DynPrpty1 1;
BA_ "GenSigSendType" SG_ 80 FLR2RdrDetn000To004DynPrpty2 1;
BA_ "GenSigSendType" SG_ 80 FLR2RdrDetn000To004DynPrpty3 1;
BA_ "GenSigSendType" SG_ 80 FLR2RdrDetn000To004DynPrpty4 1;
BA_ "GenSigSendType" SG_ 80 FLR2RdrDetn000To004EleAng0 1;
BA_ "GenSigSendType" SG_ 80 FLR2RdrDetn000To004EleAng1 1;
BA_ "GenSigSendType" SG_ 80 FLR2RdrDetn000To004EleAng2 1;
BA_ "GenSigSendType" SG_ 80 FLR2RdrDetn000To004EleAng3 1;
BA_ "GenSigSendType" SG_ 80 FLR2RdrDetn000To004EleAng4 1;
BA_ "GenSigSendType" SG_ 80 FLR2RdrDetn000To004Mode0 1;
BA_ "GenSigSendType" SG_ 80 FLR2RdrDetn000To004Mode1 1;
BA_ "GenSigSendType" SG_ 80 FLR2RdrDetn000To004Mode2 1;
BA_ "GenSigSendType" SG_ 80 FLR2RdrDetn000To004Mode3 1;
BA_ "GenSigSendType" SG_ 80 FLR2RdrDetn000To004Mode4 1;
BA_ "GenSigSendType" SG_ 80 FLR2RdrDetn000To004Quality0 1;
BA_ "GenSigSendType" SG_ 80 FLR2RdrDetn000To004Quality1 1;
BA_ "GenSigSendType" SG_ 80 FLR2RdrDetn000To004Quality2 1;
BA_ "GenSigSendType" SG_ 80 FLR2RdrDetn000To004Quality3 1;
BA_ "GenSigSendType" SG_ 80 FLR2RdrDetn000To004Quality4 1;
BA_ "GenSigSendType" SG_ 80 FLR2RdrDetn000To004RCS0 1;
BA_ "GenSigStartValue" SG_ 80 FLR2RdrDetn000To004RCS0 500;
BA_ "GenSigSendType" SG_ 80 FLR2RdrDetn000To004RCS1 1;
BA_ "GenSigStartValue" SG_ 80 FLR2RdrDetn000To004RCS1 500;
BA_ "GenSigSendType" SG_ 80 FLR2RdrDetn000To004RCS2 1;
BA_ "GenSigStartValue" SG_ 80 FLR2RdrDetn000To004RCS2 500;
BA_ "GenSigSendType" SG_ 80 FLR2RdrDetn000To004RCS3 1;
BA_ "GenSigStartValue" SG_ 80 FLR2RdrDetn000To004RCS3 500;
BA_ "GenSigSendType" SG_ 80 FLR2RdrDetn000To004RCS4 1;
BA_ "GenSigStartValue" SG_ 80 FLR2RdrDetn000To004RCS4 500;
BA_ "GenSigSendType" SG_ 80 FLR2RdrDetn000To004Range0 1;
BA_ "GenSigSendType" SG_ 80 FLR2RdrDetn000To004Range1 1;
BA_ "GenSigSendType" SG_ 80 FLR2RdrDetn000To004Range2 1;
BA_ "GenSigSendType" SG_ 80 FLR2RdrDetn000To004Range3 1;
BA_ "GenSigSendType" SG_ 80 FLR2RdrDetn000To004Range4 1;
BA_ "GenSigSendType" SG_ 80 FLR2RdrDetn000To004RngRt0 1;
BA_ "GenSigStartValue" SG_ 80 FLR2RdrDetn000To004RngRt0 1111;
BA_ "GenSigSendType" SG_ 80 FLR2RdrDetn000To004RngRt1 1;
BA_ "GenSigStartValue" SG_ 80 FLR2RdrDetn000To004RngRt1 1111;
BA_ "GenSigSendType" SG_ 80 FLR2RdrDetn000To004RngRt2 1;
BA_ "GenSigStartValue" SG_ 80 FLR2RdrDetn000To004RngRt2 1111;
BA_ "GenSigSendType" SG_ 80 FLR2RdrDetn000To004RngRt3 1;
BA_ "GenSigStartValue" SG_ 80 FLR2RdrDetn000To004RngRt3 1111;
BA_ "GenSigSendType" SG_ 80 FLR2RdrDetn000To004RngRt4 1;
BA_ "GenSigStartValue" SG_ 80 FLR2RdrDetn000To004RngRt4 1111;
BA_ "GenSigSendType" SG_ 80 FLR2RdrDetn000To004SNR0 1;
BA_ "GenSigSendType" SG_ 80 FLR2RdrDetn000To004SNR1 1;
BA_ "GenSigSendType" SG_ 80 FLR2RdrDetn000To004SNR2 1;
BA_ "GenSigSendType" SG_ 80 FLR2RdrDetn000To004SNR3 1;
BA_ "GenSigSendType" SG_ 80 FLR2RdrDetn000To004SNR4 1;
BA_ "GenSigSendType" SG_ 80 FLR2RdrDetn000To004ScanID 1;
BA_ "GenSigSendType" SG_ 83 FLR2RdrDetn005To009AziAng0 1;
BA_ "GenSigSendType" SG_ 83 FLR2RdrDetn005To009AziAng1 1;
BA_ "GenSigSendType" SG_ 83 FLR2RdrDetn005To009AziAng2 1;
BA_ "GenSigSendType" SG_ 83 FLR2RdrDetn005To009AziAng3 1;
BA_ "GenSigSendType" SG_ 83 FLR2RdrDetn005To009AziAng4 1;
BA_ "GenSigDataID" SG_ 83 FLR2RdrDetn005To009CRC "0xABA";
BA_ "GenSigFuncType" SG_ 83 FLR2RdrDetn005To009CRC 28;
BA_ "GenSigSendType" SG_ 83 FLR2RdrDetn005To009CRC 1;
BA_ "GenSigFuncType" SG_ 83 FLR2RdrDetn005To009Counter 27;
BA_ "GenSigSendType" SG_ 83 FLR2RdrDetn005To009Counter 1;
BA_ "GenSigSendType" SG_ 83 FLR2RdrDetn005To009DynPrpty0 1;
BA_ "GenSigSendType" SG_ 83 FLR2RdrDetn005To009DynPrpty1 1;
BA_ "GenSigSendType" SG_ 83 FLR2RdrDetn005To009DynPrpty2 1;
BA_ "GenSigSendType" SG_ 83 FLR2RdrDetn005To009DynPrpty3 1;
BA_ "GenSigSendType" SG_ 83 FLR2RdrDetn005To009DynPrpty4 1;
BA_ "GenSigSendType" SG_ 83 FLR2RdrDetn005To009EleAng0 1;
BA_ "GenSigSendType" SG_ 83 FLR2RdrDetn005To009EleAng1 1;
BA_ "GenSigSendType" SG_ 83 FLR2RdrDetn005To009EleAng2 1;
BA_ "GenSigSendType" SG_ 83 FLR2RdrDetn005To009EleAng3 1;
BA_ "GenSigSendType" SG_ 83 FLR2RdrDetn005To009EleAng4 1;
BA_ "GenSigSendType" SG_ 83 FLR2RdrDetn005To009Mode0 1;
BA_ "GenSigSendType" SG_ 83 FLR2RdrDetn005To009Mode1 1;
BA_ "GenSigSendType" SG_ 83 FLR2RdrDetn005To009Mode2 1;
BA_ "GenSigSendType" SG_ 83 FLR2RdrDetn005To009Mode3 1;
BA_ "GenSigSendType" SG_ 83 FLR2RdrDetn005To009Mode4 1;
BA_ "GenSigSendType" SG_ 83 FLR2RdrDetn005To009Quality0 1;
BA_ "GenSigSendType" SG_ 83 FLR2RdrDetn005To009Quality1 1;
BA_ "GenSigSendType" SG_ 83 FLR2RdrDetn005To009Quality2 1;
BA_ "GenSigSendType" SG_ 83 FLR2RdrDetn005To009Quality3 1;
BA_ "GenSigSendType" SG_ 83 FLR2RdrDetn005To009Quality4 1;
BA_ "GenSigSendType" SG_ 83 FLR2RdrDetn005To009RCS0 1;
BA_ "GenSigStartValue" SG_ 83 FLR2RdrDetn005To009RCS0 500;
BA_ "GenSigSendType" SG_ 83 FLR2RdrDetn005To009RCS1 1;
BA_ "GenSigStartValue" SG_ 83 FLR2RdrDetn005To009RCS1 500;
BA_ "GenSigSendType" SG_ 83 FLR2RdrDetn005To009RCS2 1;
BA_ "GenSigStartValue" SG_ 83 FLR2RdrDetn005To009RCS2 500;
BA_ "GenSigSendType" SG_ 83 FLR2RdrDetn005To009RCS3 1;
BA_ "GenSigStartValue" SG_ 83 FLR2RdrDetn005To009RCS3 500;
BA_ "GenSigSendType" SG_ 83 FLR2RdrDetn005To009RCS4 1;
BA_ "GenSigStartValue" SG_ 83 FLR2RdrDetn005To009RCS4 500;
BA_ "GenSigSendType" SG_ 83 FLR2RdrDetn005To009Range0 1;
BA_ "GenSigSendType" SG_ 83 FLR2RdrDetn005To009Range1 1;
BA_ "GenSigSendType" SG_ 83 FLR2RdrDetn005To009Range2 1;
BA_ "GenSigSendType" SG_ 83 FLR2RdrDetn005To009Range3 1;
BA_ "GenSigSendType" SG_ 83 FLR2RdrDetn005To009Range4 1;
BA_ "GenSigSendType" SG_ 83 FLR2RdrDetn005To009RngRt0 1;
BA_ "GenSigStartValue" SG_ 83 FLR2RdrDetn005To009RngRt0 1111;
BA_ "GenSigSendType" SG_ 83 FLR2RdrDetn005To009RngRt1 1;
BA_ "GenSigStartValue" SG_ 83 FLR2RdrDetn005To009RngRt1 1111;
BA_ "GenSigSendType" SG_ 83 FLR2RdrDetn005To009RngRt2 1;
BA_ "GenSigStartValue" SG_ 83 FLR2RdrDetn005To009RngRt2 1111;
BA_ "GenSigSendType" SG_ 83 FLR2RdrDetn005To009RngRt3 1;
BA_ "GenSigStartValue" SG_ 83 FLR2RdrDetn005To009RngRt3 1111;
BA_ "GenSigSendType" SG_ 83 FLR2RdrDetn005To009RngRt4 1;
BA_ "GenSigStartValue" SG_ 83 FLR2RdrDetn005To009RngRt4 1111;
BA_ "GenSigSendType" SG_ 83 FLR2RdrDetn005To009SNR0 1;
BA_ "GenSigSendType" SG_ 83 FLR2RdrDetn005To009SNR1 1;
BA_ "GenSigSendType" SG_ 83 FLR2RdrDetn005To009SNR2 1;
BA_ "GenSigSendType" SG_ 83 FLR2RdrDetn005To009SNR3 1;
BA_ "GenSigSendType" SG_ 83 FLR2RdrDetn005To009SNR4 1;
BA_ "GenSigSendType" SG_ 83 FLR2RdrDetn005To009ScanID 1;
BA_ "GenSigSendType" SG_ 86 FLR2RdrDetn010To014AziAng0 1;
BA_ "GenSigSendType" SG_ 86 FLR2RdrDetn010To014AziAng1 1;
BA_ "GenSigSendType" SG_ 86 FLR2RdrDetn010To014AziAng2 1;
BA_ "GenSigSendType" SG_ 86 FLR2RdrDetn010To014AziAng3 1;
BA_ "GenSigSendType" SG_ 86 FLR2RdrDetn010To014AziAng4 1;
BA_ "GenSigDataID" SG_ 86 FLR2RdrDetn010To014CRC "0xABB";
BA_ "GenSigFuncType" SG_ 86 FLR2RdrDetn010To014CRC 28;
BA_ "GenSigSendType" SG_ 86 FLR2RdrDetn010To014CRC 1;
BA_ "GenSigFuncType" SG_ 86 FLR2RdrDetn010To014Counter 27;
BA_ "GenSigSendType" SG_ 86 FLR2RdrDetn010To014Counter 1;
BA_ "GenSigSendType" SG_ 86 FLR2RdrDetn010To014DynPrpty0 1;
BA_ "GenSigSendType" SG_ 86 FLR2RdrDetn010To014DynPrpty1 1;
BA_ "GenSigSendType" SG_ 86 FLR2RdrDetn010To014DynPrpty2 1;
BA_ "GenSigSendType" SG_ 86 FLR2RdrDetn010To014DynPrpty3 1;
BA_ "GenSigSendType" SG_ 86 FLR2RdrDetn010To014DynPrpty4 1;
BA_ "GenSigSendType" SG_ 86 FLR2RdrDetn010To014EleAng0 1;
BA_ "GenSigSendType" SG_ 86 FLR2RdrDetn010To014EleAng1 1;
BA_ "GenSigSendType" SG_ 86 FLR2RdrDetn010To014EleAng2 1;
BA_ "GenSigSendType" SG_ 86 FLR2RdrDetn010To014EleAng3 1;
BA_ "GenSigSendType" SG_ 86 FLR2RdrDetn010To014EleAng4 1;
BA_ "GenSigSendType" SG_ 86 FLR2RdrDetn010To014Mode0 1;
BA_ "GenSigSendType" SG_ 86 FLR2RdrDetn010To014Mode1 1;
BA_ "GenSigSendType" SG_ 86 FLR2RdrDetn010To014Mode2 1;
BA_ "GenSigSendType" SG_ 86 FLR2RdrDetn010To014Mode3 1;
BA_ "GenSigSendType" SG_ 86 FLR2RdrDetn010To014Mode4 1;
BA_ "GenSigSendType" SG_ 86 FLR2RdrDetn010To014Quality0 1;
BA_ "GenSigSendType" SG_ 86 FLR2RdrDetn010To014Quality1 1;
BA_ "GenSigSendType" SG_ 86 FLR2RdrDetn010To014Quality2 1;
BA_ "GenSigSendType" SG_ 86 FLR2RdrDetn010To014Quality3 1;
BA_ "GenSigSendType" SG_ 86 FLR2RdrDetn010To014Quality4 1;
BA_ "GenSigSendType" SG_ 86 FLR2RdrDetn010To014RCS0 1;
BA_ "GenSigStartValue" SG_ 86 FLR2RdrDetn010To014RCS0 500;
BA_ "GenSigSendType" SG_ 86 FLR2RdrDetn010To014RCS1 1;
BA_ "GenSigStartValue" SG_ 86 FLR2RdrDetn010To014RCS1 500;
BA_ "GenSigSendType" SG_ 86 FLR2RdrDetn010To014RCS2 1;
BA_ "GenSigStartValue" SG_ 86 FLR2RdrDetn010To014RCS2 500;
BA_ "GenSigSendType" SG_ 86 FLR2RdrDetn010To014RCS3 1;
BA_ "GenSigStartValue" SG_ 86 FLR2RdrDetn010To014RCS3 500;
BA_ "GenSigSendType" SG_ 86 FLR2RdrDetn010To014RCS4 1;
BA_ "GenSigStartValue" SG_ 86 FLR2RdrDetn010To014RCS4 500;
BA_ "GenSigSendType" SG_ 86 FLR2RdrDetn010To014Range0 1;
BA_ "GenSigSendType" SG_ 86 FLR2RdrDetn010To014Range1 1;
BA_ "GenSigSendType" SG_ 86 FLR2RdrDetn010To014Range2 1;
BA_ "GenSigSendType" SG_ 86 FLR2RdrDetn010To014Range3 1;
BA_ "GenSigSendType" SG_ 86 FLR2RdrDetn010To014Range4 1;
BA_ "GenSigSendType" SG_ 86 FLR2RdrDetn010To014RngRt0 1;
BA_ "GenSigStartValue" SG_ 86 FLR2RdrDetn010To014RngRt0 1111;
BA_ "GenSigSendType" SG_ 86 FLR2RdrDetn010To014RngRt1 1;
BA_ "GenSigStartValue" SG_ 86 FLR2RdrDetn010To014RngRt1 1111;
BA_ "GenSigSendType" SG_ 86 FLR2RdrDetn010To014RngRt2 1;
BA_ "GenSigStartValue" SG_ 86 FLR2RdrDetn010To014RngRt2 1111;
BA_ "GenSigSendType" SG_ 86 FLR2RdrDetn010To014RngRt3 1;
BA_ "GenSigStartValue" SG_ 86 FLR2RdrDetn010To014RngRt3 1111;
BA_ "GenSigSendType" SG_ 86 FLR2RdrDetn010To014RngRt4 1;
BA_ "GenSigStartValue" SG_ 86 FLR2RdrDetn010To014RngRt4 1111;
BA_ "GenSigSendType" SG_ 86 FLR2RdrDetn010To014SNR0 1;
BA_ "GenSigSendType" SG_ 86 FLR2RdrDetn010To014SNR1 1;
BA_ "GenSigSendType" SG_ 86 FLR2RdrDetn010To014SNR2 1;
BA_ "GenSigSendType" SG_ 86 FLR2RdrDetn010To014SNR3 1;
BA_ "GenSigSendType" SG_ 86 FLR2RdrDetn010To014SNR4 1;
BA_ "GenSigSendType" SG_ 86 FLR2RdrDetn010To014ScanID 1;
BA_ "GenSigSendType" SG_ 89 FLR2RdrDetn015To019AziAng0 1;
BA_ "GenSigSendType" SG_ 89 FLR2RdrDetn015To019AziAng1 1;
BA_ "GenSigSendType" SG_ 89 FLR2RdrDetn015To019AziAng2 1;
BA_ "GenSigSendType" SG_ 89 FLR2RdrDetn015To019AziAng3 1;
BA_ "GenSigSendType" SG_ 89 FLR2RdrDetn015To019AziAng4 1;
BA_ "GenSigDataID" SG_ 89 FLR2RdrDetn015To019CRC "0xABC";
BA_ "GenSigFuncType" SG_ 89 FLR2RdrDetn015To019CRC 28;
BA_ "GenSigSendType" SG_ 89 FLR2RdrDetn015To019CRC 1;
BA_ "GenSigFuncType" SG_ 89 FLR2RdrDetn015To019Counter 27;
BA_ "GenSigSendType" SG_ 89 FLR2RdrDetn015To019Counter 1;
BA_ "GenSigSendType" SG_ 89 FLR2RdrDetn015To019DynPrpty0 1;
BA_ "GenSigSendType" SG_ 89 FLR2RdrDetn015To019DynPrpty1 1;
BA_ "GenSigSendType" SG_ 89 FLR2RdrDetn015To019DynPrpty2 1;
BA_ "GenSigSendType" SG_ 89 FLR2RdrDetn015To019DynPrpty3 1;
BA_ "GenSigSendType" SG_ 89 FLR2RdrDetn015To019DynPrpty4 1;
BA_ "GenSigSendType" SG_ 89 FLR2RdrDetn015To019EleAng0 1;
BA_ "GenSigSendType" SG_ 89 FLR2RdrDetn015To019EleAng1 1;
BA_ "GenSigSendType" SG_ 89 FLR2RdrDetn015To019EleAng2 1;
BA_ "GenSigSendType" SG_ 89 FLR2RdrDetn015To019EleAng3 1;
BA_ "GenSigSendType" SG_ 89 FLR2RdrDetn015To019EleAng4 1;
BA_ "GenSigSendType" SG_ 89 FLR2RdrDetn015To019Mode0 1;
BA_ "GenSigSendType" SG_ 89 FLR2RdrDetn015To019Mode1 1;
BA_ "GenSigSendType" SG_ 89 FLR2RdrDetn015To019Mode2 1;
BA_ "GenSigSendType" SG_ 89 FLR2RdrDetn015To019Mode3 1;
BA_ "GenSigSendType" SG_ 89 FLR2RdrDetn015To019Mode4 1;
BA_ "GenSigSendType" SG_ 89 FLR2RdrDetn015To019Quality0 1;
BA_ "GenSigSendType" SG_ 89 FLR2RdrDetn015To019Quality1 1;
BA_ "GenSigSendType" SG_ 89 FLR2RdrDetn015To019Quality2 1;
BA_ "GenSigSendType" SG_ 89 FLR2RdrDetn015To019Quality3 1;
BA_ "GenSigSendType" SG_ 89 FLR2RdrDetn015To019Quality4 1;
BA_ "GenSigSendType" SG_ 89 FLR2RdrDetn015To019RCS0 1;
BA_ "GenSigStartValue" SG_ 89 FLR2RdrDetn015To019RCS0 500;
BA_ "GenSigSendType" SG_ 89 FLR2RdrDetn015To019RCS1 1;
BA_ "GenSigStartValue" SG_ 89 FLR2RdrDetn015To019RCS1 500;
BA_ "GenSigSendType" SG_ 89 FLR2RdrDetn015To019RCS2 1;
BA_ "GenSigStartValue" SG_ 89 FLR2RdrDetn015To019RCS2 500;
BA_ "GenSigSendType" SG_ 89 FLR2RdrDetn015To019RCS3 1;
BA_ "GenSigStartValue" SG_ 89 FLR2RdrDetn015To019RCS3 500;
BA_ "GenSigSendType" SG_ 89 FLR2RdrDetn015To019RCS4 1;
BA_ "GenSigStartValue" SG_ 89 FLR2RdrDetn015To019RCS4 500;
BA_ "GenSigSendType" SG_ 89 FLR2RdrDetn015To019Range0 1;
BA_ "GenSigSendType" SG_ 89 FLR2RdrDetn015To019Range1 1;
BA_ "GenSigSendType" SG_ 89 FLR2RdrDetn015To019Range2 1;
BA_ "GenSigSendType" SG_ 89 FLR2RdrDetn015To019Range3 1;
BA_ "GenSigSendType" SG_ 89 FLR2RdrDetn015To019Range4 1;
BA_ "GenSigSendType" SG_ 89 FLR2RdrDetn015To019RngRt0 1;
BA_ "GenSigStartValue" SG_ 89 FLR2RdrDetn015To019RngRt0 1111;
BA_ "GenSigSendType" SG_ 89 FLR2RdrDetn015To019RngRt1 1;
BA_ "GenSigStartValue" SG_ 89 FLR2RdrDetn015To019RngRt1 1111;
BA_ "GenSigSendType" SG_ 89 FLR2RdrDetn015To019RngRt2 1;
BA_ "GenSigStartValue" SG_ 89 FLR2RdrDetn015To019RngRt2 1111;
BA_ "GenSigSendType" SG_ 89 FLR2RdrDetn015To019RngRt3 1;
BA_ "GenSigStartValue" SG_ 89 FLR2RdrDetn015To019RngRt3 1111;
BA_ "GenSigSendType" SG_ 89 FLR2RdrDetn015To019RngRt4 1;
BA_ "GenSigStartValue" SG_ 89 FLR2RdrDetn015To019RngRt4 1111;
BA_ "GenSigSendType" SG_ 89 FLR2RdrDetn015To019SNR0 1;
BA_ "GenSigSendType" SG_ 89 FLR2RdrDetn015To019SNR1 1;
BA_ "GenSigSendType" SG_ 89 FLR2RdrDetn015To019SNR2 1;
BA_ "GenSigSendType" SG_ 89 FLR2RdrDetn015To019SNR3 1;
BA_ "GenSigSendType" SG_ 89 FLR2RdrDetn015To019SNR4 1;
BA_ "GenSigSendType" SG_ 89 FLR2RdrDetn015To019ScanID 1;
BA_ "GenSigSendType" SG_ 92 FLR2RdrDetn020To024AziAng0 1;
BA_ "GenSigSendType" SG_ 92 FLR2RdrDetn020To024AziAng1 1;
BA_ "GenSigSendType" SG_ 92 FLR2RdrDetn020To024AziAng2 1;
BA_ "GenSigSendType" SG_ 92 FLR2RdrDetn020To024AziAng3 1;
BA_ "GenSigSendType" SG_ 92 FLR2RdrDetn020To024AziAng4 1;
BA_ "GenSigDataID" SG_ 92 FLR2RdrDetn020To024CRC "0xABD";
BA_ "GenSigFuncType" SG_ 92 FLR2RdrDetn020To024CRC 28;
BA_ "GenSigSendType" SG_ 92 FLR2RdrDetn020To024CRC 1;
BA_ "GenSigFuncType" SG_ 92 FLR2RdrDetn020To024Counter 27;
BA_ "GenSigSendType" SG_ 92 FLR2RdrDetn020To024Counter 1;
BA_ "GenSigSendType" SG_ 92 FLR2RdrDetn020To024DynPrpty0 1;
BA_ "GenSigSendType" SG_ 92 FLR2RdrDetn020To024DynPrpty1 1;
BA_ "GenSigSendType" SG_ 92 FLR2RdrDetn020To024DynPrpty2 1;
BA_ "GenSigSendType" SG_ 92 FLR2RdrDetn020To024DynPrpty3 1;
BA_ "GenSigSendType" SG_ 92 FLR2RdrDetn020To024DynPrpty4 1;
BA_ "GenSigSendType" SG_ 92 FLR2RdrDetn020To024EleAng0 1;
BA_ "GenSigSendType" SG_ 92 FLR2RdrDetn020To024EleAng1 1;
BA_ "GenSigSendType" SG_ 92 FLR2RdrDetn020To024EleAng2 1;
BA_ "GenSigSendType" SG_ 92 FLR2RdrDetn020To024EleAng3 1;
BA_ "GenSigSendType" SG_ 92 FLR2RdrDetn020To024EleAng4 1;
BA_ "GenSigSendType" SG_ 92 FLR2RdrDetn020To024Mode0 1;
BA_ "GenSigSendType" SG_ 92 FLR2RdrDetn020To024Mode1 1;
BA_ "GenSigSendType" SG_ 92 FLR2RdrDetn020To024Mode2 1;
BA_ "GenSigSendType" SG_ 92 FLR2RdrDetn020To024Mode3 1;
BA_ "GenSigSendType" SG_ 92 FLR2RdrDetn020To024Mode4 1;
BA_ "GenSigSendType" SG_ 92 FLR2RdrDetn020To024Quality0 1;
BA_ "GenSigSendType" SG_ 92 FLR2RdrDetn020To024Quality1 1;
BA_ "GenSigSendType" SG_ 92 FLR2RdrDetn020To024Quality2 1;
BA_ "GenSigSendType" SG_ 92 FLR2RdrDetn020To024Quality3 1;
BA_ "GenSigSendType" SG_ 92 FLR2RdrDetn020To024Quality4 1;
BA_ "GenSigSendType" SG_ 92 FLR2RdrDetn020To024RCS0 1;
BA_ "GenSigStartValue" SG_ 92 FLR2RdrDetn020To024RCS0 500;
BA_ "GenSigSendType" SG_ 92 FLR2RdrDetn020To024RCS1 1;
BA_ "GenSigStartValue" SG_ 92 FLR2RdrDetn020To024RCS1 500;
BA_ "GenSigSendType" SG_ 92 FLR2RdrDetn020To024RCS2 1;
BA_ "GenSigStartValue" SG_ 92 FLR2RdrDetn020To024RCS2 500;
BA_ "GenSigSendType" SG_ 92 FLR2RdrDetn020To024RCS3 1;
BA_ "GenSigStartValue" SG_ 92 FLR2RdrDetn020To024RCS3 500;
BA_ "GenSigSendType" SG_ 92 FLR2RdrDetn020To024RCS4 1;
BA_ "GenSigStartValue" SG_ 92 FLR2RdrDetn020To024RCS4 500;
BA_ "GenSigSendType" SG_ 92 FLR2RdrDetn020To024Range0 1;
BA_ "GenSigSendType" SG_ 92 FLR2RdrDetn020To024Range1 1;
BA_ "GenSigSendType" SG_ 92 FLR2RdrDetn020To024Range2 1;
BA_ "GenSigSendType" SG_ 92 FLR2RdrDetn020To024Range3 1;
BA_ "GenSigSendType" SG_ 92 FLR2RdrDetn020To024Range4 1;
BA_ "GenSigSendType" SG_ 92 FLR2RdrDetn020To024RngRt0 1;
BA_ "GenSigStartValue" SG_ 92 FLR2RdrDetn020To024RngRt0 1111;
BA_ "GenSigSendType" SG_ 92 FLR2RdrDetn020To024RngRt1 1;
BA_ "GenSigStartValue" SG_ 92 FLR2RdrDetn020To024RngRt1 1111;
BA_ "GenSigSendType" SG_ 92 FLR2RdrDetn020To024RngRt2 1;
BA_ "GenSigStartValue" SG_ 92 FLR2RdrDetn020To024RngRt2 1111;
BA_ "GenSigSendType" SG_ 92 FLR2RdrDetn020To024RngRt3 1;
BA_ "GenSigStartValue" SG_ 92 FLR2RdrDetn020To024RngRt3 1111;
BA_ "GenSigSendType" SG_ 92 FLR2RdrDetn020To024RngRt4 1;
BA_ "GenSigStartValue" SG_ 92 FLR2RdrDetn020To024RngRt4 1111;
BA_ "GenSigSendType" SG_ 92 FLR2RdrDetn020To024SNR0 1;
BA_ "GenSigSendType" SG_ 92 FLR2RdrDetn020To024SNR1 1;
BA_ "GenSigSendType" SG_ 92 FLR2RdrDetn020To024SNR2 1;
BA_ "GenSigSendType" SG_ 92 FLR2RdrDetn020To024SNR3 1;
BA_ "GenSigSendType" SG_ 92 FLR2RdrDetn020To024SNR4 1;
BA_ "GenSigSendType" SG_ 92 FLR2RdrDetn020To024ScanID 1;
BA_ "GenSigSendType" SG_ 96 FLR2RdrDetn025To029AziAng0 1;
BA_ "GenSigSendType" SG_ 96 FLR2RdrDetn025To029AziAng1 1;
BA_ "GenSigSendType" SG_ 96 FLR2RdrDetn025To029AziAng2 1;
BA_ "GenSigSendType" SG_ 96 FLR2RdrDetn025To029AziAng3 1;
BA_ "GenSigSendType" SG_ 96 FLR2RdrDetn025To029AziAng4 1;
BA_ "GenSigDataID" SG_ 96 FLR2RdrDetn025To029CRC "0xABE";
BA_ "GenSigFuncType" SG_ 96 FLR2RdrDetn025To029CRC 28;
BA_ "GenSigSendType" SG_ 96 FLR2RdrDetn025To029CRC 1;
BA_ "GenSigFuncType" SG_ 96 FLR2RdrDetn025To029Counter 27;
BA_ "GenSigSendType" SG_ 96 FLR2RdrDetn025To029Counter 1;
BA_ "GenSigSendType" SG_ 96 FLR2RdrDetn025To029DynPrpty0 1;
BA_ "GenSigSendType" SG_ 96 FLR2RdrDetn025To029DynPrpty1 1;
BA_ "GenSigSendType" SG_ 96 FLR2RdrDetn025To029DynPrpty2 1;
BA_ "GenSigSendType" SG_ 96 FLR2RdrDetn025To029DynPrpty3 1;
BA_ "GenSigSendType" SG_ 96 FLR2RdrDetn025To029DynPrpty4 1;
BA_ "GenSigSendType" SG_ 96 FLR2RdrDetn025To029EleAng0 1;
BA_ "GenSigSendType" SG_ 96 FLR2RdrDetn025To029EleAng1 1;
BA_ "GenSigSendType" SG_ 96 FLR2RdrDetn025To029EleAng2 1;
BA_ "GenSigSendType" SG_ 96 FLR2RdrDetn025To029EleAng3 1;
BA_ "GenSigSendType" SG_ 96 FLR2RdrDetn025To029EleAng4 1;
BA_ "GenSigSendType" SG_ 96 FLR2RdrDetn025To029Mode0 1;
BA_ "GenSigSendType" SG_ 96 FLR2RdrDetn025To029Mode1 1;
BA_ "GenSigSendType" SG_ 96 FLR2RdrDetn025To029Mode2 1;
BA_ "GenSigSendType" SG_ 96 FLR2RdrDetn025To029Mode3 1;
BA_ "GenSigSendType" SG_ 96 FLR2RdrDetn025To029Mode4 1;
BA_ "GenSigSendType" SG_ 96 FLR2RdrDetn025To029Quality0 1;
BA_ "GenSigSendType" SG_ 96 FLR2RdrDetn025To029Quality1 1;
BA_ "GenSigSendType" SG_ 96 FLR2RdrDetn025To029Quality2 1;
BA_ "GenSigSendType" SG_ 96 FLR2RdrDetn025To029Quality3 1;
BA_ "GenSigSendType" SG_ 96 FLR2RdrDetn025To029Quality4 1;
BA_ "GenSigSendType" SG_ 96 FLR2RdrDetn025To029RCS0 1;
BA_ "GenSigStartValue" SG_ 96 FLR2RdrDetn025To029RCS0 500;
BA_ "GenSigSendType" SG_ 96 FLR2RdrDetn025To029RCS1 1;
BA_ "GenSigStartValue" SG_ 96 FLR2RdrDetn025To029RCS1 500;
BA_ "GenSigSendType" SG_ 96 FLR2RdrDetn025To029RCS2 1;
BA_ "GenSigStartValue" SG_ 96 FLR2RdrDetn025To029RCS2 500;
BA_ "GenSigSendType" SG_ 96 FLR2RdrDetn025To029RCS3 1;
BA_ "GenSigStartValue" SG_ 96 FLR2RdrDetn025To029RCS3 500;
BA_ "GenSigSendType" SG_ 96 FLR2RdrDetn025To029RCS4 1;
BA_ "GenSigStartValue" SG_ 96 FLR2RdrDetn025To029RCS4 500;
BA_ "GenSigSendType" SG_ 96 FLR2RdrDetn025To029Range0 1;
BA_ "GenSigSendType" SG_ 96 FLR2RdrDetn025To029Range1 1;
BA_ "GenSigSendType" SG_ 96 FLR2RdrDetn025To029Range2 1;
BA_ "GenSigSendType" SG_ 96 FLR2RdrDetn025To029Range3 1;
BA_ "GenSigSendType" SG_ 96 FLR2RdrDetn025To029Range4 1;
BA_ "GenSigSendType" SG_ 96 FLR2RdrDetn025To029RngRt0 1;
BA_ "GenSigStartValue" SG_ 96 FLR2RdrDetn025To029RngRt0 1111;
BA_ "GenSigSendType" SG_ 96 FLR2RdrDetn025To029RngRt1 1;
BA_ "GenSigStartValue" SG_ 96 FLR2RdrDetn025To029RngRt1 1111;
BA_ "GenSigSendType" SG_ 96 FLR2RdrDetn025To029RngRt2 1;
BA_ "GenSigStartValue" SG_ 96 FLR2RdrDetn025To029RngRt2 1111;
BA_ "GenSigSendType" SG_ 96 FLR2RdrDetn025To029RngRt3 1;
BA_ "GenSigStartValue" SG_ 96 FLR2RdrDetn025To029RngRt3 1111;
BA_ "GenSigSendType" SG_ 96 FLR2RdrDetn025To029RngRt4 1;
BA_ "GenSigStartValue" SG_ 96 FLR2RdrDetn025To029RngRt4 1111;
BA_ "GenSigSendType" SG_ 96 FLR2RdrDetn025To029SNR0 1;
BA_ "GenSigSendType" SG_ 96 FLR2RdrDetn025To029SNR1 1;
BA_ "GenSigSendType" SG_ 96 FLR2RdrDetn025To029SNR2 1;
BA_ "GenSigSendType" SG_ 96 FLR2RdrDetn025To029SNR3 1;
BA_ "GenSigSendType" SG_ 96 FLR2RdrDetn025To029SNR4 1;
BA_ "GenSigSendType" SG_ 96 FLR2RdrDetn025To029ScanID 1;
BA_ "GenSigSendType" SG_ 99 FLR2RdrDetn030To034AziAng0 1;
BA_ "GenSigSendType" SG_ 99 FLR2RdrDetn030To034AziAng1 1;
BA_ "GenSigSendType" SG_ 99 FLR2RdrDetn030To034AziAng2 1;
BA_ "GenSigSendType" SG_ 99 FLR2RdrDetn030To034AziAng3 1;
BA_ "GenSigSendType" SG_ 99 FLR2RdrDetn030To034AziAng4 1;
BA_ "GenSigDataID" SG_ 99 FLR2RdrDetn030To034CRC "0xABF";
BA_ "GenSigFuncType" SG_ 99 FLR2RdrDetn030To034CRC 28;
BA_ "GenSigSendType" SG_ 99 FLR2RdrDetn030To034CRC 1;
BA_ "GenSigFuncType" SG_ 99 FLR2RdrDetn030To034Counter 27;
BA_ "GenSigSendType" SG_ 99 FLR2RdrDetn030To034Counter 1;
BA_ "GenSigSendType" SG_ 99 FLR2RdrDetn030To034DynPrpty0 1;
BA_ "GenSigSendType" SG_ 99 FLR2RdrDetn030To034DynPrpty1 1;
BA_ "GenSigSendType" SG_ 99 FLR2RdrDetn030To034DynPrpty2 1;
BA_ "GenSigSendType" SG_ 99 FLR2RdrDetn030To034DynPrpty3 1;
BA_ "GenSigSendType" SG_ 99 FLR2RdrDetn030To034DynPrpty4 1;
BA_ "GenSigSendType" SG_ 99 FLR2RdrDetn030To034EleAng0 1;
BA_ "GenSigSendType" SG_ 99 FLR2RdrDetn030To034EleAng1 1;
BA_ "GenSigSendType" SG_ 99 FLR2RdrDetn030To034EleAng2 1;
BA_ "GenSigSendType" SG_ 99 FLR2RdrDetn030To034EleAng3 1;
BA_ "GenSigSendType" SG_ 99 FLR2RdrDetn030To034EleAng4 1;
BA_ "GenSigSendType" SG_ 99 FLR2RdrDetn030To034Mode0 1;
BA_ "GenSigSendType" SG_ 99 FLR2RdrDetn030To034Mode1 1;
BA_ "GenSigSendType" SG_ 99 FLR2RdrDetn030To034Mode2 1;
BA_ "GenSigSendType" SG_ 99 FLR2RdrDetn030To034Mode3 1;
BA_ "GenSigSendType" SG_ 99 FLR2RdrDetn030To034Mode4 1;
BA_ "GenSigSendType" SG_ 99 FLR2RdrDetn030To034Quality0 1;
BA_ "GenSigSendType" SG_ 99 FLR2RdrDetn030To034Quality1 1;
BA_ "GenSigSendType" SG_ 99 FLR2RdrDetn030To034Quality2 1;
BA_ "GenSigSendType" SG_ 99 FLR2RdrDetn030To034Quality3 1;
BA_ "GenSigSendType" SG_ 99 FLR2RdrDetn030To034Quality4 1;
BA_ "GenSigSendType" SG_ 99 FLR2RdrDetn030To034RCS0 1;
BA_ "GenSigStartValue" SG_ 99 FLR2RdrDetn030To034RCS0 500;
BA_ "GenSigSendType" SG_ 99 FLR2RdrDetn030To034RCS1 1;
BA_ "GenSigStartValue" SG_ 99 FLR2RdrDetn030To034RCS1 500;
BA_ "GenSigSendType" SG_ 99 FLR2RdrDetn030To034RCS2 1;
BA_ "GenSigStartValue" SG_ 99 FLR2RdrDetn030To034RCS2 500;
BA_ "GenSigSendType" SG_ 99 FLR2RdrDetn030To034RCS3 1;
BA_ "GenSigStartValue" SG_ 99 FLR2RdrDetn030To034RCS3 500;
BA_ "GenSigSendType" SG_ 99 FLR2RdrDetn030To034RCS4 1;
BA_ "GenSigStartValue" SG_ 99 FLR2RdrDetn030To034RCS4 500;
BA_ "GenSigSendType" SG_ 99 FLR2RdrDetn030To034Range0 1;
BA_ "GenSigSendType" SG_ 99 FLR2RdrDetn030To034Range1 1;
BA_ "GenSigSendType" SG_ 99 FLR2RdrDetn030To034Range2 1;
BA_ "GenSigSendType" SG_ 99 FLR2RdrDetn030To034Range3 1;
BA_ "GenSigSendType" SG_ 99 FLR2RdrDetn030To034Range4 1;
BA_ "GenSigSendType" SG_ 99 FLR2RdrDetn030To034RngRt0 1;
BA_ "GenSigStartValue" SG_ 99 FLR2RdrDetn030To034RngRt0 1111;
BA_ "GenSigSendType" SG_ 99 FLR2RdrDetn030To034RngRt1 1;
BA_ "GenSigStartValue" SG_ 99 FLR2RdrDetn030To034RngRt1 1111;
BA_ "GenSigSendType" SG_ 99 FLR2RdrDetn030To034RngRt2 1;
BA_ "GenSigStartValue" SG_ 99 FLR2RdrDetn030To034RngRt2 1111;
BA_ "GenSigSendType" SG_ 99 FLR2RdrDetn030To034RngRt3 1;
BA_ "GenSigStartValue" SG_ 99 FLR2RdrDetn030To034RngRt3 1111;
BA_ "GenSigSendType" SG_ 99 FLR2RdrDetn030To034RngRt4 1;
BA_ "GenSigStartValue" SG_ 99 FLR2RdrDetn030To034RngRt4 1111;
BA_ "GenSigSendType" SG_ 99 FLR2RdrDetn030To034SNR0 1;
BA_ "GenSigSendType" SG_ 99 FLR2RdrDetn030To034SNR1 1;
BA_ "GenSigSendType" SG_ 99 FLR2RdrDetn030To034SNR2 1;
BA_ "GenSigSendType" SG_ 99 FLR2RdrDetn030To034SNR3 1;
BA_ "GenSigSendType" SG_ 99 FLR2RdrDetn030To034SNR4 1;
BA_ "GenSigSendType" SG_ 99 FLR2RdrDetn030To034ScanID 1;
BA_ "GenSigSendType" SG_ 102 FLR2RdrDetn035To039AziAng0 1;
BA_ "GenSigSendType" SG_ 102 FLR2RdrDetn035To039AziAng1 1;
BA_ "GenSigSendType" SG_ 102 FLR2RdrDetn035To039AziAng2 1;
BA_ "GenSigSendType" SG_ 102 FLR2RdrDetn035To039AziAng3 1;
BA_ "GenSigSendType" SG_ 102 FLR2RdrDetn035To039AziAng4 1;
BA_ "GenSigDataID" SG_ 102 FLR2RdrDetn035To039CRC "0xAC0";
BA_ "GenSigFuncType" SG_ 102 FLR2RdrDetn035To039CRC 28;
BA_ "GenSigSendType" SG_ 102 FLR2RdrDetn035To039CRC 1;
BA_ "GenSigFuncType" SG_ 102 FLR2RdrDetn035To039Counter 27;
BA_ "GenSigSendType" SG_ 102 FLR2RdrDetn035To039Counter 1;
BA_ "GenSigSendType" SG_ 102 FLR2RdrDetn035To039DynPrpty0 1;
BA_ "GenSigSendType" SG_ 102 FLR2RdrDetn035To039DynPrpty1 1;
BA_ "GenSigSendType" SG_ 102 FLR2RdrDetn035To039DynPrpty2 1;
BA_ "GenSigSendType" SG_ 102 FLR2RdrDetn035To039DynPrpty3 1;
BA_ "GenSigSendType" SG_ 102 FLR2RdrDetn035To039DynPrpty4 1;
BA_ "GenSigSendType" SG_ 102 FLR2RdrDetn035To039EleAng0 1;
BA_ "GenSigSendType" SG_ 102 FLR2RdrDetn035To039EleAng1 1;
BA_ "GenSigSendType" SG_ 102 FLR2RdrDetn035To039EleAng2 1;
BA_ "GenSigSendType" SG_ 102 FLR2RdrDetn035To039EleAng3 1;
BA_ "GenSigSendType" SG_ 102 FLR2RdrDetn035To039EleAng4 1;
BA_ "GenSigSendType" SG_ 102 FLR2RdrDetn035To039Mode0 1;
BA_ "GenSigSendType" SG_ 102 FLR2RdrDetn035To039Mode1 1;
BA_ "GenSigSendType" SG_ 102 FLR2RdrDetn035To039Mode2 1;
BA_ "GenSigSendType" SG_ 102 FLR2RdrDetn035To039Mode3 1;
BA_ "GenSigSendType" SG_ 102 FLR2RdrDetn035To039Mode4 1;
BA_ "GenSigSendType" SG_ 102 FLR2RdrDetn035To039Quality0 1;
BA_ "GenSigSendType" SG_ 102 FLR2RdrDetn035To039Quality1 1;
BA_ "GenSigSendType" SG_ 102 FLR2RdrDetn035To039Quality2 1;
BA_ "GenSigSendType" SG_ 102 FLR2RdrDetn035To039Quality3 1;
BA_ "GenSigSendType" SG_ 102 FLR2RdrDetn035To039Quality4 1;
BA_ "GenSigSendType" SG_ 102 FLR2RdrDetn035To039RCS0 1;
BA_ "GenSigStartValue" SG_ 102 FLR2RdrDetn035To039RCS0 500;
BA_ "GenSigSendType" SG_ 102 FLR2RdrDetn035To039RCS1 1;
BA_ "GenSigStartValue" SG_ 102 FLR2RdrDetn035To039RCS1 500;
BA_ "GenSigSendType" SG_ 102 FLR2RdrDetn035To039RCS2 1;
BA_ "GenSigStartValue" SG_ 102 FLR2RdrDetn035To039RCS2 500;
BA_ "GenSigSendType" SG_ 102 FLR2RdrDetn035To039RCS3 1;
BA_ "GenSigStartValue" SG_ 102 FLR2RdrDetn035To039RCS3 500;
BA_ "GenSigSendType" SG_ 102 FLR2RdrDetn035To039RCS4 1;
BA_ "GenSigStartValue" SG_ 102 FLR2RdrDetn035To039RCS4 500;
BA_ "GenSigSendType" SG_ 102 FLR2RdrDetn035To039Range0 1;
BA_ "GenSigSendType" SG_ 102 FLR2RdrDetn035To039Range1 1;
BA_ "GenSigSendType" SG_ 102 FLR2RdrDetn035To039Range2 1;
BA_ "GenSigSendType" SG_ 102 FLR2RdrDetn035To039Range3 1;
BA_ "GenSigSendType" SG_ 102 FLR2RdrDetn035To039Range4 1;
BA_ "GenSigSendType" SG_ 102 FLR2RdrDetn035To039RngRt0 1;
BA_ "GenSigStartValue" SG_ 102 FLR2RdrDetn035To039RngRt0 1111;
BA_ "GenSigSendType" SG_ 102 FLR2RdrDetn035To039RngRt1 1;
BA_ "GenSigStartValue" SG_ 102 FLR2RdrDetn035To039RngRt1 1111;
BA_ "GenSigSendType" SG_ 102 FLR2RdrDetn035To039RngRt2 1;
BA_ "GenSigStartValue" SG_ 102 FLR2RdrDetn035To039RngRt2 1111;
BA_ "GenSigSendType" SG_ 102 FLR2RdrDetn035To039RngRt3 1;
BA_ "GenSigStartValue" SG_ 102 FLR2RdrDetn035To039RngRt3 1111;
BA_ "GenSigSendType" SG_ 102 FLR2RdrDetn035To039RngRt4 1;
BA_ "GenSigStartValue" SG_ 102 FLR2RdrDetn035To039RngRt4 1111;
BA_ "GenSigSendType" SG_ 102 FLR2RdrDetn035To039SNR0 1;
BA_ "GenSigSendType" SG_ 102 FLR2RdrDetn035To039SNR1 1;
BA_ "GenSigSendType" SG_ 102 FLR2RdrDetn035To039SNR2 1;
BA_ "GenSigSendType" SG_ 102 FLR2RdrDetn035To039SNR3 1;
BA_ "GenSigSendType" SG_ 102 FLR2RdrDetn035To039SNR4 1;
BA_ "GenSigSendType" SG_ 102 FLR2RdrDetn035To039ScanID 1;
BA_ "GenSigSendType" SG_ 105 FLR2RdrDetn040To044AziAng0 1;
BA_ "GenSigSendType" SG_ 105 FLR2RdrDetn040To044AziAng1 1;
BA_ "GenSigSendType" SG_ 105 FLR2RdrDetn040To044AziAng2 1;
BA_ "GenSigSendType" SG_ 105 FLR2RdrDetn040To044AziAng3 1;
BA_ "GenSigSendType" SG_ 105 FLR2RdrDetn040To044AziAng4 1;
BA_ "GenSigDataID" SG_ 105 FLR2RdrDetn040To044CRC "0xAC1";
BA_ "GenSigFuncType" SG_ 105 FLR2RdrDetn040To044CRC 28;
BA_ "GenSigSendType" SG_ 105 FLR2RdrDetn040To044CRC 1;
BA_ "GenSigFuncType" SG_ 105 FLR2RdrDetn040To044Counter 27;
BA_ "GenSigSendType" SG_ 105 FLR2RdrDetn040To044Counter 1;
BA_ "GenSigSendType" SG_ 105 FLR2RdrDetn040To044DynPrpty0 1;
BA_ "GenSigSendType" SG_ 105 FLR2RdrDetn040To044DynPrpty1 1;
BA_ "GenSigSendType" SG_ 105 FLR2RdrDetn040To044DynPrpty2 1;
BA_ "GenSigSendType" SG_ 105 FLR2RdrDetn040To044DynPrpty3 1;
BA_ "GenSigSendType" SG_ 105 FLR2RdrDetn040To044DynPrpty4 1;
BA_ "GenSigSendType" SG_ 105 FLR2RdrDetn040To044EleAng0 1;
BA_ "GenSigSendType" SG_ 105 FLR2RdrDetn040To044EleAng1 1;
BA_ "GenSigSendType" SG_ 105 FLR2RdrDetn040To044EleAng2 1;
BA_ "GenSigSendType" SG_ 105 FLR2RdrDetn040To044EleAng3 1;
BA_ "GenSigSendType" SG_ 105 FLR2RdrDetn040To044EleAng4 1;
BA_ "GenSigSendType" SG_ 105 FLR2RdrDetn040To044Mode0 1;
BA_ "GenSigSendType" SG_ 105 FLR2RdrDetn040To044Mode1 1;
BA_ "GenSigSendType" SG_ 105 FLR2RdrDetn040To044Mode2 1;
BA_ "GenSigSendType" SG_ 105 FLR2RdrDetn040To044Mode3 1;
BA_ "GenSigSendType" SG_ 105 FLR2RdrDetn040To044Mode4 1;
BA_ "GenSigSendType" SG_ 105 FLR2RdrDetn040To044Quality0 1;
BA_ "GenSigSendType" SG_ 105 FLR2RdrDetn040To044Quality1 1;
BA_ "GenSigSendType" SG_ 105 FLR2RdrDetn040To044Quality2 1;
BA_ "GenSigSendType" SG_ 105 FLR2RdrDetn040To044Quality3 1;
BA_ "GenSigSendType" SG_ 105 FLR2RdrDetn040To044Quality4 1;
BA_ "GenSigSendType" SG_ 105 FLR2RdrDetn040To044RCS0 1;
BA_ "GenSigStartValue" SG_ 105 FLR2RdrDetn040To044RCS0 500;
BA_ "GenSigSendType" SG_ 105 FLR2RdrDetn040To044RCS1 1;
BA_ "GenSigStartValue" SG_ 105 FLR2RdrDetn040To044RCS1 500;
BA_ "GenSigSendType" SG_ 105 FLR2RdrDetn040To044RCS2 1;
BA_ "GenSigStartValue" SG_ 105 FLR2RdrDetn040To044RCS2 500;
BA_ "GenSigSendType" SG_ 105 FLR2RdrDetn040To044RCS3 1;
BA_ "GenSigStartValue" SG_ 105 FLR2RdrDetn040To044RCS3 500;
BA_ "GenSigSendType" SG_ 105 FLR2RdrDetn040To044RCS4 1;
BA_ "GenSigStartValue" SG_ 105 FLR2RdrDetn040To044RCS4 500;
BA_ "GenSigSendType" SG_ 105 FLR2RdrDetn040To044Range0 1;
BA_ "GenSigSendType" SG_ 105 FLR2RdrDetn040To044Range1 1;
BA_ "GenSigSendType" SG_ 105 FLR2RdrDetn040To044Range2 1;
BA_ "GenSigSendType" SG_ 105 FLR2RdrDetn040To044Range3 1;
BA_ "GenSigSendType" SG_ 105 FLR2RdrDetn040To044Range4 1;
BA_ "GenSigSendType" SG_ 105 FLR2RdrDetn040To044RngRt0 1;
BA_ "GenSigStartValue" SG_ 105 FLR2RdrDetn040To044RngRt0 1111;
BA_ "GenSigSendType" SG_ 105 FLR2RdrDetn040To044RngRt1 1;
BA_ "GenSigStartValue" SG_ 105 FLR2RdrDetn040To044RngRt1 1111;
BA_ "GenSigSendType" SG_ 105 FLR2RdrDetn040To044RngRt2 1;
BA_ "GenSigStartValue" SG_ 105 FLR2RdrDetn040To044RngRt2 1111;
BA_ "GenSigSendType" SG_ 105 FLR2RdrDetn040To044RngRt3 1;
BA_ "GenSigStartValue" SG_ 105 FLR2RdrDetn040To044RngRt3 1111;
BA_ "GenSigSendType" SG_ 105 FLR2RdrDetn040To044RngRt4 1;
BA_ "GenSigStartValue" SG_ 105 FLR2RdrDetn040To044RngRt4 1111;
BA_ "GenSigSendType" SG_ 105 FLR2RdrDetn040To044SNR0 1;
BA_ "GenSigSendType" SG_ 105 FLR2RdrDetn040To044SNR1 1;
BA_ "GenSigSendType" SG_ 105 FLR2RdrDetn040To044SNR2 1;
BA_ "GenSigSendType" SG_ 105 FLR2RdrDetn040To044SNR3 1;
BA_ "GenSigSendType" SG_ 105 FLR2RdrDetn040To044SNR4 1;
BA_ "GenSigSendType" SG_ 105 FLR2RdrDetn040To044ScanID 1;
BA_ "GenSigSendType" SG_ 108 FLR2RdrDetn045To049AziAng0 1;
BA_ "GenSigSendType" SG_ 108 FLR2RdrDetn045To049AziAng1 1;
BA_ "GenSigSendType" SG_ 108 FLR2RdrDetn045To049AziAng2 1;
BA_ "GenSigSendType" SG_ 108 FLR2RdrDetn045To049AziAng3 1;
BA_ "GenSigSendType" SG_ 108 FLR2RdrDetn045To049AziAng4 1;
BA_ "GenSigDataID" SG_ 108 FLR2RdrDetn045To049CRC "0xAC2";
BA_ "GenSigFuncType" SG_ 108 FLR2RdrDetn045To049CRC 28;
BA_ "GenSigSendType" SG_ 108 FLR2RdrDetn045To049CRC 1;
BA_ "GenSigFuncType" SG_ 108 FLR2RdrDetn045To049Counter 27;
BA_ "GenSigSendType" SG_ 108 FLR2RdrDetn045To049Counter 1;
BA_ "GenSigSendType" SG_ 108 FLR2RdrDetn045To049DynPrpty0 1;
BA_ "GenSigSendType" SG_ 108 FLR2RdrDetn045To049DynPrpty1 1;
BA_ "GenSigSendType" SG_ 108 FLR2RdrDetn045To049DynPrpty2 1;
BA_ "GenSigSendType" SG_ 108 FLR2RdrDetn045To049DynPrpty3 1;
BA_ "GenSigSendType" SG_ 108 FLR2RdrDetn045To049DynPrpty4 1;
BA_ "GenSigSendType" SG_ 108 FLR2RdrDetn045To049EleAng0 1;
BA_ "GenSigSendType" SG_ 108 FLR2RdrDetn045To049EleAng1 1;
BA_ "GenSigSendType" SG_ 108 FLR2RdrDetn045To049EleAng2 1;
BA_ "GenSigSendType" SG_ 108 FLR2RdrDetn045To049EleAng3 1;
BA_ "GenSigSendType" SG_ 108 FLR2RdrDetn045To049EleAng4 1;
BA_ "GenSigSendType" SG_ 108 FLR2RdrDetn045To049Mode0 1;
BA_ "GenSigSendType" SG_ 108 FLR2RdrDetn045To049Mode1 1;
BA_ "GenSigSendType" SG_ 108 FLR2RdrDetn045To049Mode2 1;
BA_ "GenSigSendType" SG_ 108 FLR2RdrDetn045To049Mode3 1;
BA_ "GenSigSendType" SG_ 108 FLR2RdrDetn045To049Mode4 1;
BA_ "GenSigSendType" SG_ 108 FLR2RdrDetn045To049Quality0 1;
BA_ "GenSigSendType" SG_ 108 FLR2RdrDetn045To049Quality1 1;
BA_ "GenSigSendType" SG_ 108 FLR2RdrDetn045To049Quality2 1;
BA_ "GenSigSendType" SG_ 108 FLR2RdrDetn045To049Quality3 1;
BA_ "GenSigSendType" SG_ 108 FLR2RdrDetn045To049Quality4 1;
BA_ "GenSigSendType" SG_ 108 FLR2RdrDetn045To049RCS0 1;
BA_ "GenSigStartValue" SG_ 108 FLR2RdrDetn045To049RCS0 500;
BA_ "GenSigSendType" SG_ 108 FLR2RdrDetn045To049RCS1 1;
BA_ "GenSigStartValue" SG_ 108 FLR2RdrDetn045To049RCS1 500;
BA_ "GenSigSendType" SG_ 108 FLR2RdrDetn045To049RCS2 1;
BA_ "GenSigStartValue" SG_ 108 FLR2RdrDetn045To049RCS2 500;
BA_ "GenSigSendType" SG_ 108 FLR2RdrDetn045To049RCS3 1;
BA_ "GenSigStartValue" SG_ 108 FLR2RdrDetn045To049RCS3 500;
BA_ "GenSigSendType" SG_ 108 FLR2RdrDetn045To049RCS4 1;
BA_ "GenSigStartValue" SG_ 108 FLR2RdrDetn045To049RCS4 500;
BA_ "GenSigSendType" SG_ 108 FLR2RdrDetn045To049Range0 1;
BA_ "GenSigSendType" SG_ 108 FLR2RdrDetn045To049Range1 1;
BA_ "GenSigSendType" SG_ 108 FLR2RdrDetn045To049Range2 1;
BA_ "GenSigSendType" SG_ 108 FLR2RdrDetn045To049Range3 1;
BA_ "GenSigSendType" SG_ 108 FLR2RdrDetn045To049Range4 1;
BA_ "GenSigSendType" SG_ 108 FLR2RdrDetn045To049RngRt0 1;
BA_ "GenSigStartValue" SG_ 108 FLR2RdrDetn045To049RngRt0 1111;
BA_ "GenSigSendType" SG_ 108 FLR2RdrDetn045To049RngRt1 1;
BA_ "GenSigStartValue" SG_ 108 FLR2RdrDetn045To049RngRt1 1111;
BA_ "GenSigSendType" SG_ 108 FLR2RdrDetn045To049RngRt2 1;
BA_ "GenSigStartValue" SG_ 108 FLR2RdrDetn045To049RngRt2 1111;
BA_ "GenSigSendType" SG_ 108 FLR2RdrDetn045To049RngRt3 1;
BA_ "GenSigStartValue" SG_ 108 FLR2RdrDetn045To049RngRt3 1111;
BA_ "GenSigSendType" SG_ 108 FLR2RdrDetn045To049RngRt4 1;
BA_ "GenSigStartValue" SG_ 108 FLR2RdrDetn045To049RngRt4 1111;
BA_ "GenSigSendType" SG_ 108 FLR2RdrDetn045To049SNR0 1;
BA_ "GenSigSendType" SG_ 108 FLR2RdrDetn045To049SNR1 1;
BA_ "GenSigSendType" SG_ 108 FLR2RdrDetn045To049SNR2 1;
BA_ "GenSigSendType" SG_ 108 FLR2RdrDetn045To049SNR3 1;
BA_ "GenSigSendType" SG_ 108 FLR2RdrDetn045To049SNR4 1;
BA_ "GenSigSendType" SG_ 108 FLR2RdrDetn045To049ScanID 1;
BA_ "GenSigSendType" SG_ 112 FLR2RdrDetn050To054AziAng0 1;
BA_ "GenSigSendType" SG_ 112 FLR2RdrDetn050To054AziAng1 1;
BA_ "GenSigSendType" SG_ 112 FLR2RdrDetn050To054AziAng2 1;
BA_ "GenSigSendType" SG_ 112 FLR2RdrDetn050To054AziAng3 1;
BA_ "GenSigSendType" SG_ 112 FLR2RdrDetn050To054AziAng4 1;
BA_ "GenSigDataID" SG_ 112 FLR2RdrDetn050To054CRC "0xAC3";
BA_ "GenSigFuncType" SG_ 112 FLR2RdrDetn050To054CRC 28;
BA_ "GenSigSendType" SG_ 112 FLR2RdrDetn050To054CRC 1;
BA_ "GenSigFuncType" SG_ 112 FLR2RdrDetn050To054Counter 27;
BA_ "GenSigSendType" SG_ 112 FLR2RdrDetn050To054Counter 1;
BA_ "GenSigSendType" SG_ 112 FLR2RdrDetn050To054DynPrpty0 1;
BA_ "GenSigSendType" SG_ 112 FLR2RdrDetn050To054DynPrpty1 1;
BA_ "GenSigSendType" SG_ 112 FLR2RdrDetn050To054DynPrpty2 1;
BA_ "GenSigSendType" SG_ 112 FLR2RdrDetn050To054DynPrpty3 1;
BA_ "GenSigSendType" SG_ 112 FLR2RdrDetn050To054DynPrpty4 1;
BA_ "GenSigSendType" SG_ 112 FLR2RdrDetn050To054EleAng0 1;
BA_ "GenSigSendType" SG_ 112 FLR2RdrDetn050To054EleAng1 1;
BA_ "GenSigSendType" SG_ 112 FLR2RdrDetn050To054EleAng2 1;
BA_ "GenSigSendType" SG_ 112 FLR2RdrDetn050To054EleAng3 1;
BA_ "GenSigSendType" SG_ 112 FLR2RdrDetn050To054EleAng4 1;
BA_ "GenSigSendType" SG_ 112 FLR2RdrDetn050To054Mode0 1;
BA_ "GenSigSendType" SG_ 112 FLR2RdrDetn050To054Mode1 1;
BA_ "GenSigSendType" SG_ 112 FLR2RdrDetn050To054Mode2 1;
BA_ "GenSigSendType" SG_ 112 FLR2RdrDetn050To054Mode3 1;
BA_ "GenSigSendType" SG_ 112 FLR2RdrDetn050To054Mode4 1;
BA_ "GenSigSendType" SG_ 112 FLR2RdrDetn050To054Quality0 1;
BA_ "GenSigSendType" SG_ 112 FLR2RdrDetn050To054Quality1 1;
BA_ "GenSigSendType" SG_ 112 FLR2RdrDetn050To054Quality2 1;
BA_ "GenSigSendType" SG_ 112 FLR2RdrDetn050To054Quality3 1;
BA_ "GenSigSendType" SG_ 112 FLR2RdrDetn050To054Quality4 1;
BA_ "GenSigSendType" SG_ 112 FLR2RdrDetn050To054RCS0 1;
BA_ "GenSigStartValue" SG_ 112 FLR2RdrDetn050To054RCS0 500;
BA_ "GenSigSendType" SG_ 112 FLR2RdrDetn050To054RCS1 1;
BA_ "GenSigStartValue" SG_ 112 FLR2RdrDetn050To054RCS1 500;
BA_ "GenSigSendType" SG_ 112 FLR2RdrDetn050To054RCS2 1;
BA_ "GenSigStartValue" SG_ 112 FLR2RdrDetn050To054RCS2 500;
BA_ "GenSigSendType" SG_ 112 FLR2RdrDetn050To054RCS3 1;
BA_ "GenSigStartValue" SG_ 112 FLR2RdrDetn050To054RCS3 500;
BA_ "GenSigSendType" SG_ 112 FLR2RdrDetn050To054RCS4 1;
BA_ "GenSigStartValue" SG_ 112 FLR2RdrDetn050To054RCS4 500;
BA_ "GenSigSendType" SG_ 112 FLR2RdrDetn050To054Range0 1;
BA_ "GenSigSendType" SG_ 112 FLR2RdrDetn050To054Range1 1;
BA_ "GenSigSendType" SG_ 112 FLR2RdrDetn050To054Range2 1;
BA_ "GenSigSendType" SG_ 112 FLR2RdrDetn050To054Range3 1;
BA_ "GenSigSendType" SG_ 112 FLR2RdrDetn050To054Range4 1;
BA_ "GenSigSendType" SG_ 112 FLR2RdrDetn050To054RngRt0 1;
BA_ "GenSigStartValue" SG_ 112 FLR2RdrDetn050To054RngRt0 1111;
BA_ "GenSigSendType" SG_ 112 FLR2RdrDetn050To054RngRt1 1;
BA_ "GenSigStartValue" SG_ 112 FLR2RdrDetn050To054RngRt1 1111;
BA_ "GenSigSendType" SG_ 112 FLR2RdrDetn050To054RngRt2 1;
BA_ "GenSigStartValue" SG_ 112 FLR2RdrDetn050To054RngRt2 1111;
BA_ "GenSigSendType" SG_ 112 FLR2RdrDetn050To054RngRt3 1;
BA_ "GenSigStartValue" SG_ 112 FLR2RdrDetn050To054RngRt3 1111;
BA_ "GenSigSendType" SG_ 112 FLR2RdrDetn050To054RngRt4 1;
BA_ "GenSigStartValue" SG_ 112 FLR2RdrDetn050To054RngRt4 1111;
BA_ "GenSigSendType" SG_ 112 FLR2RdrDetn050To054SNR0 1;
BA_ "GenSigSendType" SG_ 112 FLR2RdrDetn050To054SNR1 1;
BA_ "GenSigSendType" SG_ 112 FLR2RdrDetn050To054SNR2 1;
BA_ "GenSigSendType" SG_ 112 FLR2RdrDetn050To054SNR3 1;
BA_ "GenSigSendType" SG_ 112 FLR2RdrDetn050To054SNR4 1;
BA_ "GenSigSendType" SG_ 112 FLR2RdrDetn050To054ScanID 1;
BA_ "GenSigSendType" SG_ 115 FLR2RdrDetn055To059AziAng0 1;
BA_ "GenSigSendType" SG_ 115 FLR2RdrDetn055To059AziAng1 1;
BA_ "GenSigSendType" SG_ 115 FLR2RdrDetn055To059AziAng2 1;
BA_ "GenSigSendType" SG_ 115 FLR2RdrDetn055To059AziAng3 1;
BA_ "GenSigSendType" SG_ 115 FLR2RdrDetn055To059AziAng4 1;
BA_ "GenSigDataID" SG_ 115 FLR2RdrDetn055To059CRC "0xAC4";
BA_ "GenSigFuncType" SG_ 115 FLR2RdrDetn055To059CRC 28;
BA_ "GenSigSendType" SG_ 115 FLR2RdrDetn055To059CRC 1;
BA_ "GenSigFuncType" SG_ 115 FLR2RdrDetn055To059Counter 27;
BA_ "GenSigSendType" SG_ 115 FLR2RdrDetn055To059Counter 1;
BA_ "GenSigSendType" SG_ 115 FLR2RdrDetn055To059DynPrpty0 1;
BA_ "GenSigSendType" SG_ 115 FLR2RdrDetn055To059DynPrpty1 1;
BA_ "GenSigSendType" SG_ 115 FLR2RdrDetn055To059DynPrpty2 1;
BA_ "GenSigSendType" SG_ 115 FLR2RdrDetn055To059DynPrpty3 1;
BA_ "GenSigSendType" SG_ 115 FLR2RdrDetn055To059DynPrpty4 1;
BA_ "GenSigSendType" SG_ 115 FLR2RdrDetn055To059EleAng0 1;
BA_ "GenSigSendType" SG_ 115 FLR2RdrDetn055To059EleAng1 1;
BA_ "GenSigSendType" SG_ 115 FLR2RdrDetn055To059EleAng2 1;
BA_ "GenSigSendType" SG_ 115 FLR2RdrDetn055To059EleAng3 1;
BA_ "GenSigSendType" SG_ 115 FLR2RdrDetn055To059EleAng4 1;
BA_ "GenSigSendType" SG_ 115 FLR2RdrDetn055To059Mode0 1;
BA_ "GenSigSendType" SG_ 115 FLR2RdrDetn055To059Mode1 1;
BA_ "GenSigSendType" SG_ 115 FLR2RdrDetn055To059Mode2 1;
BA_ "GenSigSendType" SG_ 115 FLR2RdrDetn055To059Mode3 1;
BA_ "GenSigSendType" SG_ 115 FLR2RdrDetn055To059Mode4 1;
BA_ "GenSigSendType" SG_ 115 FLR2RdrDetn055To059Quality0 1;
BA_ "GenSigSendType" SG_ 115 FLR2RdrDetn055To059Quality1 1;
BA_ "GenSigSendType" SG_ 115 FLR2RdrDetn055To059Quality2 1;
BA_ "GenSigSendType" SG_ 115 FLR2RdrDetn055To059Quality3 1;
BA_ "GenSigSendType" SG_ 115 FLR2RdrDetn055To059Quality4 1;
BA_ "GenSigSendType" SG_ 115 FLR2RdrDetn055To059RCS0 1;
BA_ "GenSigStartValue" SG_ 115 FLR2RdrDetn055To059RCS0 500;
BA_ "GenSigSendType" SG_ 115 FLR2RdrDetn055To059RCS1 1;
BA_ "GenSigStartValue" SG_ 115 FLR2RdrDetn055To059RCS1 500;
BA_ "GenSigSendType" SG_ 115 FLR2RdrDetn055To059RCS2 1;
BA_ "GenSigStartValue" SG_ 115 FLR2RdrDetn055To059RCS2 500;
BA_ "GenSigSendType" SG_ 115 FLR2RdrDetn055To059RCS3 1;
BA_ "GenSigStartValue" SG_ 115 FLR2RdrDetn055To059RCS3 500;
BA_ "GenSigSendType" SG_ 115 FLR2RdrDetn055To059RCS4 1;
BA_ "GenSigStartValue" SG_ 115 FLR2RdrDetn055To059RCS4 500;
BA_ "GenSigSendType" SG_ 115 FLR2RdrDetn055To059Range0 1;
BA_ "GenSigSendType" SG_ 115 FLR2RdrDetn055To059Range1 1;
BA_ "GenSigSendType" SG_ 115 FLR2RdrDetn055To059Range2 1;
BA_ "GenSigSendType" SG_ 115 FLR2RdrDetn055To059Range3 1;
BA_ "GenSigSendType" SG_ 115 FLR2RdrDetn055To059Range4 1;
BA_ "GenSigSendType" SG_ 115 FLR2RdrDetn055To059RngRt0 1;
BA_ "GenSigStartValue" SG_ 115 FLR2RdrDetn055To059RngRt0 1111;
BA_ "GenSigSendType" SG_ 115 FLR2RdrDetn055To059RngRt1 1;
BA_ "GenSigStartValue" SG_ 115 FLR2RdrDetn055To059RngRt1 1111;
BA_ "GenSigSendType" SG_ 115 FLR2RdrDetn055To059RngRt2 1;
BA_ "GenSigStartValue" SG_ 115 FLR2RdrDetn055To059RngRt2 1111;
BA_ "GenSigSendType" SG_ 115 FLR2RdrDetn055To059RngRt3 1;
BA_ "GenSigStartValue" SG_ 115 FLR2RdrDetn055To059RngRt3 1111;
BA_ "GenSigSendType" SG_ 115 FLR2RdrDetn055To059RngRt4 1;
BA_ "GenSigStartValue" SG_ 115 FLR2RdrDetn055To059RngRt4 1111;
BA_ "GenSigSendType" SG_ 115 FLR2RdrDetn055To059SNR0 1;
BA_ "GenSigSendType" SG_ 115 FLR2RdrDetn055To059SNR1 1;
BA_ "GenSigSendType" SG_ 115 FLR2RdrDetn055To059SNR2 1;
BA_ "GenSigSendType" SG_ 115 FLR2RdrDetn055To059SNR3 1;
BA_ "GenSigSendType" SG_ 115 FLR2RdrDetn055To059SNR4 1;
BA_ "GenSigSendType" SG_ 115 FLR2RdrDetn055To059ScanID 1;
BA_ "GenSigSendType" SG_ 576 FuncInfoAntilockBrakingSystemState 0;
BA_ "GenSigSendType" SG_ 576 FuncInfoBrkTracCtrlActv 0;
BA_ "GenSigDataID" SG_ 576 FuncInfoCRC "0xB7A";
BA_ "GenSigFuncType" SG_ 576 FuncInfoCRC 28;
BA_ "GenSigSendType" SG_ 576 FuncInfoCRC 0;
BA_ "GenSigFuncType" SG_ 576 FuncInfoCounter 27;
BA_ "GenSigSendType" SG_ 576 FuncInfoCounter 0;
BA_ "GenSigDataID" SG_ 544 GlobalSnapShotRdrCRC "0xD1C";
BA_ "GenSigFuncType" SG_ 544 GlobalSnapShotRdrCRC 28;
BA_ "GenSigSendType" SG_ 544 GlobalSnapShotRdrCRC 0;
BA_ "GenSigFuncType" SG_ 544 GlobalSnapShotRdrCounter 27;
BA_ "GenSigSendType" SG_ 544 GlobalSnapShotRdrCounter 0;
BA_ "GenSigSendType" SG_ 544 GlobalSnapShotRdrGlobalRealTimeRdr 0;
BA_ "GenSigStartValue" SG_ 544 GlobalSnapShotRdrGlobalRealTimeRdr 4294967295;
BA_ "GenSigSendType" SG_ 544 GlobalSnapShotRdrOutsideTemperatureRdr 0;
BA_ "GenSigStartValue" SG_ 544 GlobalSnapShotRdrOutsideTemperatureRdr -32768;
BA_ "GenSigSendType" SG_ 544 GlobalSnapShotRdrTotalDistanceRdr 0;
BA_ "GenSigStartValue" SG_ 544 GlobalSnapShotRdrTotalDistanceRdr 4294967295;
BA_ "GenSigSendType" SG_ 544 GlobalSnapShotRdrUsageModeRdr 0;
BA_ "GenSigSendType" SG_ 544 GlobalSnapShotRdrVehicleBatteryVoltageRdr 0;
BA_ "GenSigStartValue" SG_ 544 GlobalSnapShotRdrVehicleBatteryVoltageRdr 255;
BA_ "GenSigSendType" SG_ 544 GlobalSnapShotRdrVehicleSpeedRdr 0;
BA_ "GenSigStartValue" SG_ 544 GlobalSnapShotRdrVehicleSpeedRdr 255;
BA_ "GenSigDataID" SG_ 528 PowerModeFLRCRC "0xD0B";
BA_ "GenSigFuncType" SG_ 528 PowerModeFLRCRC 28;
BA_ "GenSigSendType" SG_ 528 PowerModeFLRCRC 0;
BA_ "GenSigFuncType" SG_ 528 PowerModeFLRCounter 27;
BA_ "GenSigSendType" SG_ 528 PowerModeFLRCounter 0;
BA_ "GenSigSendType" SG_ 528 PowerModeFLRRdrActvnReq 0;
BA_ "GenSigSendType" SG_ 528 PowerModeFLRRdrPwrlossNoti 0;
BA_ "GenSigDataID" SG_ 560 VehicleModesProviderCRC "0xA47";
BA_ "GenSigFuncType" SG_ 560 VehicleModesProviderCRC 28;
BA_ "GenSigSendType" SG_ 560 VehicleModesProviderCRC 0;
BA_ "GenSigSendType" SG_ 560 VehicleModesProviderCarModSts 0;
BA_ "GenSigSendType" SG_ 560 VehicleModesProviderCarModSubtypWd 0;
BA_ "GenSigFuncType" SG_ 560 VehicleModesProviderCounter 27;
BA_ "GenSigSendType" SG_ 560 VehicleModesProviderCounter 0;
BA_ "GenSigSendType" SG_ 560 VehicleModesProviderUsageModeAvailable 0;
BA_ "GenSigStartValue" SG_ 560 VehicleModesProviderUsageModeAvailable 1;
BA_ "GenSigSendType" SG_ 560 VehicleModesProviderUsageModeAwake 0;
BA_ "GenSigStartValue" SG_ 560 VehicleModesProviderUsageModeAwake 1;
BA_ "GenSigSendType" SG_ 560 VehicleModesProviderUsageModeConvenience 0;
BA_ "GenSigStartValue" SG_ 560 VehicleModesProviderUsageModeConvenience 1;
BA_ "GenSigSendType" SG_ 560 VehicleModesProviderUsageModeDriving 0;
BA_ "GenSigStartValue" SG_ 560 VehicleModesProviderUsageModeDriving 1;
BA_ "GenSigSendType" SG_ 560 VehicleModesProviderUsageModeMovable 0;
BA_ "GenSigStartValue" SG_ 560 VehicleModesProviderUsageModeMovable 1;
BA_ "GenSigSendType" SG_ 560 VehicleModesProviderUsageModeResponsive 0;
BA_ "GenSigStartValue" SG_ 560 VehicleModesProviderUsageModeResponsive 1;
BA_ "GenSigSendType" SG_ 512 VehicleMotionStateAcceleroMeterLateral 0;
BA_ "GenSigStartValue" SG_ 512 VehicleMotionStateAcceleroMeterLateral 16352;
BA_ "GenSigSendType" SG_ 512 VehicleMotionStateAccelerometerLateralQuality 0;
BA_ "GenSigStartValue" SG_ 512 VehicleMotionStateAccelerometerLateralQuality 1;
BA_ "GenSigSendType" SG_ 512 VehicleMotionStateAccelerometerLongitudinal 0;
BA_ "GenSigStartValue" SG_ 512 VehicleMotionStateAccelerometerLongitudinal 16352;
BA_ "GenSigSendType" SG_ 512 VehicleMotionStateAccelerometerLongitudinalQuality 0;
BA_ "GenSigStartValue" SG_ 512 VehicleMotionStateAccelerometerLongitudinalQuality 1;
BA_ "GenSigSendType" SG_ 512 VehicleMotionStateAccelerometerVertical 0;
BA_ "GenSigStartValue" SG_ 512 VehicleMotionStateAccelerometerVertical 16352;
BA_ "GenSigSendType" SG_ 512 VehicleMotionStateAccelerometerVerticalQuality 0;
BA_ "GenSigStartValue" SG_ 512 VehicleMotionStateAccelerometerVerticalQuality 1;
BA_ "GenSigSendType" SG_ 512 VehicleMotionStateAngularVelocityRoll 0;
BA_ "GenSigStartValue" SG_ 512 VehicleMotionStateAngularVelocityRoll 32768;
BA_ "GenSigSendType" SG_ 512 VehicleMotionStateAngularVelocityRollQuality 0;
BA_ "GenSigStartValue" SG_ 512 VehicleMotionStateAngularVelocityRollQuality 1;
BA_ "GenSigSendType" SG_ 512 VehicleMotionStateAngularVelocityYaw 0;
BA_ "GenSigStartValue" SG_ 512 VehicleMotionStateAngularVelocityYaw 32768;
BA_ "GenSigSendType" SG_ 512 VehicleMotionStateAngularVelocityYawQuality 0;
BA_ "GenSigStartValue" SG_ 512 VehicleMotionStateAngularVelocityYawQuality 1;
BA_ "GenSigDataID" SG_ 512 VehicleMotionStateCRC "0xA33";
BA_ "GenSigFuncType" SG_ 512 VehicleMotionStateCRC 28;
BA_ "GenSigSendType" SG_ 512 VehicleMotionStateCRC 0;
BA_ "GenSigFuncType" SG_ 512 VehicleMotionStateCounter 27;
BA_ "GenSigSendType" SG_ 512 VehicleMotionStateCounter 0;
BA_ "GenSigSendType" SG_ 512 VehicleMotionStateMovingDirection 0;
BA_ "GenSigSendType" SG_ 512 VehicleMotionStateMovingDirectionQuality 0;
BA_ "GenSigStartValue" SG_ 512 VehicleMotionStateMovingDirectionQuality 1;
BA_ "GenSigSendType" SG_ 512 VehicleMotionStateVelocityLongitudinal 0;
BA_ "GenSigSendType" SG_ 512 VehicleMotionStateVelocityLongitudinalQuality 0;
BA_ "GenSigStartValue" SG_ 512 VehicleMotionStateVelocityLongitudinalQuality 1;
BA_ "GenSigSendType" SG_ 512 VehicleMotionStateWheelAngle 0;
BA_ "GenSigStartValue" SG_ 512 VehicleMotionStateWheelAngle 32386.9994285;
BA_ "GenSigSendType" SG_ 512 VehicleMotionStateWheelAngleQuality 0;
BA_ "GenSigStartValue" SG_ 512 VehicleMotionStateWheelAngleQuality 1;
BA_ "GenSigSendType" SG_ 512 VehicleMotionStateWheelAngularVelocityFrontLeft 0;
BA_ "GenSigStartValue" SG_ 512 VehicleMotionStateWheelAngularVelocityFrontLeft 32640;
BA_ "GenSigSendType" SG_ 512 VehicleMotionStateWheelAngularVelocityFrontLeftQuality 0;
BA_ "GenSigStartValue" SG_ 512 VehicleMotionStateWheelAngularVelocityFrontLeftQuality 1;
BA_ "GenSigSendType" SG_ 512 VehicleMotionStateWheelAngularVelocityFrontRight 0;
BA_ "GenSigStartValue" SG_ 512 VehicleMotionStateWheelAngularVelocityFrontRight 32640;
BA_ "GenSigSendType" SG_ 512 VehicleMotionStateWheelAngularVelocityFrontRightQuality 0;
BA_ "GenSigStartValue" SG_ 512 VehicleMotionStateWheelAngularVelocityFrontRightQuality 1;
BA_ "GenSigSendType" SG_ 512 VehicleMotionStateWheelAngularVelocityRearLeft 0;
BA_ "GenSigStartValue" SG_ 512 VehicleMotionStateWheelAngularVelocityRearLeft 32640;
BA_ "GenSigSendType" SG_ 512 VehicleMotionStateWheelAngularVelocityRearLeftQuality 0;
BA_ "GenSigStartValue" SG_ 512 VehicleMotionStateWheelAngularVelocityRearLeftQuality 1;
BA_ "GenSigSendType" SG_ 512 VehicleMotionStateWheelAngularVelocityRearRight 0;
BA_ "GenSigStartValue" SG_ 512 VehicleMotionStateWheelAngularVelocityRearRight 32640;
BA_ "GenSigSendType" SG_ 512 VehicleMotionStateWheelAngularVelocityRearRightQuality 0;
BA_ "GenSigStartValue" SG_ 512 VehicleMotionStateWheelAngularVelocityRearRightQuality 1;

VAL_ 512 VehicleMotionStateAccelerometerLateralQuality 0 "QualityOfEstimate_Error" 1 "QualityOfEstimate_Unknown" 2 "QualityOfEstimate_Low" 3 "QualityOfEstimate_Medium" 4 "QualityOfEstimate_High" 5 "QualityOfEstimate_Full";
VAL_ 512 VehicleMotionStateAccelerometerLongitudinalQuality 0 "QualityOfEstimate_Error" 1 "QualityOfEstimate_Unknown" 2 "QualityOfEstimate_Low" 3 "QualityOfEstimate_Medium" 4 "QualityOfEstimate_High" 5 "QualityOfEstimate_Full";
VAL_ 512 VehicleMotionStateAccelerometerVerticalQuality 0 "QualityOfEstimate_Error" 1 "QualityOfEstimate_Unknown" 2 "QualityOfEstimate_Low" 3 "QualityOfEstimate_Medium" 4 "QualityOfEstimate_High" 5 "QualityOfEstimate_Full";
VAL_ 512 VehicleMotionStateAngularVelocityRollQuality 0 "QualityOfEstimate_Error" 1 "QualityOfEstimate_Unknown" 2 "QualityOfEstimate_Low" 3 "QualityOfEstimate_Medium" 4 "QualityOfEstimate_High" 5 "QualityOfEstimate_Full";
VAL_ 512 VehicleMotionStateAngularVelocityYawQuality 0 "QualityOfEstimate_Error" 1 "QualityOfEstimate_Unknown" 2 "QualityOfEstimate_Low" 3 "QualityOfEstimate_Medium" 4 "QualityOfEstimate_High" 5 "QualityOfEstimate_Full";
VAL_ 512 VehicleMotionStateMovingDirection 0 "MovingDirection_Unknown" 1 "MovingDirection_Standstill" 2 "MovingDirection_NotStandstill" 3 "MovingDirection_Reverse" 4 "MovingDirection_Forward";
VAL_ 512 VehicleMotionStateMovingDirectionQuality 0 "QualityOfEstimate_Error" 1 "QualityOfEstimate_Unknown" 2 "QualityOfEstimate_Low" 3 "QualityOfEstimate_Medium" 4 "QualityOfEstimate_High" 5 "QualityOfEstimate_Full";
VAL_ 512 VehicleMotionStateVelocityLongitudinalQuality 0 "QualityOfEstimate_Error" 1 "QualityOfEstimate_Unknown" 2 "QualityOfEstimate_Low" 3 "QualityOfEstimate_Medium" 4 "QualityOfEstimate_High" 5 "QualityOfEstimate_Full";
VAL_ 512 VehicleMotionStateWheelAngleQuality 0 "QualityOfEstimate_Error" 1 "QualityOfEstimate_Unknown" 2 "QualityOfEstimate_Low" 3 "QualityOfEstimate_Medium" 4 "QualityOfEstimate_High" 5 "QualityOfEstimate_Full";
VAL_ 512 VehicleMotionStateWheelAngularVelocityFrontLeftQuality 0 "QualityOfEstimate_Error" 1 "QualityOfEstimate_Unknown" 2 "QualityOfEstimate_Low" 3 "QualityOfEstimate_Medium" 4 "QualityOfEstimate_High" 5 "QualityOfEstimate_Full";
VAL_ 512 VehicleMotionStateWheelAngularVelocityFrontRightQuality 0 "QualityOfEstimate_Error" 1 "QualityOfEstimate_Unknown" 2 "QualityOfEstimate_Low" 3 "QualityOfEstimate_Medium" 4 "QualityOfEstimate_High" 5 "QualityOfEstimate_Full";
VAL_ 512 VehicleMotionStateWheelAngularVelocityRearLeftQuality 0 "QualityOfEstimate_Error" 1 "QualityOfEstimate_Unknown" 2 "QualityOfEstimate_Low" 3 "QualityOfEstimate_Medium" 4 "QualityOfEstimate_High" 5 "QualityOfEstimate_Full";
VAL_ 512 VehicleMotionStateWheelAngularVelocityRearRightQuality 0 "QualityOfEstimate_Error" 1 "QualityOfEstimate_Unknown" 2 "QualityOfEstimate_Low" 3 "QualityOfEstimate_Medium" 4 "QualityOfEstimate_High" 5 "QualityOfEstimate_Full";
VAL_ 528 CarConfigPropulsionType 0 "PropulsionTyp_Unknown" 1 "PropulsionTyp_BatteryElectricVehicle" 2 "PropulsionTyp_HybridVehicle";
VAL_ 528 CarConfigVehicleTyp 0 "VehicleTyp_Unknown" 1 "VehicleTyp_P519" 2 "VehicleTyp_V536" 4 "VehicleTyp_P61A" 5 "VehicleTyp_V551";
VAL_ 528 PowerModeFLRRdrActvnReq 0 "RdrActvnReq_Off" 1 "RdrActvnReq_On";
VAL_ 528 PowerModeFLRRdrPwrlossNoti 0 "RdrPwrlossNoti_NoPwrLoss" 1 "RdrPwrlossNoti_PwrLoss";
VAL_ 560 VehicleModesProviderCarModSts 0 "RdrCarModSts_Normal" 1 "RdrCarModSts_Transport" 2 "RdrCarModSts_Factory" 3 "RdrCarModSts_Dyno" 4 "RdrCarModSts_Show" 5 "RdrCarModSts_Crash";
VAL_ 560 VehicleModesProviderCarModSubtypWd 0 "CarModSubtypWd_Normal" 1 "CarModSubtypWd_FactoryPaused" 2 "CarModSubtypWd_FactoryDriving" 3 "CarModSubtypWd_TransportDriving" 4 "CarModSubtypWd_TwoWheelDyno" 5 "CarModSubtypWd_FourWheelDyno";
VAL_ 560 VehicleModesProviderUsageModeAvailable 0 "UsgMod_False" 1 "UsgMod_True";
VAL_ 560 VehicleModesProviderUsageModeAwake 0 "UsgMod_False" 1 "UsgMod_True";
VAL_ 560 VehicleModesProviderUsageModeConvenience 0 "UsgMod_False" 1 "UsgMod_True";
VAL_ 560 VehicleModesProviderUsageModeDriving 0 "UsgMod_False" 1 "UsgMod_True";
VAL_ 560 VehicleModesProviderUsageModeMovable 0 "UsgMod_False" 1 "UsgMod_True";
VAL_ 560 VehicleModesProviderUsageModeResponsive 0 "UsgMod_False" 1 "UsgMod_True";
VAL_ 576 FuncInfoAntilockBrakingSystemState 0 "AbsState_disable" 1 "AbsState_enable";
VAL_ 576 FuncInfoBrkTracCtrlActv 0 "BrkTracCtrlActv_inactive" 1 "BrkTracCtrlActv_active";
VAL_ 80 FLR2RdrDetn000To004Mode0 0 "FLR2RadrDetnMode_RngNearReslMod" 1 "FLR2RadrDetnMode_RngMidReslMod" 2 "FLR2RadrDetnMode_RngLongReslMod" 3 "FLR2RadrDetnMode_DetectionUnpopulated";
VAL_ 80 FLR2RdrDetn000To004Mode1 0 "FLR2RadrDetnMode_RngNearReslMod" 1 "FLR2RadrDetnMode_RngMidReslMod" 2 "FLR2RadrDetnMode_RngLongReslMod" 3 "FLR2RadrDetnMode_DetectionUnpopulated";
VAL_ 80 FLR2RdrDetn000To004Mode2 0 "FLR2RadrDetnMode_RngNearReslMod" 1 "FLR2RadrDetnMode_RngMidReslMod" 2 "FLR2RadrDetnMode_RngLongReslMod" 3 "FLR2RadrDetnMode_DetectionUnpopulated";
VAL_ 80 FLR2RdrDetn000To004Mode3 0 "FLR2RadrDetnMode_RngNearReslMod" 1 "FLR2RadrDetnMode_RngMidReslMod" 2 "FLR2RadrDetnMode_RngLongReslMod" 3 "FLR2RadrDetnMode_DetectionUnpopulated";
VAL_ 80 FLR2RdrDetn000To004Mode4 0 "FLR2RadrDetnMode_RngNearReslMod" 1 "FLR2RadrDetnMode_RngMidReslMod" 2 "FLR2RadrDetnMode_RngLongReslMod" 3 "FLR2RadrDetnMode_DetectionUnpopulated";
VAL_ 80 FLR2RdrDetn000To004Quality0 0 "Quality_Low" 1 "Quality_Medium" 2 "Quality_High" 3 "Quality_DetectionUnpopulated";
VAL_ 80 FLR2RdrDetn000To004Quality1 0 "Quality_Low" 1 "Quality_Medium" 2 "Quality_High" 3 "Quality_DetectionUnpopulated";
VAL_ 80 FLR2RdrDetn000To004Quality2 0 "Quality_Low" 1 "Quality_Medium" 2 "Quality_High" 3 "Quality_DetectionUnpopulated";
VAL_ 80 FLR2RdrDetn000To004Quality3 0 "Quality_Low" 1 "Quality_Medium" 2 "Quality_High" 3 "Quality_DetectionUnpopulated";
VAL_ 80 FLR2RdrDetn000To004Quality4 0 "Quality_Low" 1 "Quality_Medium" 2 "Quality_High" 3 "Quality_DetectionUnpopulated";
VAL_ 83 FLR2RdrDetn005To009Mode0 0 "FLR2RadrDetnMode_RngNearReslMod" 1 "FLR2RadrDetnMode_RngMidReslMod" 2 "FLR2RadrDetnMode_RngLongReslMod" 3 "FLR2RadrDetnMode_DetectionUnpopulated";
VAL_ 83 FLR2RdrDetn005To009Mode1 0 "FLR2RadrDetnMode_RngNearReslMod" 1 "FLR2RadrDetnMode_RngMidReslMod" 2 "FLR2RadrDetnMode_RngLongReslMod" 3 "FLR2RadrDetnMode_DetectionUnpopulated";
VAL_ 83 FLR2RdrDetn005To009Mode2 0 "FLR2RadrDetnMode_RngNearReslMod" 1 "FLR2RadrDetnMode_RngMidReslMod" 2 "FLR2RadrDetnMode_RngLongReslMod" 3 "FLR2RadrDetnMode_DetectionUnpopulated";
VAL_ 83 FLR2RdrDetn005To009Mode3 0 "FLR2RadrDetnMode_RngNearReslMod" 1 "FLR2RadrDetnMode_RngMidReslMod" 2 "FLR2RadrDetnMode_RngLongReslMod" 3 "FLR2RadrDetnMode_DetectionUnpopulated";
VAL_ 83 FLR2RdrDetn005To009Mode4 0 "FLR2RadrDetnMode_RngNearReslMod" 1 "FLR2RadrDetnMode_RngMidReslMod" 2 "FLR2RadrDetnMode_RngLongReslMod" 3 "FLR2RadrDetnMode_DetectionUnpopulated";
VAL_ 83 FLR2RdrDetn005To009Quality0 0 "Quality_Low" 1 "Quality_Medium" 2 "Quality_High" 3 "Quality_DetectionUnpopulated";
VAL_ 83 FLR2RdrDetn005To009Quality1 0 "Quality_Low" 1 "Quality_Medium" 2 "Quality_High" 3 "Quality_DetectionUnpopulated";
VAL_ 83 FLR2RdrDetn005To009Quality2 0 "Quality_Low" 1 "Quality_Medium" 2 "Quality_High" 3 "Quality_DetectionUnpopulated";
VAL_ 83 FLR2RdrDetn005To009Quality3 0 "Quality_Low" 1 "Quality_Medium" 2 "Quality_High" 3 "Quality_DetectionUnpopulated";
VAL_ 83 FLR2RdrDetn005To009Quality4 0 "Quality_Low" 1 "Quality_Medium" 2 "Quality_High" 3 "Quality_DetectionUnpopulated";
VAL_ 86 FLR2RdrDetn010To014Mode0 0 "FLR2RadrDetnMode_RngNearReslMod" 1 "FLR2RadrDetnMode_RngMidReslMod" 2 "FLR2RadrDetnMode_RngLongReslMod" 3 "FLR2RadrDetnMode_DetectionUnpopulated";
VAL_ 86 FLR2RdrDetn010To014Mode1 0 "FLR2RadrDetnMode_RngNearReslMod" 1 "FLR2RadrDetnMode_RngMidReslMod" 2 "FLR2RadrDetnMode_RngLongReslMod" 3 "FLR2RadrDetnMode_DetectionUnpopulated";
VAL_ 86 FLR2RdrDetn010To014Mode2 0 "FLR2RadrDetnMode_RngNearReslMod" 1 "FLR2RadrDetnMode_RngMidReslMod" 2 "FLR2RadrDetnMode_RngLongReslMod" 3 "FLR2RadrDetnMode_DetectionUnpopulated";
VAL_ 86 FLR2RdrDetn010To014Mode3 0 "FLR2RadrDetnMode_RngNearReslMod" 1 "FLR2RadrDetnMode_RngMidReslMod" 2 "FLR2RadrDetnMode_RngLongReslMod" 3 "FLR2RadrDetnMode_DetectionUnpopulated";
VAL_ 86 FLR2RdrDetn010To014Mode4 0 "FLR2RadrDetnMode_RngNearReslMod" 1 "FLR2RadrDetnMode_RngMidReslMod" 2 "FLR2RadrDetnMode_RngLongReslMod" 3 "FLR2RadrDetnMode_DetectionUnpopulated";
VAL_ 86 FLR2RdrDetn010To014Quality0 0 "Quality_Low" 1 "Quality_Medium" 2 "Quality_High" 3 "Quality_DetectionUnpopulated";
VAL_ 86 FLR2RdrDetn010To014Quality1 0 "Quality_Low" 1 "Quality_Medium" 2 "Quality_High" 3 "Quality_DetectionUnpopulated";
VAL_ 86 FLR2RdrDetn010To014Quality2 0 "Quality_Low" 1 "Quality_Medium" 2 "Quality_High" 3 "Quality_DetectionUnpopulated";
VAL_ 86 FLR2RdrDetn010To014Quality3 0 "Quality_Low" 1 "Quality_Medium" 2 "Quality_High" 3 "Quality_DetectionUnpopulated";
VAL_ 86 FLR2RdrDetn010To014Quality4 0 "Quality_Low" 1 "Quality_Medium" 2 "Quality_High" 3 "Quality_DetectionUnpopulated";
VAL_ 89 FLR2RdrDetn015To019Mode0 0 "FLR2RadrDetnMode_RngNearReslMod" 1 "FLR2RadrDetnMode_RngMidReslMod" 2 "FLR2RadrDetnMode_RngLongReslMod" 3 "FLR2RadrDetnMode_DetectionUnpopulated";
VAL_ 89 FLR2RdrDetn015To019Mode1 0 "FLR2RadrDetnMode_RngNearReslMod" 1 "FLR2RadrDetnMode_RngMidReslMod" 2 "FLR2RadrDetnMode_RngLongReslMod" 3 "FLR2RadrDetnMode_DetectionUnpopulated";
VAL_ 89 FLR2RdrDetn015To019Mode2 0 "FLR2RadrDetnMode_RngNearReslMod" 1 "FLR2RadrDetnMode_RngMidReslMod" 2 "FLR2RadrDetnMode_RngLongReslMod" 3 "FLR2RadrDetnMode_DetectionUnpopulated";
VAL_ 89 FLR2RdrDetn015To019Mode3 0 "FLR2RadrDetnMode_RngNearReslMod" 1 "FLR2RadrDetnMode_RngMidReslMod" 2 "FLR2RadrDetnMode_RngLongReslMod" 3 "FLR2RadrDetnMode_DetectionUnpopulated";
VAL_ 89 FLR2RdrDetn015To019Mode4 0 "FLR2RadrDetnMode_RngNearReslMod" 1 "FLR2RadrDetnMode_RngMidReslMod" 2 "FLR2RadrDetnMode_RngLongReslMod" 3 "FLR2RadrDetnMode_DetectionUnpopulated";
VAL_ 89 FLR2RdrDetn015To019Quality0 0 "Quality_Low" 1 "Quality_Medium" 2 "Quality_High" 3 "Quality_DetectionUnpopulated";
VAL_ 89 FLR2RdrDetn015To019Quality1 0 "Quality_Low" 1 "Quality_Medium" 2 "Quality_High" 3 "Quality_DetectionUnpopulated";
VAL_ 89 FLR2RdrDetn015To019Quality2 0 "Quality_Low" 1 "Quality_Medium" 2 "Quality_High" 3 "Quality_DetectionUnpopulated";
VAL_ 89 FLR2RdrDetn015To019Quality3 0 "Quality_Low" 1 "Quality_Medium" 2 "Quality_High" 3 "Quality_DetectionUnpopulated";
VAL_ 89 FLR2RdrDetn015To019Quality4 0 "Quality_Low" 1 "Quality_Medium" 2 "Quality_High" 3 "Quality_DetectionUnpopulated";
VAL_ 92 FLR2RdrDetn020To024Mode0 0 "FLR2RadrDetnMode_RngNearReslMod" 1 "FLR2RadrDetnMode_RngMidReslMod" 2 "FLR2RadrDetnMode_RngLongReslMod" 3 "FLR2RadrDetnMode_DetectionUnpopulated";
VAL_ 92 FLR2RdrDetn020To024Mode1 0 "FLR2RadrDetnMode_RngNearReslMod" 1 "FLR2RadrDetnMode_RngMidReslMod" 2 "FLR2RadrDetnMode_RngLongReslMod" 3 "FLR2RadrDetnMode_DetectionUnpopulated";
VAL_ 92 FLR2RdrDetn020To024Mode2 0 "FLR2RadrDetnMode_RngNearReslMod" 1 "FLR2RadrDetnMode_RngMidReslMod" 2 "FLR2RadrDetnMode_RngLongReslMod" 3 "FLR2RadrDetnMode_DetectionUnpopulated";
VAL_ 92 FLR2RdrDetn020To024Mode3 0 "FLR2RadrDetnMode_RngNearReslMod" 1 "FLR2RadrDetnMode_RngMidReslMod" 2 "FLR2RadrDetnMode_RngLongReslMod" 3 "FLR2RadrDetnMode_DetectionUnpopulated";
VAL_ 92 FLR2RdrDetn020To024Mode4 0 "FLR2RadrDetnMode_RngNearReslMod" 1 "FLR2RadrDetnMode_RngMidReslMod" 2 "FLR2RadrDetnMode_RngLongReslMod" 3 "FLR2RadrDetnMode_DetectionUnpopulated";
VAL_ 92 FLR2RdrDetn020To024Quality0 0 "Quality_Low" 1 "Quality_Medium" 2 "Quality_High" 3 "Quality_DetectionUnpopulated";
VAL_ 92 FLR2RdrDetn020To024Quality1 0 "Quality_Low" 1 "Quality_Medium" 2 "Quality_High" 3 "Quality_DetectionUnpopulated";
VAL_ 92 FLR2RdrDetn020To024Quality2 0 "Quality_Low" 1 "Quality_Medium" 2 "Quality_High" 3 "Quality_DetectionUnpopulated";
VAL_ 92 FLR2RdrDetn020To024Quality3 0 "Quality_Low" 1 "Quality_Medium" 2 "Quality_High" 3 "Quality_DetectionUnpopulated";
VAL_ 92 FLR2RdrDetn020To024Quality4 0 "Quality_Low" 1 "Quality_Medium" 2 "Quality_High" 3 "Quality_DetectionUnpopulated";
VAL_ 96 FLR2RdrDetn025To029Mode0 0 "FLR2RadrDetnMode_RngNearReslMod" 1 "FLR2RadrDetnMode_RngMidReslMod" 2 "FLR2RadrDetnMode_RngLongReslMod" 3 "FLR2RadrDetnMode_DetectionUnpopulated";
VAL_ 96 FLR2RdrDetn025To029Mode1 0 "FLR2RadrDetnMode_RngNearReslMod" 1 "FLR2RadrDetnMode_RngMidReslMod" 2 "FLR2RadrDetnMode_RngLongReslMod" 3 "FLR2RadrDetnMode_DetectionUnpopulated";
VAL_ 96 FLR2RdrDetn025To029Mode2 0 "FLR2RadrDetnMode_RngNearReslMod" 1 "FLR2RadrDetnMode_RngMidReslMod" 2 "FLR2RadrDetnMode_RngLongReslMod" 3 "FLR2RadrDetnMode_DetectionUnpopulated";
VAL_ 96 FLR2RdrDetn025To029Mode3 0 "FLR2RadrDetnMode_RngNearReslMod" 1 "FLR2RadrDetnMode_RngMidReslMod" 2 "FLR2RadrDetnMode_RngLongReslMod" 3 "FLR2RadrDetnMode_DetectionUnpopulated";
VAL_ 96 FLR2RdrDetn025To029Mode4 0 "FLR2RadrDetnMode_RngNearReslMod" 1 "FLR2RadrDetnMode_RngMidReslMod" 2 "FLR2RadrDetnMode_RngLongReslMod" 3 "FLR2RadrDetnMode_DetectionUnpopulated";
VAL_ 96 FLR2RdrDetn025To029Quality0 0 "Quality_Low" 1 "Quality_Medium" 2 "Quality_High" 3 "Quality_DetectionUnpopulated";
VAL_ 96 FLR2RdrDetn025To029Quality1 0 "Quality_Low" 1 "Quality_Medium" 2 "Quality_High" 3 "Quality_DetectionUnpopulated";
VAL_ 96 FLR2RdrDetn025To029Quality2 0 "Quality_Low" 1 "Quality_Medium" 2 "Quality_High" 3 "Quality_DetectionUnpopulated";
VAL_ 96 FLR2RdrDetn025To029Quality3 0 "Quality_Low" 1 "Quality_Medium" 2 "Quality_High" 3 "Quality_DetectionUnpopulated";
VAL_ 96 FLR2RdrDetn025To029Quality4 0 "Quality_Low" 1 "Quality_Medium" 2 "Quality_High" 3 "Quality_DetectionUnpopulated";
VAL_ 99 FLR2RdrDetn030To034Mode0 0 "FLR2RadrDetnMode_RngNearReslMod" 1 "FLR2RadrDetnMode_RngMidReslMod" 2 "FLR2RadrDetnMode_RngLongReslMod" 3 "FLR2RadrDetnMode_DetectionUnpopulated";
VAL_ 99 FLR2RdrDetn030To034Mode1 0 "FLR2RadrDetnMode_RngNearReslMod" 1 "FLR2RadrDetnMode_RngMidReslMod" 2 "FLR2RadrDetnMode_RngLongReslMod" 3 "FLR2RadrDetnMode_DetectionUnpopulated";
VAL_ 99 FLR2RdrDetn030To034Mode2 0 "FLR2RadrDetnMode_RngNearReslMod" 1 "FLR2RadrDetnMode_RngMidReslMod" 2 "FLR2RadrDetnMode_RngLongReslMod" 3 "FLR2RadrDetnMode_DetectionUnpopulated";
VAL_ 99 FLR2RdrDetn030To034Mode3 0 "FLR2RadrDetnMode_RngNearReslMod" 1 "FLR2RadrDetnMode_RngMidReslMod" 2 "FLR2RadrDetnMode_RngLongReslMod" 3 "FLR2RadrDetnMode_DetectionUnpopulated";
VAL_ 99 FLR2RdrDetn030To034Mode4 0 "FLR2RadrDetnMode_RngNearReslMod" 1 "FLR2RadrDetnMode_RngMidReslMod" 2 "FLR2RadrDetnMode_RngLongReslMod" 3 "FLR2RadrDetnMode_DetectionUnpopulated";
VAL_ 99 FLR2RdrDetn030To034Quality0 0 "Quality_Low" 1 "Quality_Medium" 2 "Quality_High" 3 "Quality_DetectionUnpopulated";
VAL_ 99 FLR2RdrDetn030To034Quality1 0 "Quality_Low" 1 "Quality_Medium" 2 "Quality_High" 3 "Quality_DetectionUnpopulated";
VAL_ 99 FLR2RdrDetn030To034Quality2 0 "Quality_Low" 1 "Quality_Medium" 2 "Quality_High" 3 "Quality_DetectionUnpopulated";
VAL_ 99 FLR2RdrDetn030To034Quality3 0 "Quality_Low" 1 "Quality_Medium" 2 "Quality_High" 3 "Quality_DetectionUnpopulated";
VAL_ 99 FLR2RdrDetn030To034Quality4 0 "Quality_Low" 1 "Quality_Medium" 2 "Quality_High" 3 "Quality_DetectionUnpopulated";
VAL_ 102 FLR2RdrDetn035To039Mode0 0 "FLR2RadrDetnMode_RngNearReslMod" 1 "FLR2RadrDetnMode_RngMidReslMod" 2 "FLR2RadrDetnMode_RngLongReslMod" 3 "FLR2RadrDetnMode_DetectionUnpopulated";
VAL_ 102 FLR2RdrDetn035To039Mode1 0 "FLR2RadrDetnMode_RngNearReslMod" 1 "FLR2RadrDetnMode_RngMidReslMod" 2 "FLR2RadrDetnMode_RngLongReslMod" 3 "FLR2RadrDetnMode_DetectionUnpopulated";
VAL_ 102 FLR2RdrDetn035To039Mode2 0 "FLR2RadrDetnMode_RngNearReslMod" 1 "FLR2RadrDetnMode_RngMidReslMod" 2 "FLR2RadrDetnMode_RngLongReslMod" 3 "FLR2RadrDetnMode_DetectionUnpopulated";
VAL_ 102 FLR2RdrDetn035To039Mode3 0 "FLR2RadrDetnMode_RngNearReslMod" 1 "FLR2RadrDetnMode_RngMidReslMod" 2 "FLR2RadrDetnMode_RngLongReslMod" 3 "FLR2RadrDetnMode_DetectionUnpopulated";
VAL_ 102 FLR2RdrDetn035To039Mode4 0 "FLR2RadrDetnMode_RngNearReslMod" 1 "FLR2RadrDetnMode_RngMidReslMod" 2 "FLR2RadrDetnMode_RngLongReslMod" 3 "FLR2RadrDetnMode_DetectionUnpopulated";
VAL_ 102 FLR2RdrDetn035To039Quality0 0 "Quality_Low" 1 "Quality_Medium" 2 "Quality_High" 3 "Quality_DetectionUnpopulated";
VAL_ 102 FLR2RdrDetn035To039Quality1 0 "Quality_Low" 1 "Quality_Medium" 2 "Quality_High" 3 "Quality_DetectionUnpopulated";
VAL_ 102 FLR2RdrDetn035To039Quality2 0 "Quality_Low" 1 "Quality_Medium" 2 "Quality_High" 3 "Quality_DetectionUnpopulated";
VAL_ 102 FLR2RdrDetn035To039Quality3 0 "Quality_Low" 1 "Quality_Medium" 2 "Quality_High" 3 "Quality_DetectionUnpopulated";
VAL_ 102 FLR2RdrDetn035To039Quality4 0 "Quality_Low" 1 "Quality_Medium" 2 "Quality_High" 3 "Quality_DetectionUnpopulated";
VAL_ 105 FLR2RdrDetn040To044Mode0 0 "FLR2RadrDetnMode_RngNearReslMod" 1 "FLR2RadrDetnMode_RngMidReslMod" 2 "FLR2RadrDetnMode_RngLongReslMod" 3 "FLR2RadrDetnMode_DetectionUnpopulated";
VAL_ 105 FLR2RdrDetn040To044Mode1 0 "FLR2RadrDetnMode_RngNearReslMod" 1 "FLR2RadrDetnMode_RngMidReslMod" 2 "FLR2RadrDetnMode_RngLongReslMod" 3 "FLR2RadrDetnMode_DetectionUnpopulated";
VAL_ 105 FLR2RdrDetn040To044Mode2 0 "FLR2RadrDetnMode_RngNearReslMod" 1 "FLR2RadrDetnMode_RngMidReslMod" 2 "FLR2RadrDetnMode_RngLongReslMod" 3 "FLR2RadrDetnMode_DetectionUnpopulated";
VAL_ 105 FLR2RdrDetn040To044Mode3 0 "FLR2RadrDetnMode_RngNearReslMod" 1 "FLR2RadrDetnMode_RngMidReslMod" 2 "FLR2RadrDetnMode_RngLongReslMod" 3 "FLR2RadrDetnMode_DetectionUnpopulated";
VAL_ 105 FLR2RdrDetn040To044Mode4 0 "FLR2RadrDetnMode_RngNearReslMod" 1 "FLR2RadrDetnMode_RngMidReslMod" 2 "FLR2RadrDetnMode_RngLongReslMod" 3 "FLR2RadrDetnMode_DetectionUnpopulated";
VAL_ 105 FLR2RdrDetn040To044Quality0 0 "Quality_Low" 1 "Quality_Medium" 2 "Quality_High" 3 "Quality_DetectionUnpopulated";
VAL_ 105 FLR2RdrDetn040To044Quality1 0 "Quality_Low" 1 "Quality_Medium" 2 "Quality_High" 3 "Quality_DetectionUnpopulated";
VAL_ 105 FLR2RdrDetn040To044Quality2 0 "Quality_Low" 1 "Quality_Medium" 2 "Quality_High" 3 "Quality_DetectionUnpopulated";
VAL_ 105 FLR2RdrDetn040To044Quality3 0 "Quality_Low" 1 "Quality_Medium" 2 "Quality_High" 3 "Quality_DetectionUnpopulated";
VAL_ 105 FLR2RdrDetn040To044Quality4 0 "Quality_Low" 1 "Quality_Medium" 2 "Quality_High" 3 "Quality_DetectionUnpopulated";
VAL_ 108 FLR2RdrDetn045To049Mode0 0 "FLR2RadrDetnMode_RngNearReslMod" 1 "FLR2RadrDetnMode_RngMidReslMod" 2 "FLR2RadrDetnMode_RngLongReslMod" 3 "FLR2RadrDetnMode_DetectionUnpopulated";
VAL_ 108 FLR2RdrDetn045To049Mode1 0 "FLR2RadrDetnMode_RngNearReslMod" 1 "FLR2RadrDetnMode_RngMidReslMod" 2 "FLR2RadrDetnMode_RngLongReslMod" 3 "FLR2RadrDetnMode_DetectionUnpopulated";
VAL_ 108 FLR2RdrDetn045To049Mode2 0 "FLR2RadrDetnMode_RngNearReslMod" 1 "FLR2RadrDetnMode_RngMidReslMod" 2 "FLR2RadrDetnMode_RngLongReslMod" 3 "FLR2RadrDetnMode_DetectionUnpopulated";
VAL_ 108 FLR2RdrDetn045To049Mode3 0 "FLR2RadrDetnMode_RngNearReslMod" 1 "FLR2RadrDetnMode_RngMidReslMod" 2 "FLR2RadrDetnMode_RngLongReslMod" 3 "FLR2RadrDetnMode_DetectionUnpopulated";
VAL_ 108 FLR2RdrDetn045To049Mode4 0 "FLR2RadrDetnMode_RngNearReslMod" 1 "FLR2RadrDetnMode_RngMidReslMod" 2 "FLR2RadrDetnMode_RngLongReslMod" 3 "FLR2RadrDetnMode_DetectionUnpopulated";
VAL_ 108 FLR2RdrDetn045To049Quality0 0 "Quality_Low" 1 "Quality_Medium" 2 "Quality_High" 3 "Quality_DetectionUnpopulated";
VAL_ 108 FLR2RdrDetn045To049Quality1 0 "Quality_Low" 1 "Quality_Medium" 2 "Quality_High" 3 "Quality_DetectionUnpopulated";
VAL_ 108 FLR2RdrDetn045To049Quality2 0 "Quality_Low" 1 "Quality_Medium" 2 "Quality_High" 3 "Quality_DetectionUnpopulated";
VAL_ 108 FLR2RdrDetn045To049Quality3 0 "Quality_Low" 1 "Quality_Medium" 2 "Quality_High" 3 "Quality_DetectionUnpopulated";
VAL_ 108 FLR2RdrDetn045To049Quality4 0 "Quality_Low" 1 "Quality_Medium" 2 "Quality_High" 3 "Quality_DetectionUnpopulated";
VAL_ 112 FLR2RdrDetn050To054Mode0 0 "FLR2RadrDetnMode_RngNearReslMod" 1 "FLR2RadrDetnMode_RngMidReslMod" 2 "FLR2RadrDetnMode_RngLongReslMod" 3 "FLR2RadrDetnMode_DetectionUnpopulated";
VAL_ 112 FLR2RdrDetn050To054Mode1 0 "FLR2RadrDetnMode_RngNearReslMod" 1 "FLR2RadrDetnMode_RngMidReslMod" 2 "FLR2RadrDetnMode_RngLongReslMod" 3 "FLR2RadrDetnMode_DetectionUnpopulated";
VAL_ 112 FLR2RdrDetn050To054Mode2 0 "FLR2RadrDetnMode_RngNearReslMod" 1 "FLR2RadrDetnMode_RngMidReslMod" 2 "FLR2RadrDetnMode_RngLongReslMod" 3 "FLR2RadrDetnMode_DetectionUnpopulated";
VAL_ 112 FLR2RdrDetn050To054Mode3 0 "FLR2RadrDetnMode_RngNearReslMod" 1 "FLR2RadrDetnMode_RngMidReslMod" 2 "FLR2RadrDetnMode_RngLongReslMod" 3 "FLR2RadrDetnMode_DetectionUnpopulated";
VAL_ 112 FLR2RdrDetn050To054Mode4 0 "FLR2RadrDetnMode_RngNearReslMod" 1 "FLR2RadrDetnMode_RngMidReslMod" 2 "FLR2RadrDetnMode_RngLongReslMod" 3 "FLR2RadrDetnMode_DetectionUnpopulated";
VAL_ 112 FLR2RdrDetn050To054Quality0 0 "Quality_Low" 1 "Quality_Medium" 2 "Quality_High" 3 "Quality_DetectionUnpopulated";
VAL_ 112 FLR2RdrDetn050To054Quality1 0 "Quality_Low" 1 "Quality_Medium" 2 "Quality_High" 3 "Quality_DetectionUnpopulated";
VAL_ 112 FLR2RdrDetn050To054Quality2 0 "Quality_Low" 1 "Quality_Medium" 2 "Quality_High" 3 "Quality_DetectionUnpopulated";
VAL_ 112 FLR2RdrDetn050To054Quality3 0 "Quality_Low" 1 "Quality_Medium" 2 "Quality_High" 3 "Quality_DetectionUnpopulated";
VAL_ 112 FLR2RdrDetn050To054Quality4 0 "Quality_Low" 1 "Quality_Medium" 2 "Quality_High" 3 "Quality_DetectionUnpopulated";
VAL_ 115 FLR2RdrDetn055To059Mode0 0 "FLR2RadrDetnMode_RngNearReslMod" 1 "FLR2RadrDetnMode_RngMidReslMod" 2 "FLR2RadrDetnMode_RngLongReslMod" 3 "FLR2RadrDetnMode_DetectionUnpopulated";
VAL_ 115 FLR2RdrDetn055To059Mode1 0 "FLR2RadrDetnMode_RngNearReslMod" 1 "FLR2RadrDetnMode_RngMidReslMod" 2 "FLR2RadrDetnMode_RngLongReslMod" 3 "FLR2RadrDetnMode_DetectionUnpopulated";
VAL_ 115 FLR2RdrDetn055To059Mode2 0 "FLR2RadrDetnMode_RngNearReslMod" 1 "FLR2RadrDetnMode_RngMidReslMod" 2 "FLR2RadrDetnMode_RngLongReslMod" 3 "FLR2RadrDetnMode_DetectionUnpopulated";
VAL_ 115 FLR2RdrDetn055To059Mode3 0 "FLR2RadrDetnMode_RngNearReslMod" 1 "FLR2RadrDetnMode_RngMidReslMod" 2 "FLR2RadrDetnMode_RngLongReslMod" 3 "FLR2RadrDetnMode_DetectionUnpopulated";
VAL_ 115 FLR2RdrDetn055To059Mode4 0 "FLR2RadrDetnMode_RngNearReslMod" 1 "FLR2RadrDetnMode_RngMidReslMod" 2 "FLR2RadrDetnMode_RngLongReslMod" 3 "FLR2RadrDetnMode_DetectionUnpopulated";
VAL_ 115 FLR2RdrDetn055To059Quality0 0 "Quality_Low" 1 "Quality_Medium" 2 "Quality_High" 3 "Quality_DetectionUnpopulated";
VAL_ 115 FLR2RdrDetn055To059Quality1 0 "Quality_Low" 1 "Quality_Medium" 2 "Quality_High" 3 "Quality_DetectionUnpopulated";
VAL_ 115 FLR2RdrDetn055To059Quality2 0 "Quality_Low" 1 "Quality_Medium" 2 "Quality_High" 3 "Quality_DetectionUnpopulated";
VAL_ 115 FLR2RdrDetn055To059Quality3 0 "Quality_Low" 1 "Quality_Medium" 2 "Quality_High" 3 "Quality_DetectionUnpopulated";
VAL_ 115 FLR2RdrDetn055To059Quality4 0 "Quality_Low" 1 "Quality_Medium" 2 "Quality_High" 3 "Quality_DetectionUnpopulated";
SIG_GROUP_ 528 CarConfig 1 : CarConfigCounter CarConfigCRC CarConfigPropulsionType CarConfigVehicleTyp;
SIG_GROUP_ 80 FLR2RdrDetn000To004 1 : FLR2RdrDetn000To004AziAng0 FLR2RdrDetn000To004AziAng1 FLR2RdrDetn000To004AziAng2 FLR2RdrDetn000To004AziAng3 FLR2RdrDetn000To004AziAng4 FLR2RdrDetn000To004Counter FLR2RdrDetn000To004CRC FLR2RdrDetn000To004DynPrpty0 FLR2RdrDetn000To004DynPrpty1 FLR2RdrDetn000To004DynPrpty2 FLR2RdrDetn000To004DynPrpty3 FLR2RdrDetn000To004DynPrpty4 FLR2RdrDetn000To004EleAng0 FLR2RdrDetn000To004EleAng1 FLR2RdrDetn000To004EleAng2 FLR2RdrDetn000To004EleAng3 FLR2RdrDetn000To004EleAng4 FLR2RdrDetn000To004Mode0 FLR2RdrDetn000To004Mode1 FLR2RdrDetn000To004Mode2 FLR2RdrDetn000To004Mode3 FLR2RdrDetn000To004Mode4 FLR2RdrDetn000To004Quality0 FLR2RdrDetn000To004Quality1 FLR2RdrDetn000To004Quality2 FLR2RdrDetn000To004Quality3 FLR2RdrDetn000To004Quality4 FLR2RdrDetn000To004Range0 FLR2RdrDetn000To004Range1 FLR2RdrDetn000To004Range2 FLR2RdrDetn000To004Range3 FLR2RdrDetn000To004Range4 FLR2RdrDetn000To004RCS0 FLR2RdrDetn000To004RCS1 FLR2RdrDetn000To004RCS2 FLR2RdrDetn000To004RCS3 FLR2RdrDetn000To004RCS4 FLR2RdrDetn000To004RngRt0 FLR2RdrDetn000To004RngRt1 FLR2RdrDetn000To004RngRt2 FLR2RdrDetn000To004RngRt3 FLR2RdrDetn000To004RngRt4 FLR2RdrDetn000To004ScanID FLR2RdrDetn000To004SNR0 FLR2RdrDetn000To004SNR1 FLR2RdrDetn000To004SNR2 FLR2RdrDetn000To004SNR3 FLR2RdrDetn000To004SNR4;
SIG_GROUP_ 83 FLR2RdrDetn005To009 1 : FLR2RdrDetn005To009AziAng0 FLR2RdrDetn005To009AziAng1 FLR2RdrDetn005To009AziAng2 FLR2RdrDetn005To009AziAng3 FLR2RdrDetn005To009AziAng4 FLR2RdrDetn005To009Counter FLR2RdrDetn005To009CRC FLR2RdrDetn005To009DynPrpty0 FLR2RdrDetn005To009DynPrpty1 FLR2RdrDetn005To009DynPrpty2 FLR2RdrDetn005To009DynPrpty3 FLR2RdrDetn005To009DynPrpty4 FLR2RdrDetn005To009EleAng0 FLR2RdrDetn005To009EleAng1 FLR2RdrDetn005To009EleAng2 FLR2RdrDetn005To009EleAng3 FLR2RdrDetn005To009EleAng4 FLR2RdrDetn005To009Mode0 FLR2RdrDetn005To009Mode1 FLR2RdrDetn005To009Mode2 FLR2RdrDetn005To009Mode3 FLR2RdrDetn005To009Mode4 FLR2RdrDetn005To009Quality0 FLR2RdrDetn005To009Quality1 FLR2RdrDetn005To009Quality2 FLR2RdrDetn005To009Quality3 FLR2RdrDetn005To009Quality4 FLR2RdrDetn005To009Range0 FLR2RdrDetn005To009Range1 FLR2RdrDetn005To009Range2 FLR2RdrDetn005To009Range3 FLR2RdrDetn005To009Range4 FLR2RdrDetn005To009RCS0 FLR2RdrDetn005To009RCS1 FLR2RdrDetn005To009RCS2 FLR2RdrDetn005To009RCS3 FLR2RdrDetn005To009RCS4 FLR2RdrDetn005To009RngRt0 FLR2RdrDetn005To009RngRt1 FLR2RdrDetn005To009RngRt2 FLR2RdrDetn005To009RngRt3 FLR2RdrDetn005To009RngRt4 FLR2RdrDetn005To009ScanID FLR2RdrDetn005To009SNR0 FLR2RdrDetn005To009SNR1 FLR2RdrDetn005To009SNR2 FLR2RdrDetn005To009SNR3 FLR2RdrDetn005To009SNR4;
SIG_GROUP_ 86 FLR2RdrDetn010To014 1 : FLR2RdrDetn010To014AziAng0 FLR2RdrDetn010To014AziAng1 FLR2RdrDetn010To014AziAng2 FLR2RdrDetn010To014AziAng3 FLR2RdrDetn010To014AziAng4 FLR2RdrDetn010To014Counter FLR2RdrDetn010To014CRC FLR2RdrDetn010To014DynPrpty0 FLR2RdrDetn010To014DynPrpty1 FLR2RdrDetn010To014DynPrpty2 FLR2RdrDetn010To014DynPrpty3 FLR2RdrDetn010To014DynPrpty4 FLR2RdrDetn010To014EleAng0 FLR2RdrDetn010To014EleAng1 FLR2RdrDetn010To014EleAng2 FLR2RdrDetn010To014EleAng3 FLR2RdrDetn010To014EleAng4 FLR2RdrDetn010To014Mode0 FLR2RdrDetn010To014Mode1 FLR2RdrDetn010To014Mode2 FLR2RdrDetn010To014Mode3 FLR2RdrDetn010To014Mode4 FLR2RdrDetn010To014Quality0 FLR2RdrDetn010To014Quality1 FLR2RdrDetn010To014Quality2 FLR2RdrDetn010To014Quality3 FLR2RdrDetn010To014Quality4 FLR2RdrDetn010To014Range0 FLR2RdrDetn010To014Range1 FLR2RdrDetn010To014Range2 FLR2RdrDetn010To014Range3 FLR2RdrDetn010To014Range4 FLR2RdrDetn010To014RCS0 FLR2RdrDetn010To014RCS1 FLR2RdrDetn010To014RCS2 FLR2RdrDetn010To014RCS3 FLR2RdrDetn010To014RCS4 FLR2RdrDetn010To014RngRt0 FLR2RdrDetn010To014RngRt1 FLR2RdrDetn010To014RngRt2 FLR2RdrDetn010To014RngRt3 FLR2RdrDetn010To014RngRt4 FLR2RdrDetn010To014ScanID FLR2RdrDetn010To014SNR0 FLR2RdrDetn010To014SNR1 FLR2RdrDetn010To014SNR2 FLR2RdrDetn010To014SNR3 FLR2RdrDetn010To014SNR4;
SIG_GROUP_ 89 FLR2RdrDetn015To019 1 : FLR2RdrDetn015To019AziAng0 FLR2RdrDetn015To019AziAng1 FLR2RdrDetn015To019AziAng2 FLR2RdrDetn015To019AziAng3 FLR2RdrDetn015To019AziAng4 FLR2RdrDetn015To019Counter FLR2RdrDetn015To019CRC FLR2RdrDetn015To019DynPrpty0 FLR2RdrDetn015To019DynPrpty1 FLR2RdrDetn015To019DynPrpty2 FLR2RdrDetn015To019DynPrpty3 FLR2RdrDetn015To019DynPrpty4 FLR2RdrDetn015To019EleAng0 FLR2RdrDetn015To019EleAng1 FLR2RdrDetn015To019EleAng2 FLR2RdrDetn015To019EleAng3 FLR2RdrDetn015To019EleAng4 FLR2RdrDetn015To019Mode0 FLR2RdrDetn015To019Mode1 FLR2RdrDetn015To019Mode2 FLR2RdrDetn015To019Mode3 FLR2RdrDetn015To019Mode4 FLR2RdrDetn015To019Quality0 FLR2RdrDetn015To019Quality1 FLR2RdrDetn015To019Quality2 FLR2RdrDetn015To019Quality3 FLR2RdrDetn015To019Quality4 FLR2RdrDetn015To019Range0 FLR2RdrDetn015To019Range1 FLR2RdrDetn015To019Range2 FLR2RdrDetn015To019Range3 FLR2RdrDetn015To019Range4 FLR2RdrDetn015To019RCS0 FLR2RdrDetn015To019RCS1 FLR2RdrDetn015To019RCS2 FLR2RdrDetn015To019RCS3 FLR2RdrDetn015To019RCS4 FLR2RdrDetn015To019RngRt0 FLR2RdrDetn015To019RngRt1 FLR2RdrDetn015To019RngRt2 FLR2RdrDetn015To019RngRt3 FLR2RdrDetn015To019RngRt4 FLR2RdrDetn015To019ScanID FLR2RdrDetn015To019SNR0 FLR2RdrDetn015To019SNR1 FLR2RdrDetn015To019SNR2 FLR2RdrDetn015To019SNR3 FLR2RdrDetn015To019SNR4;
SIG_GROUP_ 92 FLR2RdrDetn020To024 1 : FLR2RdrDetn020To024AziAng0 FLR2RdrDetn020To024AziAng1 FLR2RdrDetn020To024AziAng2 FLR2RdrDetn020To024AziAng3 FLR2RdrDetn020To024AziAng4 FLR2RdrDetn020To024Counter FLR2RdrDetn020To024CRC FLR2RdrDetn020To024DynPrpty0 FLR2RdrDetn020To024DynPrpty1 FLR2RdrDetn020To024DynPrpty2 FLR2RdrDetn020To024DynPrpty3 FLR2RdrDetn020To024DynPrpty4 FLR2RdrDetn020To024EleAng0 FLR2RdrDetn020To024EleAng1 FLR2RdrDetn020To024EleAng2 FLR2RdrDetn020To024EleAng3 FLR2RdrDetn020To024EleAng4 FLR2RdrDetn020To024Mode0 FLR2RdrDetn020To024Mode1 FLR2RdrDetn020To024Mode2 FLR2RdrDetn020To024Mode3 FLR2RdrDetn020To024Mode4 FLR2RdrDetn020To024Quality0 FLR2RdrDetn020To024Quality1 FLR2RdrDetn020To024Quality2 FLR2RdrDetn020To024Quality3 FLR2RdrDetn020To024Quality4 FLR2RdrDetn020To024Range0 FLR2RdrDetn020To024Range1 FLR2RdrDetn020To024Range2 FLR2RdrDetn020To024Range3 FLR2RdrDetn020To024Range4 FLR2RdrDetn020To024RCS0 FLR2RdrDetn020To024RCS1 FLR2RdrDetn020To024RCS2 FLR2RdrDetn020To024RCS3 FLR2RdrDetn020To024RCS4 FLR2RdrDetn020To024RngRt0 FLR2RdrDetn020To024RngRt1 FLR2RdrDetn020To024RngRt2 FLR2RdrDetn020To024RngRt3 FLR2RdrDetn020To024RngRt4 FLR2RdrDetn020To024ScanID FLR2RdrDetn020To024SNR0 FLR2RdrDetn020To024SNR1 FLR2RdrDetn020To024SNR2 FLR2RdrDetn020To024SNR3 FLR2RdrDetn020To024SNR4;
SIG_GROUP_ 96 FLR2RdrDetn025To029 1 : FLR2RdrDetn025To029AziAng0 FLR2RdrDetn025To029AziAng1 FLR2RdrDetn025To029AziAng2 FLR2RdrDetn025To029AziAng3 FLR2RdrDetn025To029AziAng4 FLR2RdrDetn025To029Counter FLR2RdrDetn025To029CRC FLR2RdrDetn025To029DynPrpty0 FLR2RdrDetn025To029DynPrpty1 FLR2RdrDetn025To029DynPrpty2 FLR2RdrDetn025To029DynPrpty3 FLR2RdrDetn025To029DynPrpty4 FLR2RdrDetn025To029EleAng0 FLR2RdrDetn025To029EleAng1 FLR2RdrDetn025To029EleAng2 FLR2RdrDetn025To029EleAng3 FLR2RdrDetn025To029EleAng4 FLR2RdrDetn025To029Mode0 FLR2RdrDetn025To029Mode1 FLR2RdrDetn025To029Mode2 FLR2RdrDetn025To029Mode3 FLR2RdrDetn025To029Mode4 FLR2RdrDetn025To029Quality0 FLR2RdrDetn025To029Quality1 FLR2RdrDetn025To029Quality2 FLR2RdrDetn025To029Quality3 FLR2RdrDetn025To029Quality4 FLR2RdrDetn025To029Range0 FLR2RdrDetn025To029Range1 FLR2RdrDetn025To029Range2 FLR2RdrDetn025To029Range3 FLR2RdrDetn025To029Range4 FLR2RdrDetn025To029RCS0 FLR2RdrDetn025To029RCS1 FLR2RdrDetn025To029RCS2 FLR2RdrDetn025To029RCS3 FLR2RdrDetn025To029RCS4 FLR2RdrDetn025To029RngRt0 FLR2RdrDetn025To029RngRt1 FLR2RdrDetn025To029RngRt2 FLR2RdrDetn025To029RngRt3 FLR2RdrDetn025To029RngRt4 FLR2RdrDetn025To029ScanID FLR2RdrDetn025To029SNR0 FLR2RdrDetn025To029SNR1 FLR2RdrDetn025To029SNR2 FLR2RdrDetn025To029SNR3 FLR2RdrDetn025To029SNR4;
SIG_GROUP_ 99 FLR2RdrDetn030To034 1 : FLR2RdrDetn030To034AziAng0 FLR2RdrDetn030To034AziAng1 FLR2RdrDetn030To034AziAng2 FLR2RdrDetn030To034AziAng3 FLR2RdrDetn030To034AziAng4 FLR2RdrDetn030To034Counter FLR2RdrDetn030To034CRC FLR2RdrDetn030To034DynPrpty0 FLR2RdrDetn030To034DynPrpty1 FLR2RdrDetn030To034DynPrpty2 FLR2RdrDetn030To034DynPrpty3 FLR2RdrDetn030To034DynPrpty4 FLR2RdrDetn030To034EleAng0 FLR2RdrDetn030To034EleAng1 FLR2RdrDetn030To034EleAng2 FLR2RdrDetn030To034EleAng3 FLR2RdrDetn030To034EleAng4 FLR2RdrDetn030To034Mode0 FLR2RdrDetn030To034Mode1 FLR2RdrDetn030To034Mode2 FLR2RdrDetn030To034Mode3 FLR2RdrDetn030To034Mode4 FLR2RdrDetn030To034Quality0 FLR2RdrDetn030To034Quality1 FLR2RdrDetn030To034Quality2 FLR2RdrDetn030To034Quality3 FLR2RdrDetn030To034Quality4 FLR2RdrDetn030To034Range0 FLR2RdrDetn030To034Range1 FLR2RdrDetn030To034Range2 FLR2RdrDetn030To034Range3 FLR2RdrDetn030To034Range4 FLR2RdrDetn030To034RCS0 FLR2RdrDetn030To034RCS1 FLR2RdrDetn030To034RCS2 FLR2RdrDetn030To034RCS3 FLR2RdrDetn030To034RCS4 FLR2RdrDetn030To034RngRt0 FLR2RdrDetn030To034RngRt1 FLR2RdrDetn030To034RngRt2 FLR2RdrDetn030To034RngRt3 FLR2RdrDetn030To034RngRt4 FLR2RdrDetn030To034ScanID FLR2RdrDetn030To034SNR0 FLR2RdrDetn030To034SNR1 FLR2RdrDetn030To034SNR2 FLR2RdrDetn030To034SNR3 FLR2RdrDetn030To034SNR4;
SIG_GROUP_ 102 FLR2RdrDetn035To039 1 : FLR2RdrDetn035To039AziAng0 FLR2RdrDetn035To039AziAng1 FLR2RdrDetn035To039AziAng2 FLR2RdrDetn035To039AziAng3 FLR2RdrDetn035To039AziAng4 FLR2RdrDetn035To039Counter FLR2RdrDetn035To039CRC FLR2RdrDetn035To039DynPrpty0 FLR2RdrDetn035To039DynPrpty1 FLR2RdrDetn035To039DynPrpty2 FLR2RdrDetn035To039DynPrpty3 FLR2RdrDetn035To039DynPrpty4 FLR2RdrDetn035To039EleAng0 FLR2RdrDetn035To039EleAng1 FLR2RdrDetn035To039EleAng2 FLR2RdrDetn035To039EleAng3 FLR2RdrDetn035To039EleAng4 FLR2RdrDetn035To039Mode0 FLR2RdrDetn035To039Mode1 FLR2RdrDetn035To039Mode2 FLR2RdrDetn035To039Mode3 FLR2RdrDetn035To039Mode4 FLR2RdrDetn035To039Quality0 FLR2RdrDetn035To039Quality1 FLR2RdrDetn035To039Quality2 FLR2RdrDetn035To039Quality3 FLR2RdrDetn035To039Quality4 FLR2RdrDetn035To039Range0 FLR2RdrDetn035To039Range1 FLR2RdrDetn035To039Range2 FLR2RdrDetn035To039Range3 FLR2RdrDetn035To039Range4 FLR2RdrDetn035To039RCS0 FLR2RdrDetn035To039RCS1 FLR2RdrDetn035To039RCS2 FLR2RdrDetn035To039RCS3 FLR2RdrDetn035To039RCS4 FLR2RdrDetn035To039RngRt0 FLR2RdrDetn035To039RngRt1 FLR2RdrDetn035To039RngRt2 FLR2RdrDetn035To039RngRt3 FLR2RdrDetn035To039RngRt4 FLR2RdrDetn035To039ScanID FLR2RdrDetn035To039SNR0 FLR2RdrDetn035To039SNR1 FLR2RdrDetn035To039SNR2 FLR2RdrDetn035To039SNR3 FLR2RdrDetn035To039SNR4;
SIG_GROUP_ 105 FLR2RdrDetn040To044 1 : FLR2RdrDetn040To044AziAng0 FLR2RdrDetn040To044AziAng1 FLR2RdrDetn040To044AziAng2 FLR2RdrDetn040To044AziAng3 FLR2RdrDetn040To044AziAng4 FLR2RdrDetn040To044Counter FLR2RdrDetn040To044CRC FLR2RdrDetn040To044DynPrpty0 FLR2RdrDetn040To044DynPrpty1 FLR2RdrDetn040To044DynPrpty2 FLR2RdrDetn040To044DynPrpty3 FLR2RdrDetn040To044DynPrpty4 FLR2RdrDetn040To044EleAng0 FLR2RdrDetn040To044EleAng1 FLR2RdrDetn040To044EleAng2 FLR2RdrDetn040To044EleAng3 FLR2RdrDetn040To044EleAng4 FLR2RdrDetn040To044Mode0 FLR2RdrDetn040To044Mode1 FLR2RdrDetn040To044Mode2 FLR2RdrDetn040To044Mode3 FLR2RdrDetn040To044Mode4 FLR2RdrDetn040To044Quality0 FLR2RdrDetn040To044Quality1 FLR2RdrDetn040To044Quality2 FLR2RdrDetn040To044Quality3 FLR2RdrDetn040To044Quality4 FLR2RdrDetn040To044Range0 FLR2RdrDetn040To044Range1 FLR2RdrDetn040To044Range2 FLR2RdrDetn040To044Range3 FLR2RdrDetn040To044Range4 FLR2RdrDetn040To044RCS0 FLR2RdrDetn040To044RCS1 FLR2RdrDetn040To044RCS2 FLR2RdrDetn040To044RCS3 FLR2RdrDetn040To044RCS4 FLR2RdrDetn040To044RngRt0 FLR2RdrDetn040To044RngRt1 FLR2RdrDetn040To044RngRt2 FLR2RdrDetn040To044RngRt3 FLR2RdrDetn040To044RngRt4 FLR2RdrDetn040To044ScanID FLR2RdrDetn040To044SNR0 FLR2RdrDetn040To044SNR1 FLR2RdrDetn040To044SNR2 FLR2RdrDetn040To044SNR3 FLR2RdrDetn040To044SNR4;
SIG_GROUP_ 108 FLR2RdrDetn045To049 1 : FLR2RdrDetn045To049AziAng0 FLR2RdrDetn045To049AziAng1 FLR2RdrDetn045To049AziAng2 FLR2RdrDetn045To049AziAng3 FLR2RdrDetn045To049AziAng4 FLR2RdrDetn045To049Counter FLR2RdrDetn045To049CRC FLR2RdrDetn045To049DynPrpty0 FLR2RdrDetn045To049DynPrpty1 FLR2RdrDetn045To049DynPrpty2 FLR2RdrDetn045To049DynPrpty3 FLR2RdrDetn045To049DynPrpty4 FLR2RdrDetn045To049EleAng0 FLR2RdrDetn045To049EleAng1 FLR2RdrDetn045To049EleAng2 FLR2RdrDetn045To049EleAng3 FLR2RdrDetn045To049EleAng4 FLR2RdrDetn045To049Mode0 FLR2RdrDetn045To049Mode1 FLR2RdrDetn045To049Mode2 FLR2RdrDetn045To049Mode3 FLR2RdrDetn045To049Mode4 FLR2RdrDetn045To049Quality0 FLR2RdrDetn045To049Quality1 FLR2RdrDetn045To049Quality2 FLR2RdrDetn045To049Quality3 FLR2RdrDetn045To049Quality4 FLR2RdrDetn045To049Range0 FLR2RdrDetn045To049Range1 FLR2RdrDetn045To049Range2 FLR2RdrDetn045To049Range3 FLR2RdrDetn045To049Range4 FLR2RdrDetn045To049RCS0 FLR2RdrDetn045To049RCS1 FLR2RdrDetn045To049RCS2 FLR2RdrDetn045To049RCS3 FLR2RdrDetn045To049RCS4 FLR2RdrDetn045To049RngRt0 FLR2RdrDetn045To049RngRt1 FLR2RdrDetn045To049RngRt2 FLR2RdrDetn045To049RngRt3 FLR2RdrDetn045To049RngRt4 FLR2RdrDetn045To049ScanID FLR2RdrDetn045To049SNR0 FLR2RdrDetn045To049SNR1 FLR2RdrDetn045To049SNR2 FLR2RdrDetn045To049SNR3 FLR2RdrDetn045To049SNR4;
SIG_GROUP_ 112 FLR2RdrDetn050To054 1 : FLR2RdrDetn050To054AziAng0 FLR2RdrDetn050To054AziAng1 FLR2RdrDetn050To054AziAng2 FLR2RdrDetn050To054AziAng3 FLR2RdrDetn050To054AziAng4 FLR2RdrDetn050To054Counter FLR2RdrDetn050To054CRC FLR2RdrDetn050To054DynPrpty0 FLR2RdrDetn050To054DynPrpty1 FLR2RdrDetn050To054DynPrpty2 FLR2RdrDetn050To054DynPrpty3 FLR2RdrDetn050To054DynPrpty4 FLR2RdrDetn050To054EleAng0 FLR2RdrDetn050To054EleAng1 FLR2RdrDetn050To054EleAng2 FLR2RdrDetn050To054EleAng3 FLR2RdrDetn050To054EleAng4 FLR2RdrDetn050To054Mode0 FLR2RdrDetn050To054Mode1 FLR2RdrDetn050To054Mode2 FLR2RdrDetn050To054Mode3 FLR2RdrDetn050To054Mode4 FLR2RdrDetn050To054Quality0 FLR2RdrDetn050To054Quality1 FLR2RdrDetn050To054Quality2 FLR2RdrDetn050To054Quality3 FLR2RdrDetn050To054Quality4 FLR2RdrDetn050To054Range0 FLR2RdrDetn050To054Range1 FLR2RdrDetn050To054Range2 FLR2RdrDetn050To054Range3 FLR2RdrDetn050To054Range4 FLR2RdrDetn050To054RCS0 FLR2RdrDetn050To054RCS1 FLR2RdrDetn050To054RCS2 FLR2RdrDetn050To054RCS3 FLR2RdrDetn050To054RCS4 FLR2RdrDetn050To054RngRt0 FLR2RdrDetn050To054RngRt1 FLR2RdrDetn050To054RngRt2 FLR2RdrDetn050To054RngRt3 FLR2RdrDetn050To054RngRt4 FLR2RdrDetn050To054ScanID FLR2RdrDetn050To054SNR0 FLR2RdrDetn050To054SNR1 FLR2RdrDetn050To054SNR2 FLR2RdrDetn050To054SNR3 FLR2RdrDetn050To054SNR4;
SIG_GROUP_ 115 FLR2RdrDetn055To059 1 : FLR2RdrDetn055To059AziAng0 FLR2RdrDetn055To059AziAng1 FLR2RdrDetn055To059AziAng2 FLR2RdrDetn055To059AziAng3 FLR2RdrDetn055To059AziAng4 FLR2RdrDetn055To059Counter FLR2RdrDetn055To059CRC FLR2RdrDetn055To059DynPrpty0 FLR2RdrDetn055To059DynPrpty1 FLR2RdrDetn055To059DynPrpty2 FLR2RdrDetn055To059DynPrpty3 FLR2RdrDetn055To059DynPrpty4 FLR2RdrDetn055To059EleAng0 FLR2RdrDetn055To059EleAng1 FLR2RdrDetn055To059EleAng2 FLR2RdrDetn055To059EleAng3 FLR2RdrDetn055To059EleAng4 FLR2RdrDetn055To059Mode0 FLR2RdrDetn055To059Mode1 FLR2RdrDetn055To059Mode2 FLR2RdrDetn055To059Mode3 FLR2RdrDetn055To059Mode4 FLR2RdrDetn055To059Quality0 FLR2RdrDetn055To059Quality1 FLR2RdrDetn055To059Quality2 FLR2RdrDetn055To059Quality3 FLR2RdrDetn055To059Quality4 FLR2RdrDetn055To059Range0 FLR2RdrDetn055To059Range1 FLR2RdrDetn055To059Range2 FLR2RdrDetn055To059Range3 FLR2RdrDetn055To059Range4 FLR2RdrDetn055To059RCS0 FLR2RdrDetn055To059RCS1 FLR2RdrDetn055To059RCS2 FLR2RdrDetn055To059RCS3 FLR2RdrDetn055To059RCS4 FLR2RdrDetn055To059RngRt0 FLR2RdrDetn055To059RngRt1 FLR2RdrDetn055To059RngRt2 FLR2RdrDetn055To059RngRt3 FLR2RdrDetn055To059RngRt4 FLR2RdrDetn055To059ScanID FLR2RdrDetn055To059SNR0 FLR2RdrDetn055To059SNR1 FLR2RdrDetn055To059SNR2 FLR2RdrDetn055To059SNR3 FLR2RdrDetn055To059SNR4;
SIG_GROUP_ 576 FuncInfo 1 : FuncInfoAntilockBrakingSystemState FuncInfoBrkTracCtrlActv FuncInfoCounter FuncInfoCRC;
SIG_GROUP_ 544 GlobalSnapShotRdr 1 : GlobalSnapShotRdrCounter GlobalSnapShotRdrCRC GlobalSnapShotRdrGlobalRealTimeRdr GlobalSnapShotRdrOutsideTemperatureRdr GlobalSnapShotRdrTotalDistanceRdr GlobalSnapShotRdrUsageModeRdr GlobalSnapShotRdrVehicleBatteryVoltageRdr GlobalSnapShotRdrVehicleSpeedRdr;
SIG_GROUP_ 528 PowerModeFLR 1 : PowerModeFLRCounter PowerModeFLRCRC PowerModeFLRRdrActvnReq PowerModeFLRRdrPwrlossNoti;
SIG_GROUP_ 560 VehicleModesProvider 1 : VehicleModesProviderCarModSts VehicleModesProviderCarModSubtypWd VehicleModesProviderCounter VehicleModesProviderCRC VehicleModesProviderUsageModeAvailable VehicleModesProviderUsageModeAwake VehicleModesProviderUsageModeConvenience VehicleModesProviderUsageModeDriving VehicleModesProviderUsageModeMovable VehicleModesProviderUsageModeResponsive;
SIG_GROUP_ 512 VehicleMotionState 1 : VehicleMotionStateAcceleroMeterLateral VehicleMotionStateAccelerometerLateralQuality VehicleMotionStateAccelerometerLongitudinal VehicleMotionStateAccelerometerLongitudinalQuality VehicleMotionStateAccelerometerVertical VehicleMotionStateAccelerometerVerticalQuality VehicleMotionStateAngularVelocityRoll VehicleMotionStateAngularVelocityRollQuality VehicleMotionStateAngularVelocityYaw VehicleMotionStateAngularVelocityYawQuality VehicleMotionStateCounter VehicleMotionStateCRC VehicleMotionStateMovingDirection VehicleMotionStateMovingDirectionQuality VehicleMotionStateVelocityLongitudinal VehicleMotionStateVelocityLongitudinalQuality VehicleMotionStateWheelAngle VehicleMotionStateWheelAngleQuality VehicleMotionStateWheelAngularVelocityFrontLeft VehicleMotionStateWheelAngularVelocityFrontLeftQuality VehicleMotionStateWheelAngularVelocityFrontRight VehicleMotionStateWheelAngularVelocityFrontRightQuality VehicleMotionStateWheelAngularVelocityRearLeft VehicleMotionStateWheelAngularVelocityRearLeftQuality VehicleMotionStateWheelAngularVelocityRearRight VehicleMotionStateWheelAngularVelocityRearRightQuality;
